VERSION ""

NS_ :

BS_:

BU_:

BO_ 873 APP_warningMatrix1: 8 Vector__XXX
 SG_ APP_w106_torsionBarOffset : 41|1@1+ (1,0) [0|0] "" Vector__XXX
 SG_ APP_w105_DEPRECATED : 40|1@1+ (1,0) [0|0] "" Vector__XXX
 SG_ APP_w104_DEPRECATED : 39|1@1+ (1,0) [0|0] "" Vector__XXX
 SG_ APP_w103_robExperimentalAEB : 38|1@1+ (1,0) [0|0] "" Vector__XXX
 SG_ APP_w102_DEPRECATED : 37|1@1+ (1,0) [0|0] "" Vector__XXX
 SG_ APP_w101_DEPRECATED : 36|1@1+ (1,0) [0|0] "" Vector__XXX
 SG_ APP_w100_DEPRECATED : 35|1@1+ (1,0) [0|0] "" Vector__XXX
 SG_ APP_w099_DEPRECATED : 34|1@1+ (1,0) [0|0] "" Vector__XXX
 SG_ APP_w098_DEPRECATED : 33|1@1+ (1,0) [0|0] "" Vector__XXX
 SG_ APP_w097_DEPRECATED : 32|1@1+ (1,0) [0|0] "" Vector__XXX
 SG_ APP_w096_DEPRECATED : 31|1@1+ (1,0) [0|0] "" Vector__XXX
 SG_ APP_w095_DEPRECATED : 30|1@1+ (1,0) [0|0] "" Vector__XXX
 SG_ APP_w094_DEPRECATED : 29|1@1+ (1,0) [0|0] "" Vector__XXX
 SG_ APP_w093_DEPRECATED : 28|1@1+ (1,0) [0|0] "" Vector__XXX
 SG_ APP_w092_DEPRECATED : 27|1@1+ (1,0) [0|0] "" Vector__XXX
 SG_ APP_w091_DEPRECATED : 26|1@1+ (1,0) [0|0] "" Vector__XXX
 SG_ APP_w090_DEPRECATED : 25|1@1+ (1,0) [0|0] "" Vector__XXX
 SG_ APP_w089_DEPRECATED : 24|1@1+ (1,0) [0|0] "" Vector__XXX
 SG_ APP_w088_DEPRECATED : 23|1@1+ (1,0) [0|0] "" Vector__XXX
 SG_ APP_w087_DEPRECATED : 22|1@1+ (1,0) [0|0] "" Vector__XXX
 SG_ APP_w086_robCollision : 21|1@1+ (1,0) [0|0] "" Vector__XXX
 SG_ APP_w085_pmmSteering : 20|1@1+ (1,0) [0|0] "" Vector__XXX
 SG_ APP_w084_pmmIPSO : 19|1@1+ (1,0) [0|0] "" Vector__XXX
 SG_ APP_w083_inPathRADObject : 18|1@1+ (1,0) [0|0] "" Vector__XXX
 SG_ APP_w082_inPathFSviolation : 17|1@1+ (1,0) [0|0] "" Vector__XXX
 SG_ APP_w081_pmmActiveBraking : 16|1@1+ (1,0) [0|0] "" Vector__XXX
 SG_ APP_w080_accFailedActivation : 15|1@1+ (1,0) [0|0] "" Vector__XXX
 SG_ APP_w079_edrAvailable : 14|1@1+ (1,0) [0|0] "" Vector__XXX
 SG_ APP_w078_pmmActive2 : 13|1@1+ (1,0) [0|0] "" Vector__XXX
 SG_ APP_w077_pmmActive : 12|1@1+ (1,0) [0|0] "" Vector__XXX
 SG_ APP_w076_mobilEyeSetC : 11|1@1+ (1,0) [0|0] "" Vector__XXX
 SG_ APP_w075_scMia : 10|1@1+ (1,0) [0|0] "" Vector__XXX
 SG_ APP_w074_inPathStationaryObst : 9|1@1+ (1,0) [0|0] "" Vector__XXX
 SG_ APP_w073_issueEscalatedLDW : 8|1@1+ (1,0) [0|0] "" Vector__XXX
 SG_ APP_w072_selfparkComplete : 7|1@1+ (1,0) [0|0] "" Vector__XXX
 SG_ APP_w071_selfparkStarted : 6|1@1+ (1,0) [0|0] "" Vector__XXX
 SG_ APP_w070_apcIncompleteCal : 5|1@1+ (1,0) [0|0] "" Vector__XXX
 SG_ APP_w069_apcSpaceMasked : 4|1@1+ (1,0) [0|0] "" Vector__XXX
 SG_ APP_w068_vlInconsistency : 3|1@1+ (1,0) [0|0] "" Vector__XXX
 SG_ APP_w067_steeringAlignment : 2|1@1+ (1,0) [0|0] "" Vector__XXX
 SG_ APP_w066_deserializerLockLost : 1|1@1+ (1,0) [0|0] "" Vector__XXX
 SG_ APP_w065_deserializerOvercurrent : 0|1@1+ (1,0) [0|0] "" Vector__XXX

BO_ 876 APS_warningMatrix1: 8 Vector__XXX
 SG_ APS_w106_torsionBarOffset : 41|1@1+ (1,0) [0|0] "" Vector__XXX
 SG_ APS_w105_DEPRECATED : 40|1@1+ (1,0) [0|0] "" Vector__XXX
 SG_ APS_w104_DEPRECATED : 39|1@1+ (1,0) [0|0] "" Vector__XXX
 SG_ APS_w103_robExperimentalAEB : 38|1@1+ (1,0) [0|0] "" Vector__XXX
 SG_ APS_w102_DEPRECATED : 37|1@1+ (1,0) [0|0] "" Vector__XXX
 SG_ APS_w101_DEPRECATED : 36|1@1+ (1,0) [0|0] "" Vector__XXX
 SG_ APS_w100_DEPRECATED : 35|1@1+ (1,0) [0|0] "" Vector__XXX
 SG_ APS_w099_DEPRECATED : 34|1@1+ (1,0) [0|0] "" Vector__XXX
 SG_ APS_w098_DEPRECATED : 33|1@1+ (1,0) [0|0] "" Vector__XXX
 SG_ APS_w097_DEPRECATED : 32|1@1+ (1,0) [0|0] "" Vector__XXX
 SG_ APS_w096_DEPRECATED : 31|1@1+ (1,0) [0|0] "" Vector__XXX
 SG_ APS_w095_DEPRECATED : 30|1@1+ (1,0) [0|0] "" Vector__XXX
 SG_ APS_w094_DEPRECATED : 29|1@1+ (1,0) [0|0] "" Vector__XXX
 SG_ APS_w093_DEPRECATED : 28|1@1+ (1,0) [0|0] "" Vector__XXX
 SG_ APS_w092_DEPRECATED : 27|1@1+ (1,0) [0|0] "" Vector__XXX
 SG_ APS_w091_DEPRECATED : 26|1@1+ (1,0) [0|0] "" Vector__XXX
 SG_ APS_w090_DEPRECATED : 25|1@1+ (1,0) [0|0] "" Vector__XXX
 SG_ APS_w089_DEPRECATED : 24|1@1+ (1,0) [0|0] "" Vector__XXX
 SG_ APS_w088_DEPRECATED : 23|1@1+ (1,0) [0|0] "" Vector__XXX
 SG_ APS_w087_DEPRECATED : 22|1@1+ (1,0) [0|0] "" Vector__XXX
 SG_ APS_w086_robCollision : 21|1@1+ (1,0) [0|0] "" Vector__XXX
 SG_ APS_w085_pmmSteering : 20|1@1+ (1,0) [0|0] "" Vector__XXX
 SG_ APS_w084_pmmIPSO : 19|1@1+ (1,0) [0|0] "" Vector__XXX
 SG_ APS_w083_inPathRADObject : 18|1@1+ (1,0) [0|0] "" Vector__XXX
 SG_ APS_w082_inPathFSviolation : 17|1@1+ (1,0) [0|0] "" Vector__XXX
 SG_ APS_w081_pmmActiveBraking : 16|1@1+ (1,0) [0|0] "" Vector__XXX
 SG_ APS_w080_accFailedActivation : 15|1@1+ (1,0) [0|0] "" Vector__XXX
 SG_ APS_w079_edrAvailable : 14|1@1+ (1,0) [0|0] "" Vector__XXX
 SG_ APS_w078_pmmActive2 : 13|1@1+ (1,0) [0|0] "" Vector__XXX
 SG_ APS_w077_pmmActive : 12|1@1+ (1,0) [0|0] "" Vector__XXX
 SG_ APS_w076_mobilEyeSetC : 11|1@1+ (1,0) [0|0] "" Vector__XXX
 SG_ APS_w075_scMia : 10|1@1+ (1,0) [0|0] "" Vector__XXX
 SG_ APS_w074_inPathStationaryObst : 9|1@1+ (1,0) [0|0] "" Vector__XXX
 SG_ APS_w073_issueEscalatedLDW : 8|1@1+ (1,0) [0|0] "" Vector__XXX
 SG_ APS_w072_selfparkComplete : 7|1@1+ (1,0) [0|0] "" Vector__XXX
 SG_ APS_w071_selfparkStarted : 6|1@1+ (1,0) [0|0] "" Vector__XXX
 SG_ APS_w070_apcIncompleteCal : 5|1@1+ (1,0) [0|0] "" Vector__XXX
 SG_ APS_w069_apcSpaceMasked : 4|1@1+ (1,0) [0|0] "" Vector__XXX
 SG_ APS_w068_vlInconsistency : 3|1@1+ (1,0) [0|0] "" Vector__XXX
 SG_ APS_w067_steeringAlignment : 2|1@1+ (1,0) [0|0] "" Vector__XXX
 SG_ APS_w066_deserializerLockLost : 1|1@1+ (1,0) [0|0] "" Vector__XXX
 SG_ APS_w065_deserializerOvercurrent : 0|1@1+ (1,0) [0|0] "" Vector__XXX

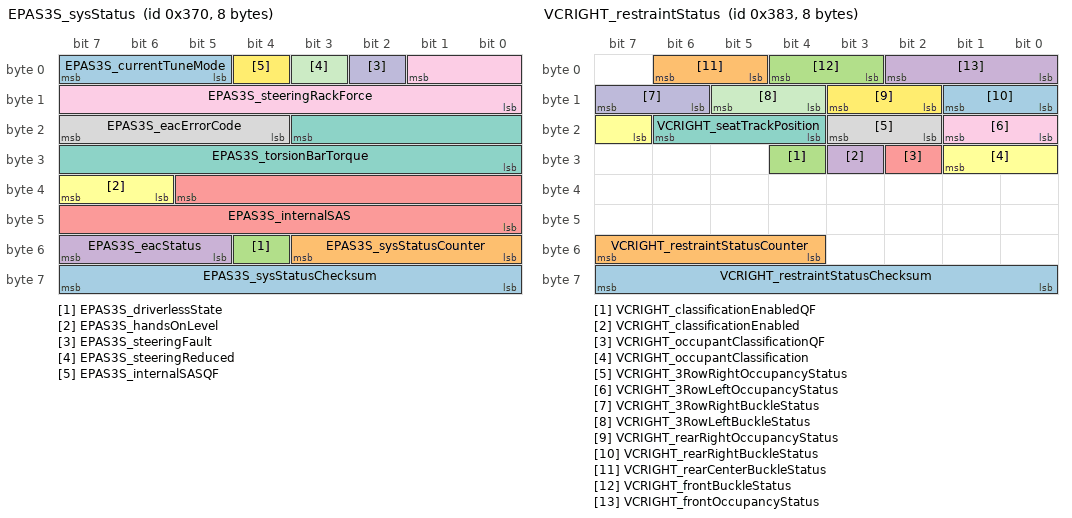
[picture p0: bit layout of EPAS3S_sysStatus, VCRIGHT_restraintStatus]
BO_ 880 EPAS3S_sysStatus: 8 Vector__XXX
 SG_ EPAS3S_sysStatusChecksum : 63|8@0+ (1,0) [0|0] "" Vector__XXX
 SG_ EPAS3S_sysStatusCounter : 51|4@0+ (1,0) [0|0] "" Vector__XXX
 SG_ EPAS3S_driverlessState : 52|1@0+ (1,0) [0|0] "" Vector__XXX
 SG_ EPAS3S_eacStatus : 55|3@0+ (1,0) [0|0] "" Vector__XXX
 SG_ EPAS3S_internalSAS : 37|14@0+ (0.1,-819.2) [0|0] "" Vector__XXX
 SG_ EPAS3S_handsOnLevel : 39|2@0+ (1,0) [0|0] "" Vector__XXX
 SG_ EPAS3S_torsionBarTorque : 19|12@0+ (0.01,-20.5) [0|0] "" Vector__XXX
 SG_ EPAS3S_eacErrorCode : 23|4@0+ (1,0) [0|0] "" Vector__XXX
 SG_ EPAS3S_steeringRackForce : 1|10@0+ (50,-25575) [0|0] "" Vector__XXX
 SG_ EPAS3S_steeringFault : 2|1@0+ (1,0) [0|0] "" Vector__XXX
 SG_ EPAS3S_steeringReduced : 3|1@0+ (1,0) [0|0] "" Vector__XXX
 SG_ EPAS3S_internalSASQF : 4|1@0+ (1,0) [0|0] "" Vector__XXX
 SG_ EPAS3S_currentTuneMode : 7|3@0+ (1,0) [0|0] "" Vector__XXX

BO_ 899 VCRIGHT_restraintStatus: 8 Vector__XXX
 SG_ VCRIGHT_restraintStatusChecksum : 56|8@1+ (1,0) [0|0] "" Vector__XXX
 SG_ VCRIGHT_restraintStatusCounter : 52|4@1+ (1,0) [0|0] "" Vector__XXX
 SG_ VCRIGHT_classificationEnabledQF : 28|1@1+ (1,0) [0|0] "" Vector__XXX
 SG_ VCRIGHT_classificationEnabled : 27|1@1+ (1,0) [0|0] "" Vector__XXX
 SG_ VCRIGHT_occupantClassificationQF : 26|1@1+ (1,0) [0|0] "" Vector__XXX
 SG_ VCRIGHT_occupantClassification : 23|3@1+ (1,0) [0|0] "" Vector__XXX
 SG_ VCRIGHT_seatTrackPosition : 20|3@1+ (1,0) [0|0] "" Vector__XXX
 SG_ VCRIGHT_3RowRightOccupancyStatus : 18|2@1+ (1,0) [0|0] "" Vector__XXX
 SG_ VCRIGHT_3RowLeftOccupancyStatus : 16|2@1+ (1,0) [0|0] "" Vector__XXX
 SG_ VCRIGHT_3RowRightBuckleStatus : 14|2@1+ (1,0) [0|0] "" Vector__XXX
 SG_ VCRIGHT_3RowLeftBuckleStatus : 12|2@1+ (1,0) [0|0] "" Vector__XXX
 SG_ VCRIGHT_rearRightOccupancyStatus : 10|2@1+ (1,0) [0|0] "" Vector__XXX
 SG_ VCRIGHT_rearRightBuckleStatus : 8|2@1+ (1,0) [0|0] "" Vector__XXX
 SG_ VCRIGHT_rearCenterBuckleStatus : 5|2@1+ (1,0) [0|0] "" Vector__XXX
 SG_ VCRIGHT_frontBuckleStatus : 3|2@1+ (1,0) [0|0] "" Vector__XXX
 SG_ VCRIGHT_frontOccupancyStatus : 0|3@1+ (1,0) [0|0] "" Vector__XXX

BO_ 905 DAS_status2: 8 CH
 SG_ DAS_status2Checksum : 56|8@1+ (1,0) [0|0] ""  X
 SG_ DAS_status2Counter : 52|4@1+ (1,0) [0|0] ""  X
 SG_ DAS_longCollisionWarning : 48|4@1+ (1,0) [0|0] ""  X
 SG_ DAS_ppOffsetDesiredRamp : 40|8@1+ (0.01,-1.28) [0|0] "m"  X
 SG_ DAS_driverInteractionLevel : 38|2@1+ (1,0) [0|0] ""  X
 SG_ DAS_robState : 36|2@1+ (1,0) [0|0] ""  X
 SG_ DAS_radarTelemetry : 34|2@1+ (1,0) [0|0] ""  X
 SG_ DAS_lssState : 31|3@1+ (1,0) [0|0] ""  X
 SG_ DAS_ACC_report : 26|5@1+ (1,0) [0|0] ""  X
 SG_ DAS_pmmCameraFaultReason : 24|2@1+ (1,0) [0|0] ""  X
 SG_ DAS_pmmSysFaultReason : 21|3@1+ (1,0) [0|0] ""  X
 SG_ DAS_pmmRadarFaultReason : 19|2@1+ (1,0) [0|0] ""  X
 SG_ DAS_pmmUltrasonicsFaultReason : 16|3@1+ (1,0) [0|0] ""  X
 SG_ DAS_activationFailureStatus : 14|2@1+ (1,0) [0|0] ""  X
 SG_ DAS_pmmLoggingRequest : 13|1@1+ (1,0) [0|0] ""  X
 SG_ DAS_pmmObstacleSeverity : 10|3@1+ (1,0) [0|0] ""  X
 SG_ DAS_accSpeedLimit : 0|10@1+ (0.2,0) [0|0] "mph"  X

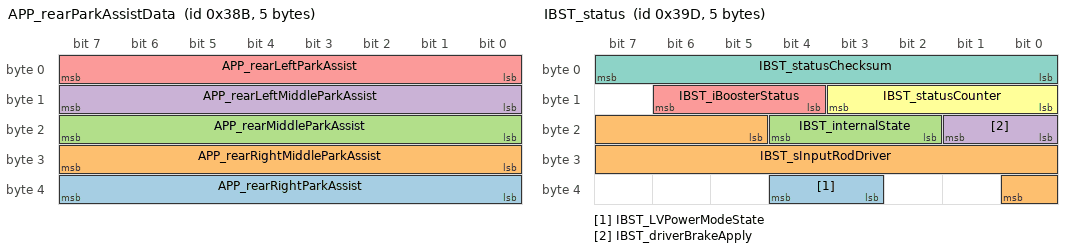
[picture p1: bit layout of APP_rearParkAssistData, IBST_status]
BO_ 907 APP_rearParkAssistData: 5 Vector__XXX
 SG_ APP_rearRightParkAssist : 32|8@1+ (1,0) [0|0] "" Vector__XXX
 SG_ APP_rearRightMiddleParkAssist : 24|8@1+ (1,0) [0|0] "" Vector__XXX
 SG_ APP_rearMiddleParkAssist : 16|8@1+ (1,0) [0|0] "" Vector__XXX
 SG_ APP_rearLeftMiddleParkAssist : 8|8@1+ (1,0) [0|0] "" Vector__XXX
 SG_ APP_rearLeftParkAssist : 0|8@1+ (1,0) [0|0] "" Vector__XXX

BO_ 917 OCS1P_alertMatrix: 8 Vector__XXX
 SG_ OCS1P_w156_seatbeltReminderUnavailable m2 : 39|1@1+ (1,0) [0|0] "" Vector__XXX
 SG_ OCS1P_w155_rbExit2Exited2 m2 : 38|1@1+ (1,0) [0|0] "" Vector__XXX
 SG_ OCS1P_w154_rbExit2Exited1 m2 : 37|1@1+ (1,0) [0|0] "" Vector__XXX
 SG_ OCS1P_w153_rbExit1Exited m2 : 36|1@1+ (1,0) [0|0] "" Vector__XXX
 SG_ OCS1P_w152_rbExit1Triggered m2 : 35|1@1+ (1,0) [0|0] "" Vector__XXX
 SG_ OCS1P_w151_rbEntryExited m2 : 34|1@1+ (1,0) [0|0] "" Vector__XXX
 SG_ OCS1P_w150_rbEntryTriggered m2 : 33|1@1+ (1,0) [0|0] "" Vector__XXX
 SG_ OCS1P_w148_classificationMismatch m2 : 31|1@1+ (1,0) [0|0] "" Vector__XXX
 SG_ OCS1P_w145_rebaselineTriggered m2 : 28|1@1+ (1,0) [0|0] "" Vector__XXX
 SG_ OCS1P_w144_mismatchCarRegion m2 : 27|1@1+ (1,0) [0|0] "" Vector__XXX
 SG_ OCS1P_w143_mismatchPassAirbag m2 : 26|1@1+ (1,0) [0|0] "" Vector__XXX
 SG_ OCS1P_w142_tempHumidityInvalid m2 : 25|1@1+ (1,0) [0|0] "" Vector__XXX
 SG_ OCS1P_w141_humidityInvalidCalib m2 : 24|1@1+ (1,0) [0|0] "" Vector__XXX
 SG_ OCS1P_w140_tempInvalidCalib m2 : 23|1@1+ (1,0) [0|0] "" Vector__XXX
 SG_ OCS1P_w139_seatbackSelfDutyHigh m2 : 22|1@1+ (1,0) [0|0] "" Vector__XXX
 SG_ OCS1P_w138_seatbackSelfDutyLow m2 : 21|1@1+ (1,0) [0|0] "" Vector__XXX
 SG_ OCS1P_w137_cushionSelfDutyHigh m2 : 20|1@1+ (1,0) [0|0] "" Vector__XXX
 SG_ OCS1P_w136_cushionSelfDutyLow m2 : 19|1@1+ (1,0) [0|0] "" Vector__XXX
 SG_ OCS1P_w015_NVMMAlert m0 : 18|1@1+ (1,0) [0|0] "" Vector__XXX
 SG_ OCS1P_w135_tempNoCalib m2 : 18|1@1+ (1,0) [0|0] "" Vector__XXX
 SG_ OCS1P_w134_uninitializedCalib m2 : 17|1@1+ (1,0) [0|0] "" Vector__XXX
 SG_ OCS1P_w133_sandwichBadCalib m2 : 16|1@1+ (1,0) [0|0] "" Vector__XXX
 SG_ OCS1P_w132_seatbackSelfNoCalib m2 : 15|1@1+ (1,0) [0|0] "" Vector__XXX
 SG_ OCS1P_w131_cushionSelfNoCalib m2 : 14|1@1+ (1,0) [0|0] "" Vector__XXX
 SG_ OCS1P_w130_sandwichNoCalib m2 : 13|1@1+ (1,0) [0|0] "" Vector__XXX
 SG_ OCS1P_w129_seatbackSelfShort m2 : 12|1@1+ (1,0) [0|0] "" Vector__XXX
 SG_ OCS1P_w128_seatbackSelfLow m2 : 11|1@1+ (1,0) [0|0] "" Vector__XXX
 SG_ OCS1P_w127_seatbackSelfOpen m2 : 10|1@1+ (1,0) [0|0] "" Vector__XXX
 SG_ OCS1P_w126_cushionSelfShort m2 : 9|1@1+ (1,0) [0|0] "" Vector__XXX
 SG_ OCS1P_w125_cushionSelfLow m2 : 8|1@1+ (1,0) [0|0] "" Vector__XXX
 SG_ OCS1P_w124_cushionSelfOpen m2 : 7|1@1+ (1,0) [0|0] "" Vector__XXX
 SG_ OCS1P_w123_sandwichShort m2 : 6|1@1+ (1,0) [0|0] "" Vector__XXX
 SG_ OCS1P_w122_sandwichLow m2 : 5|1@1+ (1,0) [0|0] "" Vector__XXX
 SG_ OCS1P_w121_sandwichOpen m2 : 4|1@1+ (1,0) [0|0] "" Vector__XXX
 SG_ OCS1P_matrixIndex M : 0|4@1+ (1,0) [0|0] "" Vector__XXX

BO_ 921 DAS_status: 8 Vector__XXX
 SG_ DAS_statusChecksum : 56|8@1+ (1,0) [0|0] "" Vector__XXX
 SG_ DAS_statusCounter : 52|4@1+ (1,0) [0|0] "" Vector__XXX
 SG_ DAS_summonAvailable : 51|1@1+ (1,0) [0|0] "" Vector__XXX
 SG_ DAS_autoLaneChangeState : 46|5@1+ (1,0) [0|0] "" Vector__XXX
 SG_ DAS_autopilotHandsOnState : 42|4@1+ (1,0) [0|0] "" Vector__XXX
 SG_ DAS_fleetSpeedState : 40|2@1+ (1,0) [0|0] "" Vector__XXX
 SG_ DAS_laneDepartureWarning : 37|3@1+ (1,0) [0|0] "" Vector__XXX
 SG_ DAS_sideCollisionInhibit : 36|1@1+ (1,0) [0|0] "" Vector__XXX
 SG_ DAS_sideCollisionWarning : 34|2@1+ (1,0) [0|0] "" Vector__XXX
 SG_ DAS_sideCollisionAvoid : 32|2@1+ (1,0) [0|0] "" Vector__XXX
 SG_ DAS_lssState : 29|3@1+ (1,0) [0|0] "" Vector__XXX
 SG_ DAS_summonRvsLeashReached : 28|1@1+ (1,0) [0|0] "" Vector__XXX
 SG_ DAS_summonFwdLeashReached : 27|1@1+ (1,0) [0|0] "" Vector__XXX
 SG_ DAS_autoparkActive : 26|1@1+ (1,0) [0|0] "" Vector__XXX
 SG_ DAS_autoParked : 25|1@1+ (1,0) [0|0] "" Vector__XXX
 SG_ DAS_autoparkReady : 24|1@1+ (1,0) [0|0] "" Vector__XXX
 SG_ DAS_forwardCollisionWarning : 22|2@1+ (1,0) [0|0] "" Vector__XXX
 SG_ DAS_heaterState : 21|1@1+ (1,0) [0|0] "" Vector__XXX
 SG_ DAS_visionOnlySpeedLimit : 16|5@1+ (5,0) [0|0] "" Vector__XXX
 SG_ DAS_summonClearedGate : 15|1@1+ (1,0) [0|0] "" Vector__XXX
 SG_ DAS_summonObstacle : 14|1@1+ (1,0) [0|0] "" Vector__XXX
 SG_ DAS_suppressSpeedWarning : 13|1@1+ (1,0) [0|0] "" Vector__XXX
 SG_ DAS_fusedSpeedLimit : 8|5@1+ (5,0) [0|0] "" Vector__XXX
 SG_ DAS_blindSpotRearRight : 6|2@1+ (1,0) [0|0] "" Vector__XXX
 SG_ DAS_blindSpotRearLeft : 4|2@1+ (1,0) [0|0] "" Vector__XXX
 SG_ DAS_autopilotState : 0|4@1+ (1,0) [0|0] "" Vector__XXX

BO_ 925 IBST_status: 5 Vector__XXX
 SG_ IBST_LVPowerModeState : 35|2@1+ (1,0) [0|0] "" Vector__XXX
 SG_ IBST_sInputRodDriver : 21|12@1+ (0.015625,-5) [0|0] "" Vector__XXX
 SG_ IBST_internalState : 18|3@1+ (1,0) [0|0] "" Vector__XXX
 SG_ IBST_driverBrakeApply : 16|2@1+ (1,0) [0|0] "" Vector__XXX
 SG_ IBST_iBoosterStatus : 12|3@1+ (1,0) [0|0] "" Vector__XXX
 SG_ IBST_statusCounter : 8|4@1+ (1,0) [0|0] "" Vector__XXX
 SG_ IBST_statusChecksum : 0|8@1+ (1,0) [0|0] "" Vector__XXX

BO_ 939 APP_driverMonitorStatus: 5 Vector__XXX
 SG_ APP_ADDWSystemStatus : 28|2@1+ (1,0) [0|0] "" Vector__XXX
 SG_ APP_cabinLowLuxHyst : 27|1@1+ (1,0) [0|0] "" Vector__XXX
 SG_ APP_cabinCamDarkHyst : 26|1@1+ (1,0) [0|0] "" Vector__XXX
 SG_ APP_handsOnInputRequired : 25|1@1+ (1,0) [0|0] "" Vector__XXX
 SG_ APP_driverSeatUnoccupied : 24|1@1+ (1,0) [0|0] "" Vector__XXX
 SG_ APP_driverHandsNotReady : 23|1@1+ (1,0) [0|0] "" Vector__XXX
 SG_ APP_driverLowEyeVisibility : 22|1@1+ (1,0) [0|0] "" Vector__XXX
 SG_ APP_driverLeaningBack : 21|1@1+ (1,0) [0|0] "" Vector__XXX
 SG_ APP_cabinCamInconsistent : 20|1@1+ (1,0) [0|0] "" Vector__XXX
 SG_ APP_cabinLowLux : 19|1@1+ (1,0) [0|0] "" Vector__XXX
 SG_ APP_driverSunglassesUseHyst : 18|1@1+ (1,0) [0|0] "" Vector__XXX
 SG_ APP_driverHeadCappedHyst : 17|1@1+ (1,0) [0|0] "" Vector__XXX
 SG_ APP_driverLowNominal : 16|1@1+ (1,0) [0|0] "" Vector__XXX
 SG_ APP_driverStateUnknownHyst : 15|1@1+ (1,0) [0|0] "" Vector__XXX
 SG_ APP_driverNotLively : 14|1@1+ (1,0) [0|0] "" Vector__XXX
 SG_ APP_driverStateUnknown : 13|1@1+ (1,0) [0|0] "" Vector__XXX
 SG_ APP_cabinCamDark : 12|1@1+ (1,0) [0|0] "" Vector__XXX
 SG_ APP_cabinCamBlinded : 11|1@1+ (1,0) [0|0] "" Vector__XXX
 SG_ APP_handsOnDetectedSource : 8|3@1+ (1,0) [0|0] "" Vector__XXX
 SG_ APP_handsOnDetected : 5|1@1+ (1,0) [0|0] "" Vector__XXX
 SG_ APP_attnBasedDriverMonitorOn : 4|1@1+ (1,0) [0|0] "" Vector__XXX
 SG_ APP_attnMonitorVersion : 1|3@1+ (1,0) [0|0] "" Vector__XXX
 SG_ APP_cabinCamTelemetryOn : 0|1@1+ (1,0) [0|0] "" Vector__XXX

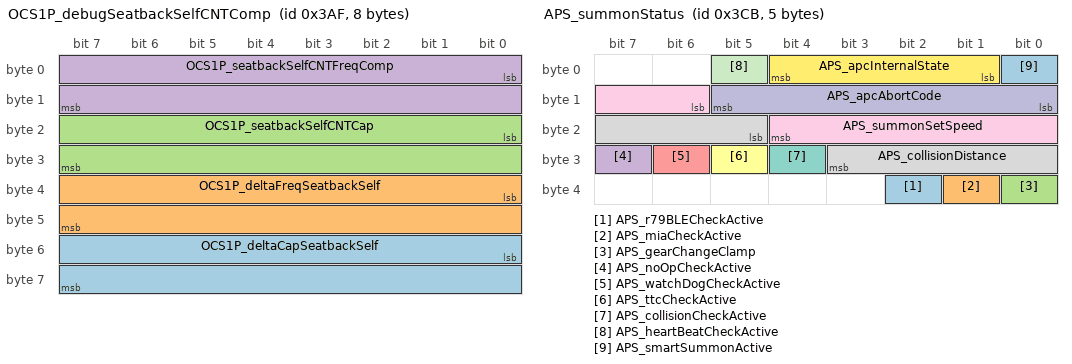
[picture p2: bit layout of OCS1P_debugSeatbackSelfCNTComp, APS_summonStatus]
BO_ 943 OCS1P_debugSeatbackSelfCNTComp: 8 Vector__XXX
 SG_ OCS1P_deltaCapSeatbackSelf : 48|16@1- (0.0025,0) [0|0] "" Vector__XXX
 SG_ OCS1P_deltaFreqSeatbackSelf : 32|16@1- (1,0) [0|0] "" Vector__XXX
 SG_ OCS1P_seatbackSelfCNTCap : 16|16@1+ (0.005,0) [0|0] "" Vector__XXX
 SG_ OCS1P_seatbackSelfCNTFreqComp : 0|16@1+ (1,0) [0|0] "" Vector__XXX

BO_ 947 UI_vehicleControl2: 8 Vector__XXX
 SG_ UI_sleepFeature2 : 63|1@1+ (1,0) [0|0] "" Vector__XXX
 SG_ UI_silentAlarm : 61|1@1+ (1,0) [0|0] "" Vector__XXX
 SG_ UI_saveTireConfigReq : 60|1@1+ (1,0) [0|0] "" Vector__XXX
 SG_ UI_tireSeason : 59|1@1+ (1,0) [0|0] "" Vector__XXX
 SG_ UI_wiperHeaterReq : 57|1@1+ (1,0) [0|0] "" Vector__XXX
 SG_ UI_frontLeftSeatAutoClimateReq : 56|1@1+ (1,0) [0|0] "" Vector__XXX
 SG_ UI_dcr12VThreshold : 52|4@1+ (1,0) [0|0] "" Vector__XXX
 SG_ UI_sleepFeature1 : 51|1@1+ (1,0) [0|0] "" Vector__XXX
 SG_ UI_frontRightSeatAutoClimateReq : 39|1@1+ (1,0) [0|0] "" Vector__XXX
 SG_ UI_disableHorn : 34|1@1+ (1,0) [0|0] "" Vector__XXX
 SG_ UI_steeringWheelHeatReq : 33|1@1+ (1,0) [0|0] "" Vector__XXX
 SG_ UI_WC3UpdateInhibit : 32|1@1+ (1,0) [0|0] "" Vector__XXX
 SG_ UI_conditionalLoggingEnabledVCSEC : 31|1@1+ (1,0) [0|0] "" Vector__XXX
 SG_ UI_virtualPitchSensorOverrideOKForAim : 30|1@1+ (1,0) [0|0] "" Vector__XXX
 SG_ UI_autoRollWindowsOnLockEnable : 29|1@1+ (1,0) [0|0] "" Vector__XXX
 SG_ UI_shorted12VCellTestMode : 27|2@1+ (1,0) [0|0] "" Vector__XXX
 SG_ UI_autopilotPowerStateRequest : 25|2@1+ (1,0) [0|0] "" Vector__XXX
 SG_ UI_coastDownMode : 24|1@1+ (1,0) [0|0] "" Vector__XXX
 SG_ UI_batteryPreconditioningRequest : 23|1@1+ (1,0) [0|0] "" Vector__XXX
 SG_ UI_keepAutopilotAwake : 22|1@1+ (1,0) [0|0] "" Vector__XXX
 SG_ UI_pairKeyQRCodeDisplaying : 21|1@1+ (1,0) [0|0] "" Vector__XXX
 SG_ UI_BLEPushNotificationRequest : 20|1@1+ (1,0) [0|0] "" Vector__XXX
 SG_ UI_freeRollModeRequest : 19|1@1+ (1,0) [0|0] "" Vector__XXX
 SG_ UI_displayOnForUser : 18|1@1+ (1,0) [0|0] "" Vector__XXX
 SG_ UI_summonState : 16|2@1+ (1,0) [0|0] "" Vector__XXX
 SG_ UI_VCLEFTFeature1 : 15|1@1+ (1,0) [0|0] "" Vector__XXX
 SG_ UI_VCSECFeature1 : 14|1@1+ (1,0) [0|0] "" Vector__XXX
 SG_ UI_alarmTriggerRequest : 13|1@1+ (1,0) [0|0] "" Vector__XXX
 SG_ UI_readyToAddKey : 12|1@1+ (1,0) [0|0] "" Vector__XXX
 SG_ UI_lightSwitch : 9|3@1+ (1,0) [0|0] "" Vector__XXX
 SG_ UI_disableMirrorAutoDim : 8|1@1+ (1,0) [0|0] "" Vector__XXX
 SG_ UI_PINToDrivePassed : 7|1@1+ (1,0) [0|0] "" Vector__XXX
 SG_ UI_PINToDriveEnabled : 6|1@1+ (1,0) [0|0] "" Vector__XXX
 SG_ UI_locksPanelActive : 5|1@1+ (1,0) [0|0] "" Vector__XXX
 SG_ UI_soundHornOnLock : 4|1@1+ (1,0) [0|0] "" Vector__XXX
 SG_ UI_WCUpdateInhibit : 3|1@1+ (1,0) [0|0] "" Vector__XXX
 SG_ UI_UMCUpdateInhibit : 2|1@1+ (1,0) [0|0] "" Vector__XXX
 SG_ UI_trunkRequest : 1|1@1+ (1,0) [0|0] "" Vector__XXX
 SG_ UI_gloveboxRequest : 0|1@1+ (1,0) [0|0] "" Vector__XXX

BO_ 952 UI_tpmsRCPsetting: 4 Vector__XXX
 SG_ UI_setRCPRear : 24|8@1+ (0.025,0) [0|0] "" Vector__XXX
 SG_ UI_setRCPFront : 16|8@1+ (0.025,0) [0|0] "" Vector__XXX

BO_ 962 VCLEFT_switchStatus: 8 Vector__XXX
 SG_ VCLEFT_frontSeatResistiveOccupancy m1 : 62|2@1+ (1,0) [0|0] "" Vector__XXX
 SG_ VCLEFT_rearCenterBuckleSwitch m0 : 62|2@1+ (1,0) [0|0] "" Vector__XXX
 SG_ VCLEFT_rearHVACButtonPressed m0 : 61|1@1+ (1,0) [0|0] "" Vector__XXX
 SG_ VCLEFT_brakePressed m0 : 60|1@1+ (1,0) [0|0] "" Vector__XXX
 SG_ VCLEFT_rearRightOccupancySwitch m0 : 58|2@1+ (1,0) [0|0] "" Vector__XXX
 SG_ VCLEFT_rearLeftOccupancySwitch m0 : 56|2@1+ (1,0) [0|0] "" Vector__XXX
 SG_ VCLEFT_rearCenterOccupancySwitch m0 : 54|2@1+ (1,0) [0|0] "" Vector__XXX
 SG_ VCLEFT_rearLeftBuckleSwitch m0 : 52|2@1+ (1,0) [0|0] "" Vector__XXX
 SG_ VCLEFT_frontOccupancySwitch m0 : 50|2@1+ (1,0) [0|0] "" Vector__XXX
 SG_ VCLEFT_frontBuckleSwitch m0 : 48|2@1+ (1,0) [0|0] "" Vector__XXX
 SG_ VCLEFT_btnWindowSwPackAutoDownRR m0 : 47|1@1+ (1,0) [0|0] "" Vector__XXX
 SG_ VCLEFT_btnWindowSwPackDownRR m0 : 46|1@1+ (1,0) [0|0] "" Vector__XXX
 SG_ VCLEFT_btnWindowSwPackAutoUpRR m0 : 45|1@1+ (1,0) [0|0] "" Vector__XXX
 SG_ VCLEFT_btnWindowSwPackUpRR m0 : 44|1@1+ (1,0) [0|0] "" Vector__XXX
 SG_ VCLEFT_2RowSeatBackrestFoldSwitch m1 : 43|1@1+ (1,0) [0|0] "" Vector__XXX
 SG_ VCLEFT_btnWindowSwPackAutoDownRF m0 : 43|1@1+ (1,0) [0|0] "" Vector__XXX
 SG_ VCLEFT_btnWindowSwPackDownRF m0 : 42|1@1+ (1,0) [0|0] "" Vector__XXX
 SG_ VCLEFT_swcRightDoublePress m1 : 42|1@1+ (1,0) [0|0] "" Vector__XXX
 SG_ VCLEFT_btnWindowSwPackAutoUpRF m0 : 41|1@1+ (1,0) [0|0] "" Vector__XXX
 SG_ VCLEFT_swcLeftDoublePress m1 : 41|1@1+ (1,0) [0|0] "" Vector__XXX
 SG_ VCLEFT_2RowSeatBothFoldFlatSwitch m1 : 40|1@1+ (1,0) [0|0] "" Vector__XXX
 SG_ VCLEFT_btnWindowSwPackUpRF m0 : 40|1@1+ (1,0) [0|0] "" Vector__XXX
 SG_ VCLEFT_2RowSeatRightFoldFlatSwitch m1 : 39|1@1+ (1,0) [0|0] "" Vector__XXX
 SG_ VCLEFT_btnWindowSwPackAutoDownLR m0 : 39|1@1+ (1,0) [0|0] "" Vector__XXX
 SG_ VCLEFT_2RowSeatLeftFoldFlatSwitch m1 : 38|1@1+ (1,0) [0|0] "" Vector__XXX
 SG_ VCLEFT_btnWindowSwPackDownLR m0 : 38|1@1+ (1,0) [0|0] "" Vector__XXX
 SG_ VCLEFT_2RowSeatCenterSwitch m1 : 37|1@1+ (1,0) [0|0] "" Vector__XXX
 SG_ VCLEFT_btnWindowSwPackAutoUpLR m0 : 37|1@1+ (1,0) [0|0] "" Vector__XXX
 SG_ VCLEFT_2RowSeatReclineSwitch m1 : 36|1@1+ (1,0) [0|0] "" Vector__XXX
 SG_ VCLEFT_btnWindowSwPackUpLR m0 : 36|1@1+ (1,0) [0|0] "" Vector__XXX
 SG_ VCLEFT_btnWindowAutoDownLR m1 : 35|1@1+ (1,0) [0|0] "" Vector__XXX
 SG_ VCLEFT_btnWindowSwPackAutoDownLF m0 : 35|1@1+ (1,0) [0|0] "" Vector__XXX
 SG_ VCLEFT_btnWindowDownLR m1 : 34|1@1+ (1,0) [0|0] "" Vector__XXX
 SG_ VCLEFT_btnWindowSwPackDownLF m0 : 34|1@1+ (1,0) [0|0] "" Vector__XXX
 SG_ VCLEFT_btnWindowAutoUpLR m1 : 33|1@1+ (1,0) [0|0] "" Vector__XXX
 SG_ VCLEFT_btnWindowSwPackAutoUpLF m0 : 33|1@1+ (1,0) [0|0] "" Vector__XXX
 SG_ VCLEFT_btnWindowSwPackUpLF m0 : 32|1@1+ (1,0) [0|0] "" Vector__XXX
 SG_ VCLEFT_btnWindowUpLR m1 : 32|1@1+ (1,0) [0|0] "" Vector__XXX
 SG_ VCLEFT_frontSeatLumbarOut m0 : 30|2@1+ (1,0) [0|0] "" Vector__XXX
 SG_ VCLEFT_frontSeatLumbarIn m0 : 28|2@1+ (1,0) [0|0] "" Vector__XXX
 SG_ VCLEFT_frontSeatLumbarUp m0 : 26|2@1+ (1,0) [0|0] "" Vector__XXX
 SG_ VCLEFT_frontSeatLumbarDown m0 : 24|2@1+ (1,0) [0|0] "" Vector__XXX
 SG_ VCLEFT_swcRightScrollTicks m1 : 24|6@1- (1,0) [0|0] "" Vector__XXX
 SG_ VCLEFT_frontSeatBackrestForward m0 : 22|2@1+ (1,0) [0|0] "" Vector__XXX
 SG_ VCLEFT_frontSeatBackrestBack m0 : 20|2@1+ (1,0) [0|0] "" Vector__XXX
 SG_ VCLEFT_frontSeatLiftUp m0 : 18|2@1+ (1,0) [0|0] "" Vector__XXX
 SG_ VCLEFT_frontSeatLiftDown m0 : 16|2@1+ (1,0) [0|0] "" Vector__XXX
 SG_ VCLEFT_swcLeftScrollTicks m1 : 16|6@1- (1,0) [0|0] "" Vector__XXX
 SG_ VCLEFT_frontSeatTiltUp m0 : 14|2@1+ (1,0) [0|0] "" Vector__XXX
 SG_ VCLEFT_swcLeftTiltLeft m1 : 14|2@1+ (1,0) [0|0] "" Vector__XXX
 SG_ VCLEFT_frontSeatTiltDown m0 : 12|2@1+ (1,0) [0|0] "" Vector__XXX
 SG_ VCLEFT_swcRightPressed m1 : 12|2@1+ (1,0) [0|0] "" Vector__XXX
 SG_ VCLEFT_frontSeatTrackForward m0 : 10|2@1+ (1,0) [0|0] "" Vector__XXX
 SG_ VCLEFT_swcRightTiltRight m1 : 10|2@1+ (1,0) [0|0] "" Vector__XXX
 SG_ VCLEFT_frontSeatTrackBack m0 : 8|2@1+ (1,0) [0|0] "" Vector__XXX
 SG_ VCLEFT_swcRightTiltLeft m1 : 8|2@1+ (1,0) [0|0] "" Vector__XXX
 SG_ VCLEFT_rightMirrorTilt m0 : 5|3@1+ (1,0) [0|0] "" Vector__XXX
 SG_ VCLEFT_swcLeftPressed m1 : 5|2@1+ (1,0) [0|0] "" Vector__XXX
 SG_ VCLEFT_brakeSwitchPressed m0 : 4|1@1+ (1,0) [0|0] "" Vector__XXX
 SG_ VCLEFT_hazardButtonPressed m0 : 3|1@1+ (1,0) [0|0] "" Vector__XXX
 SG_ VCLEFT_swcLeftTiltRight m1 : 3|2@1+ (1,0) [0|0] "" Vector__XXX
 SG_ VCLEFT_hornSwitchPressed m0 : 2|1@1+ (1,0) [0|0] "" Vector__XXX
 SG_ VCLEFT_isAlcoholInterlockSet m1 : 2|1@1+ (1,0) [0|0] "" Vector__XXX
 SG_ VCLEFT_switchStatusIndex M : 0|1@1+ (1,0) [0|0] "" Vector__XXX

BO_ 963 VCRIGHT_switchStatus: 8 Vector__XXX
 SG_ VCRIGHT_3RowRightBuckleSwitch m0 : 62|2@1+ (1,0) [0|0] "" Vector__XXX
 SG_ VCRIGHT_3RowLeftBuckleSwitch m0 : 60|2@1+ (1,0) [0|0] "" Vector__XXX
 SG_ VCRIGHT_hvacHeatingAllowedRight m1 : 59|1@1+ (1,0) [0|0] "" Vector__XXX
 SG_ VCRIGHT_3RowRightOccupancySwitch m0 : 58|2@1+ (1,0) [0|0] "" Vector__XXX
 SG_ VCRIGHT_3RowLeftOccupancySwitch m0 : 56|2@1+ (1,0) [0|0] "" Vector__XXX
 SG_ VCRIGHT_frontSeatResistiveOccupancy m1 : 54|2@1+ (1,0) [0|0] "" Vector__XXX
 SG_ VCRIGHT_rearRightOccupancySwitch m0 : 54|2@1+ (1,0) [0|0] "" Vector__XXX
 SG_ VCRIGHT_liftgateShutfaceSwitchPressed m0 : 53|1@1+ (1,0) [0|0] "" Vector__XXX
 SG_ VCRIGHT_btnWindowSwPackAutoDwnRR m0 : 52|1@1+ (1,0) [0|0] "" Vector__XXX
 SG_ VCRIGHT_btnWindowSwPackDownRR m0 : 51|1@1+ (1,0) [0|0] "" Vector__XXX
 SG_ VCRIGHT_btnWindowSwPackAutoUpRR m0 : 50|1@1+ (1,0) [0|0] "" Vector__XXX
 SG_ VCRIGHT_btnWindowSwPackUpRR m0 : 49|1@1+ (1,0) [0|0] "" Vector__XXX
 SG_ VCRIGHT_trunkExtReleasePressed m0 : 48|1@1+ (1,0) [0|0] "" Vector__XXX
 SG_ VCRIGHT_gloveboxLightCurrent m1 : 47|5@1+ (2,0) [0|0] "" Vector__XXX
 SG_ VCRIGHT_rearRightBuckleSwitch m0 : 46|2@1+ (1,0) [0|0] "" Vector__XXX
 SG_ VCRIGHT_rearCenterBuckleSwitch m0 : 44|2@1+ (1,0) [0|0] "" Vector__XXX
 SG_ VCRIGHT_frontOccupancySwitch m0 : 42|2@1+ (1,0) [0|0] "" Vector__XXX
 SG_ VCRIGHT_frontBuckleSwitch m0 : 40|2@1+ (1,0) [0|0] "" Vector__XXX
 SG_ VCRIGHT_rearHandlePWM m1 : 40|7@1+ (1,0) [0|0] "" Vector__XXX
 SG_ VCRIGHT_btnWindowSwPackAutoDwnLR m0 : 39|1@1+ (1,0) [0|0] "" Vector__XXX
 SG_ VCRIGHT_hvacHeatingAllowedLeft m1 : 39|1@1+ (1,0) [0|0] "" Vector__XXX
 SG_ VCRIGHT_btnWindowSwPackDownLR m0 : 38|1@1+ (1,0) [0|0] "" Vector__XXX
 SG_ VCRIGHT_btnWindowSwPackAutoUpLR m0 : 37|1@1+ (1,0) [0|0] "" Vector__XXX
 SG_ VCRIGHT_btnWindowSwPackUpLR m0 : 36|1@1+ (1,0) [0|0] "" Vector__XXX
 SG_ VCRIGHT_btnWindowSwPackAutoDwnLF m0 : 35|1@1+ (1,0) [0|0] "" Vector__XXX
 SG_ VCRIGHT_btnWindowSwPackDownLF m0 : 34|1@1+ (1,0) [0|0] "" Vector__XXX
 SG_ VCRIGHT_btnWindowSwPackAutoUpLF m0 : 33|1@1+ (1,0) [0|0] "" Vector__XXX
 SG_ VCRIGHT_btnWindowSwPackUpLF m0 : 32|1@1+ (1,0) [0|0] "" Vector__XXX
 SG_ VCRIGHT_frontHandlePWM m1 : 32|7@1+ (1,0) [0|0] "" Vector__XXX
 SG_ VCRIGHT_btnWindowAutoDownRR m0 : 31|1@1+ (1,0) [0|0] "" Vector__XXX
 SG_ VCRIGHT_btnWindowDownRR m0 : 30|1@1+ (1,0) [0|0] "" Vector__XXX
 SG_ VCRIGHT_btnWindowAutoUpRR m0 : 29|1@1+ (1,0) [0|0] "" Vector__XXX
 SG_ VCRIGHT_btnWindowUpRR m0 : 28|1@1+ (1,0) [0|0] "" Vector__XXX
 SG_ VCRIGHT_2RowSeatBackrestFoldSwitch m1 : 27|1@1+ (1,0) [0|0] "" Vector__XXX
 SG_ VCRIGHT_btnWindowAutoDownRF m0 : 27|1@1+ (1,0) [0|0] "" Vector__XXX
 SG_ VCRIGHT_2RowSeatReclineSwitch m1 : 26|1@1+ (1,0) [0|0] "" Vector__XXX
 SG_ VCRIGHT_btnWindowDownRF m0 : 26|1@1+ (1,0) [0|0] "" Vector__XXX
 SG_ VCRIGHT_btnWindowAutoUpRF m0 : 25|1@1+ (1,0) [0|0] "" Vector__XXX
 SG_ VCRIGHT_btnWindowUpRF m0 : 24|1@1+ (1,0) [0|0] "" Vector__XXX
 SG_ VCRIGHT_frontSeatLumbarOut m1 : 24|2@1+ (1,0) [0|0] "" Vector__XXX
 SG_ VCRIGHT_frontSeatLumbarIn m1 : 22|2@1+ (1,0) [0|0] "" Vector__XXX
 SG_ VCRIGHT_frontSeatLumbarUp m1 : 20|2@1+ (1,0) [0|0] "" Vector__XXX
 SG_ VCRIGHT_frontSeatLumbarDown m1 : 18|2@1+ (1,0) [0|0] "" Vector__XXX
 SG_ VCRIGHT_frontSeatBackrestForward m1 : 16|2@1+ (1,0) [0|0] "" Vector__XXX
 SG_ VCRIGHT_frontSeatBackrestBack m1 : 14|2@1+ (1,0) [0|0] "" Vector__XXX
 SG_ VCRIGHT_frontSeatLiftUp m1 : 12|2@1+ (1,0) [0|0] "" Vector__XXX
 SG_ VCRIGHT_frontSeatLiftDown m1 : 10|2@1+ (1,0) [0|0] "" Vector__XXX
 SG_ VCRIGHT_frontSeatTiltUp m1 : 8|2@1+ (1,0) [0|0] "" Vector__XXX
 SG_ VCRIGHT_frontSeatTiltDown m1 : 6|2@1+ (1,0) [0|0] "" Vector__XXX
 SG_ VCRIGHT_frontSeatTrackForward m1 : 4|2@1+ (1,0) [0|0] "" Vector__XXX
 SG_ VCRIGHT_frontSeatTrackBack m1 : 2|2@1+ (1,0) [0|0] "" Vector__XXX
 SG_ VCRIGHT_trunkExtReleasePressedPersist m1 : 1|1@1+ (1,0) [0|0] "" Vector__XXX
 SG_ VCRIGHT_switchStatusIndex M : 0|1@1+ (1,0) [0|0] "" Vector__XXX

BO_ 969 APS_status: 8 Vector__XXX
 SG_ APS_apbActivePlannerType : 61|3@1+ (1,0) [0|0] "" Vector__XXX
 SG_ APS_appActivePlannerType : 58|3@1+ (1,0) [0|0] "" Vector__XXX
 SG_ APS_otherArbState : 55|3@1+ (1,0) [0|0] "" Vector__XXX
 SG_ APS_socPowerOperatingMode : 53|2@1+ (1,0) [0|0] "" Vector__XXX
 SG_ APS_arbState : 50|3@1+ (1,0) [0|0] "" Vector__XXX
 SG_ APS_gpsAntennaState : 48|2@1+ (1,0) [0|0] "" Vector__XXX
 SG_ APS_autosummonAlert : 47|1@1+ (1,0) [0|0] "" Vector__XXX
 SG_ APS_autosummonCounter : 44|3@1+ (1,0) [0|0] "" Vector__XXX
 SG_ APS_heaterStateDebug : 41|3@1+ (1,0) [0|0] "" Vector__XXX
 SG_ APS_apbPowerStateReason : 37|4@1+ (1,0) [0|0] "" Vector__XXX
 SG_ APS_apbPowerStateRequest : 35|2@1+ (1,0) [0|0] "" Vector__XXX
 SG_ APS_appPowerStateReason : 31|4@1+ (1,0) [0|0] "" Vector__XXX
 SG_ APS_appPowerStateRequest : 29|2@1+ (1,0) [0|0] "" Vector__XXX
 SG_ APS_locLimitReason : 26|3@1+ (1,0) [0|0] "" Vector__XXX
 SG_ APS_statusCounter : 22|4@1+ (1,0) [0|0] "" Vector__XXX
 SG_ APS_apbGpioState : 20|2@1+ (1,0) [0|0] "" Vector__XXX
 SG_ APS_apbStatusMonitorState : 16|3@1+ (1,0) [0|0] "" Vector__XXX
 SG_ APS_switchState : 15|1@1+ (1,0) [0|0] "" Vector__XXX
 SG_ APS_eacInternalState : 12|3@1+ (1,0) [0|0] "" Vector__XXX
 SG_ APS_appGpioState : 10|2@1+ (1,0) [0|0] "" Vector__XXX
 SG_ APS_canMaster : 8|2@1+ (1,0) [0|0] "" Vector__XXX
 SG_ APS_vehBehaviorState : 4|4@1+ (1,0) [0|0] "" Vector__XXX
 SG_ APS_appStatusMonitorState : 0|3@1+ (1,0) [0|0] "" Vector__XXX

BO_ 970 DAS_gpsStatus: 8 Vector__XXX
 SG_ DAS_gpsRawxEnabled m0 : 62|1@1+ (1,0) [0|0] "" Vector__XXX
 SG_ DAS_gpsNmeaDispatchFailureCount m1 : 60|4@1+ (5,0) [0|0] "" Vector__XXX
 SG_ DAS_gpsFixTypeHardware m0 : 59|3@1+ (1,0) [0|0] "" Vector__XXX
 SG_ DAS_gnssAvgInstantaneousCnorBdsLowBand m3 : 58|6@1+ (1,0) [0|0] "" Vector__XXX
 SG_ DAS_gpsWheelsOffMotionDetected m0 : 58|1@1+ (1,0) [0|0] "" Vector__XXX
 SG_ DAS_gpsRejectingSatData m0 : 57|1@1+ (1,0) [0|0] "" Vector__XXX
 SG_ DAS_gpsPreviousPositionDeltaSw m1 : 54|6@1+ (3,0) [0|0] "" Vector__XXX
 SG_ DAS_gnssAvgInstantaneousCnorGalLowBand m3 : 52|6@1+ (1,0) [0|0] "" Vector__XXX
 SG_ DAS_gpsPreviousPositionDeltaHw m1 : 48|6@1+ (3,0) [0|0] "" Vector__XXX
 SG_ DAS_gpsSatsInUseSoftwareSocB m2 : 48|4@1+ (1,0) [0|0] "" Vector__XXX
 SG_ DAS_gnssAvgInstantaneousCnorGpsLowBand m3 : 46|6@1+ (1,0) [0|0] "" Vector__XXX
 SG_ DAS_gpsFixTypeSoftwareSocB m2 : 45|3@1+ (1,0) [0|0] "" Vector__XXX
 SG_ DAS_gpsRedundancyActive m2 : 44|1@1+ (1,0) [0|0] "" Vector__XXX
 SG_ DAS_gpsSolutionSoc m2 : 42|2@1+ (1,0) [0|0] "" Vector__XXX
 SG_ DAS_gnssAvgInstantCnorBdsSocB m3 : 40|6@1+ (1,0) [0|0] "" Vector__XXX
 SG_ DAS_gpsAutomaticGainControl m1 : 40|8@1+ (32,0) [0|0] "" Vector__XXX
 SG_ DAS_gpsToMcuSource m2 : 39|3@1+ (1,0) [0|0] "" Vector__XXX
 SG_ DAS_gpsSolutionFallback m2 : 38|1@1+ (1,0) [0|0] "" Vector__XXX
 SG_ DAS_gnssAvgInstantCnorGpsSocB m3 : 34|6@1+ (1,0) [0|0] "" Vector__XXX
 SG_ DAS_gpsReceiverNoiseLevel m1 : 34|6@1+ (8,0) [0|0] "" Vector__XXX
 SG_ DAS_gnssConstellationsState m1 : 32|2@1+ (1,0) [0|0] "" Vector__XXX
 SG_ DAS_gpsAccuracyVertical m2 : 32|6@1+ (1,0) [0|0] "" Vector__XXX
 SG_ DAS_gnssAvgInstantaneousCnorBds m3 : 28|6@1+ (1,0) [0|0] "" Vector__XXX
 SG_ DAS_gpsInvalidMsgPercentage m1 : 28|4@1+ (6,0) [0|0] "" Vector__XXX
 SG_ DAS_gpsAccuracyHorizontal m2 : 26|6@1+ (1,0) [0|0] "" Vector__XXX
 SG_ DAS_gpsSpoofDetectorState m1 : 26|2@1+ (1,0) [0|0] "" Vector__XXX
 SG_ DAS_gpsWheeltickPulsePeriod m0 : 25|32@1+ (1,0) [0|0] "" Vector__XXX
 SG_ DAS_gpsJammingState m1 : 24|2@1+ (1,0) [0|0] "" Vector__XXX
 SG_ DAS_gnssAvgInstantaneousCnorGal m3 : 22|6@1+ (1,0) [0|0] "" Vector__XXX
 SG_ DAS_gpsResetReason m2 : 22|4@1+ (1,0) [0|0] "" Vector__XXX
 SG_ DAS_gpsCWJammingInidcator m1 : 19|5@1+ (8,0) [0|0] "" Vector__XXX
 SG_ DAS_gnssAvgInstantaneousCnorGps m3 : 16|6@1+ (1,0) [0|0] "" Vector__XXX
 SG_ DAS_gnssMaxInstantaneousCnorBds m2 : 16|6@1+ (1,0) [0|0] "" Vector__XXX
 SG_ DAS_gpsFixTypeSoftware m1 : 16|3@1+ (1,0) [0|0] "" Vector__XXX
 SG_ DAS_gnssNumSatsBds m3 : 12|4@1+ (1,0) [0|0] "" Vector__XXX
 SG_ DAS_gpsSatsInUseSoftware m1 : 12|4@1+ (1,0) [0|0] "" Vector__XXX
 SG_ DAS_gpsSoftwareFastStartReady m1 : 11|1@1+ (1,0) [0|0] "" Vector__XXX
 SG_ DAS_gnssMaxInstantaneousCnorGal m2 : 10|6@1+ (1,0) [0|0] "" Vector__XXX
 SG_ DAS_gpsSoftwareUsed m1 : 10|1@1+ (1,0) [0|0] "" Vector__XXX
 SG_ DAS_gpsSoftwareConfigured m1 : 9|1@1+ (1,0) [0|0] "" Vector__XXX
 SG_ DAS_gpsWheeltickCounter m0 : 9|16@1+ (1,0) [0|0] "" Vector__XXX
 SG_ DAS_gnssNumSatsGal m3 : 8|4@1+ (1,0) [0|0] "" Vector__XXX
 SG_ DAS_gpsNavStatusMia m1 : 8|1@1+ (1,0) [0|0] "" Vector__XXX
 SG_ DAS_gpsEsfRawMia m1 : 7|1@1+ (1,0) [0|0] "" Vector__XXX
 SG_ DAS_gpsEsfMeasMia m1 : 6|1@1+ (1,0) [0|0] "" Vector__XXX
 SG_ DAS_gpsRxmSfrbxMia m1 : 5|1@1+ (1,0) [0|0] "" Vector__XXX
 SG_ DAS_gpsSatsInUseHardware m0 : 5|4@1+ (1,0) [0|0] "" Vector__XXX
 SG_ DAS_gnssMaxInstantaneousCnorGps m2 : 4|6@1+ (1,0) [0|0] "" Vector__XXX
 SG_ DAS_gnssNumSatsGps m3 : 4|4@1+ (1,0) [0|0] "" Vector__XXX
 SG_ DAS_gpsRxmRawxMia m1 : 4|1@1+ (1,0) [0|0] "" Vector__XXX
 SG_ DAS_gpsTransportModeState m0 : 4|1@1+ (1,0) [0|0] "" Vector__XXX
 SG_ DAS_gpsStatusMultiplexer M : 0|4@1+ (1,0) [0|0] "" Vector__XXX

BO_ 971 APS_summonStatus: 5 Vector__XXX
 SG_ APS_r79BLECheckActive : 34|1@1+ (1,0) [0|0] "" Vector__XXX
 SG_ APS_miaCheckActive : 33|1@1+ (1,0) [0|0] "" Vector__XXX
 SG_ APS_gearChangeClamp : 32|1@1+ (1,0) [0|0] "" Vector__XXX
 SG_ APS_noOpCheckActive : 31|1@1+ (1,0) [0|0] "" Vector__XXX
 SG_ APS_watchDogCheckActive : 30|1@1+ (1,0) [0|0] "" Vector__XXX
 SG_ APS_ttcCheckActive : 29|1@1+ (1,0) [0|0] "" Vector__XXX
 SG_ APS_collisionCheckActive : 28|1@1+ (1,0) [0|0] "" Vector__XXX
 SG_ APS_collisionDistance : 21|7@1+ (0.05,0) [0|0] "" Vector__XXX
 SG_ APS_summonSetSpeed : 14|7@1+ (0.1,0) [0|0] "" Vector__XXX
 SG_ APS_apcAbortCode : 8|6@1+ (1,0) [0|0] "" Vector__XXX
 SG_ APS_heartBeatCheckActive : 5|1@1+ (1,0) [0|0] "" Vector__XXX
 SG_ APS_apcInternalState : 1|4@1+ (1,0) [0|0] "" Vector__XXX
 SG_ APS_smartSummonActive : 0|1@1+ (1,0) [0|0] "" Vector__XXX

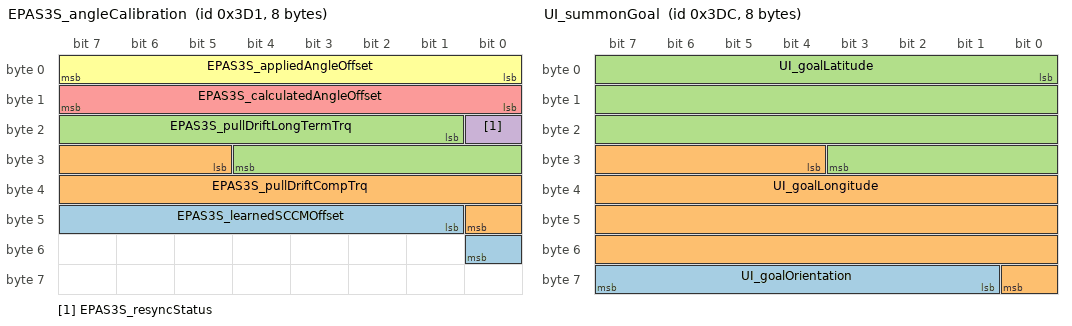
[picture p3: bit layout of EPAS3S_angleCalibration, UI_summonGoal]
BO_ 977 EPAS3S_angleCalibration: 8 Vector__XXX
 SG_ EPAS3S_learnedSCCMOffset : 41|8@1+ (0.1,-12.8) [0|0] "" Vector__XXX
 SG_ EPAS3S_pullDriftCompTrq : 29|12@1+ (0.01,-10) [0|0] "" Vector__XXX
 SG_ EPAS3S_pullDriftLongTermTrq : 17|12@1+ (0.01,-10) [0|0] "" Vector__XXX
 SG_ EPAS3S_resyncStatus : 16|1@1+ (1,0) [0|0] "" Vector__XXX
 SG_ EPAS3S_calculatedAngleOffset : 8|8@1+ (0.1,-12.8) [0|0] "" Vector__XXX
 SG_ EPAS3S_appliedAngleOffset : 0|8@1+ (0.1,-12.8) [0|0] "" Vector__XXX

BO_ 985 UI_locationOffset: 8 Vector__XXX
 SG_ UI_longitudeOffset : 28|29@1- (1e-06,0) [0|0] "" Vector__XXX
 SG_ UI_latitudeOffset : 0|28@1- (1e-06,0) [0|0] "" Vector__XXX

BO_ 988 UI_summonGoal: 8 Vector__XXX
 SG_ UI_goalOrientation : 57|7@1+ (2.8125,0) [0|0] "" Vector__XXX
 SG_ UI_goalLongitude : 28|29@1- (1e-06,0) [0|0] "" Vector__XXX
 SG_ UI_goalLatitude : 0|28@1- (1e-06,0) [0|0] "" Vector__XXX

BO_ 991 UI_status2: 8 Vector__XXX
 SG_ UI_connectivityStandbyActive : 63|1@1+ (1,0) [0|0] "" Vector__XXX
 SG_ UI_sapClients : 62|1@1+ (1,0) [0|0] "" Vector__XXX
 SG_ UI_sapActive : 61|1@1+ (1,0) [0|0] "" Vector__XXX
 SG_ UI_wakeOnIPActive : 60|1@1+ (1,0) [0|0] "" Vector__XXX
 SG_ UI_sentryModeCameraDetection : 59|1@1+ (1,0) [0|0] "" Vector__XXX
 SG_ UI_fullScreenMode : 58|1@1+ (1,0) [0|0] "" Vector__XXX
 SG_ UI_summonDeviceIndex : 56|2@1+ (1,0) [0|0] "" Vector__XXX
 SG_ UI_selfParkState : 48|8@1+ (1,0) [0|0] "" Vector__XXX
 SG_ UI_sohHealthStatus : 46|2@1+ (1,0) [0|0] "" Vector__XXX
 SG_ UI_wifiBtModuleType : 43|3@1+ (1,0) [0|0] "" Vector__XXX
 SG_ UI_autoshiftDRState : 40|3@1+ (1,0) [0|0] "" Vector__XXX
 SG_ UI_phoneLeftInCabin : 39|1@1+ (1,0) [0|0] "" Vector__XXX
 SG_ UI_mobileAppConnected : 38|1@1+ (1,0) [0|0] "" Vector__XXX
 SG_ UI_autopilotSentryRequest : 37|1@1+ (1,0) [0|0] "" Vector__XXX
 SG_ UI_sentryModeState : 34|3@1+ (1,0) [0|0] "" Vector__XXX
 SG_ UI_linkState : 32|2@1+ (1,0) [0|0] "" Vector__XXX
 SG_ UI_activeTouchPoints : 24|8@1+ (1,0) [0|0] "" Vector__XXX
 SG_ UI_userActivity : 23|1@1+ (1,0) [0|0] "" Vector__XXX
 SG_ UI_displayInDarkMode : 22|1@1+ (1,0) [0|0] "" Vector__XXX
 SG_ UI_locatedAtFavorite : 21|1@1+ (1,0) [0|0] "" Vector__XXX
 SG_ UI_locatedAtWork : 20|1@1+ (1,0) [0|0] "" Vector__XXX
 SG_ UI_locatedAtHome : 19|1@1+ (1,0) [0|0] "" Vector__XXX
 SG_ UI_validDeviceForEUSummon : 18|1@1+ (1,0) [0|0] "" Vector__XXX
 SG_ UI_touchDetected : 17|1@1+ (1,0) [0|0] "" Vector__XXX
 SG_ UI_userRequestSnapshot : 16|1@1+ (1,0) [0|0] "" Vector__XXX
 SG_ UI_mobileAppStepCount : 0|16@1+ (1,0) [0|0] "" Vector__XXX

BO_ 1011 UI_odo: 3 Vector__XXX
 SG_ UI_odometer : 0|24@1+ (0.1,0) [0|0] "" Vector__XXX

BO_ 1012 APP_camCalibrationStatus: 6 Vector__XXX
 SG_ APP_backupCalibrated m8 : 40|1@1+ (1,0) [0|0] "" Vector__XXX
 SG_ APP_fisheyeCalibrated m3 : 40|1@1+ (1,0) [0|0] "" Vector__XXX
 SG_ APP_lPillarCalibrated m4 : 40|1@1+ (1,0) [0|0] "" Vector__XXX
 SG_ APP_lRepeatCalibrated m6 : 40|1@1+ (1,0) [0|0] "" Vector__XXX
 SG_ APP_mainCalibrated m1 : 40|1@1+ (1,0) [0|0] "" Vector__XXX
 SG_ APP_narrowCalibrated m2 : 40|1@1+ (1,0) [0|0] "" Vector__XXX
 SG_ APP_rPillarCalibrated m5 : 40|1@1+ (1,0) [0|0] "" Vector__XXX
 SG_ APP_rRepeatCalibrated m7 : 40|1@1+ (1,0) [0|0] "" Vector__XXX
 SG_ APP_backupCalibProgress m8 : 33|7@1+ (1,0) [0|0] "" Vector__XXX
 SG_ APP_fisheyeCalibProgress m3 : 33|7@1+ (1,0) [0|0] "" Vector__XXX
 SG_ APP_lPillarCalibProgress m4 : 33|7@1+ (1,0) [0|0] "" Vector__XXX
 SG_ APP_lRepeatCalibProgress m6 : 33|7@1+ (1,0) [0|0] "" Vector__XXX
 SG_ APP_mainCalibProgress m1 : 33|7@1+ (1,0) [0|0] "" Vector__XXX
 SG_ APP_narrowCalibProgress m2 : 33|7@1+ (1,0) [0|0] "" Vector__XXX
 SG_ APP_rPillarCalibProgress m5 : 33|7@1+ (1,0) [0|0] "" Vector__XXX
 SG_ APP_rRepeatCalibProgress m7 : 33|7@1+ (1,0) [0|0] "" Vector__XXX
 SG_ APP_backupCalibTime m8 : 26|7@1+ (1,0) [0|0] "" Vector__XXX
 SG_ APP_fisheyeCalibTime m3 : 26|7@1+ (1,0) [0|0] "" Vector__XXX
 SG_ APP_lPillarCalibTime m4 : 26|7@1+ (1,0) [0|0] "" Vector__XXX
 SG_ APP_lRepeatCalibTime m6 : 26|7@1+ (1,0) [0|0] "" Vector__XXX
 SG_ APP_mainCalibTime m1 : 26|7@1+ (1,0) [0|0] "" Vector__XXX
 SG_ APP_narrowCalibTime m2 : 26|7@1+ (1,0) [0|0] "" Vector__XXX
 SG_ APP_rPillarCalibTime m5 : 26|7@1+ (1,0) [0|0] "" Vector__XXX
 SG_ APP_rRepeatCalibTime m7 : 26|7@1+ (1,0) [0|0] "" Vector__XXX
 SG_ APP_backupCamExtYawCal m8 : 17|9@1+ (0.05,-12.5) [0|0] "" Vector__XXX
 SG_ APP_fisheyeCamExtYawCal m3 : 17|9@1+ (0.05,-12.5) [0|0] "" Vector__XXX
 SG_ APP_lPillarCamExtYawCal m4 : 17|9@1+ (0.05,-12.5) [0|0] "" Vector__XXX
 SG_ APP_lRepeatCamExtYawCal m6 : 17|9@1+ (0.05,-12.5) [0|0] "" Vector__XXX
 SG_ APP_mainCamExtYawCal m1 : 17|9@1+ (0.05,-12.5) [0|0] "" Vector__XXX
 SG_ APP_narrowCamExtYawCal m2 : 17|9@1+ (0.05,-12.5) [0|0] "" Vector__XXX
 SG_ APP_rPillarCamExtYawCal m5 : 17|9@1+ (0.05,-12.5) [0|0] "" Vector__XXX
 SG_ APP_rRepeatCamExtYawCal m7 : 17|9@1+ (0.05,-12.5) [0|0] "" Vector__XXX
 SG_ APP_backupCamExtPitchCal m8 : 8|9@1+ (0.05,-12.5) [0|0] "" Vector__XXX
 SG_ APP_fisheyeCamExtPitchCal m3 : 8|9@1+ (0.05,-12.5) [0|0] "" Vector__XXX
 SG_ APP_lPillarCamExtPitchCal m4 : 8|9@1+ (0.05,-12.5) [0|0] "" Vector__XXX
 SG_ APP_lRepeatCamExtPitchCal m6 : 8|9@1+ (0.05,-12.5) [0|0] "" Vector__XXX
 SG_ APP_mainCamExtPitchCal m1 : 8|9@1+ (0.05,-12.5) [0|0] "" Vector__XXX
 SG_ APP_narrowCamExtPitchCal m2 : 8|9@1+ (0.05,-12.5) [0|0] "" Vector__XXX
 SG_ APP_rPillarCamExtPitchCal m5 : 8|9@1+ (0.05,-12.5) [0|0] "" Vector__XXX
 SG_ APP_rRepeatCamExtPitchCal m7 : 8|9@1+ (0.05,-12.5) [0|0] "" Vector__XXX
 SG_ APP_cameraPosition M : 0|4@1+ (1,0) [0|0] "" Vector__XXX

BO_ 1013 VCFRONT_lighting: 8 Vector__XXX
 SG_ VCFRONT_indicatorRightInternal : 52|2@1+ (1,0) [0|0] "" Vector__XXX
 SG_ VCFRONT_indicatorLeftInternal : 50|2@1+ (1,0) [0|0] "" Vector__XXX
 SG_ VC_fastFlashHazardsActive : 49|1@1+ (1,0) [0|0] "" Vector__XXX
 SG_ VCFRONT_lightingCustomState : 44|5@1+ (1,0) [0|0] "" Vector__XXX
 SG_ VCFRONT_highBeamLatchingState : 42|2@1+ (1,0) [0|0] "" Vector__XXX
 SG_ VCFRONT_turnIndicatorStalk : 40|2@1+ (1,0) [0|0] "" Vector__XXX
 SG_ VCFRONT_headlightsReadyOrTimedOut : 39|1@1+ (1,0) [0|0] "" Vector__XXX
 SG_ VCFRONT_frontFogFunctionState : 38|1@1+ (1,0) [0|0] "" Vector__XXX
 SG_ VCFRONT_latchedHighBeamsFunctionState : 37|1@1+ (1,0) [0|0] "" Vector__XXX
 SG_ VCFRONT_intHighBeamsFunctionState : 36|1@1+ (1,0) [0|0] "" Vector__XXX
 SG_ VCFRONT_lightingCoreState : 32|4@1+ (1,0) [0|0] "" Vector__XXX
 SG_ VCFRONT_dynamicBrakeLightState : 30|2@1+ (1,0) [0|0] "" Vector__XXX
 SG_ VCFRONT_highBeamControlState : 28|2@1+ (1,0) [0|0] "" Vector__XXX
 SG_ VCFRONT_hazardSwitchBacklight : 27|1@1+ (1,0) [0|0] "" Vector__XXX
 SG_ VCFRONT_courtesyLightingRequest : 24|1@1+ (1,0) [0|0] "" Vector__XXX
 SG_ VCFRONT_switchLightingBrightness : 16|8@1+ (0.5,0) [0|0] "" Vector__XXX
 SG_ VCFRONT_ambientLightingBrightnes : 8|8@1+ (0.5,0) [0|0] "" Vector__XXX
 SG_ VCFRONT_hazardLightRequest : 4|4@1+ (1,0) [0|0] "" Vector__XXX
 SG_ VCFRONT_indicatorRightRequest : 2|2@1+ (1,0) [0|0] "" Vector__XXX
 SG_ VCFRONT_indicatorLeftRequest : 0|2@1+ (1,0) [0|0] "" Vector__XXX

BO_ 1016 UI_driverAssistControl: 8 Vector__XXX
 SG_ UI_isaSpeedingChimeMuted : 63|1@1+ (1,0) [0|0] "" Vector__XXX
 SG_ UI_source3D : 61|2@1+ (1,0) [0|0] "" Vector__XXX
 SG_ UI_enableVisionOnlyStops : 60|1@1+ (1,0) [0|0] "" Vector__XXX
 SG_ UI_smartSummonType : 58|2@1+ (1,0) [0|0] "" Vector__XXX
 SG_ UI_validationLoop : 57|1@1+ (1,0) [0|0] "" Vector__XXX
 SG_ UI_alcOffHighwayEnable : 56|1@1+ (1,0) [0|0] "" Vector__XXX
 SG_ UI_enableClipStartStopTelemetry : 55|1@1+ (1,0) [0|0] "" Vector__XXX
 SG_ UI_suppressExitPassingLane : 54|1@1+ (1,0) [0|0] "" Vector__XXX
 SG_ UI_ulcBlindSpotConfig : 52|2@1+ (1,0) [0|0] "" Vector__XXX
 SG_ UI_ulcSpeedConfig : 50|2@1+ (1,0) [0|0] "" Vector__XXX
 SG_ UI_followNavRouteEnable : 49|1@1+ (1,0) [0|0] "" Vector__XXX
 SG_ UI_hasDriveOnNav : 48|1@1+ (1,0) [0|0] "" Vector__XXX
 SG_ UI_accFollowDistanceSetting : 45|3@1+ (1,0) [0|0] "" Vector__XXX
 SG_ UI_enableRoadSegmentTelemetry : 44|1@1+ (1,0) [0|0] "" Vector__XXX
 SG_ UI_enableTripTelemetry : 43|1@1+ (1,0) [0|0] "" Vector__XXX
 SG_ UI_enableClipTelemetry : 42|1@1+ (1,0) [0|0] "" Vector__XXX
 SG_ UI_drivingSide : 40|2@1+ (1,0) [0|0] "" Vector__XXX
 SG_ UI_adaptiveSetSpeedEnable : 39|1@1+ (1,0) [0|0] "" Vector__XXX
 SG_ UI_undertakeAssistEnable : 38|1@1+ (1,0) [0|0] "" Vector__XXX
 SG_ UI_summonReverseDist : 32|6@1+ (1,0) [0|0] "" Vector__XXX
 SG_ UI_selfParkRequest : 28|4@1+ (1,0) [0|0] "" Vector__XXX
 SG_ UI_summonEntryType : 26|2@1+ (1,0) [0|0] "" Vector__XXX
 SG_ UI_summonExitType : 24|2@1+ (1,0) [0|0] "" Vector__XXX
 SG_ UI_lssElkEnabled : 23|1@1+ (1,0) [0|0] "" Vector__XXX
 SG_ UI_curvatureDatabaseOnly : 22|1@1+ (1,0) [0|0] "" Vector__XXX
 SG_ UI_visionSpeedType : 20|2@1+ (1,0) [0|0] "" Vector__XXX
 SG_ UI_enableClipParkedTelemetry : 19|1@1+ (1,0) [0|0] "" Vector__XXX
 SG_ UI_fuseVehiclesDisable : 18|1@1+ (1,0) [0|0] "" Vector__XXX
 SG_ UI_fuseHPPDisable : 17|1@1+ (1,0) [0|0] "" Vector__XXX
 SG_ UI_fuseLanesDisable : 16|1@1+ (1,0) [0|0] "" Vector__XXX
 SG_ UI_ulcOffHighway : 15|1@1+ (1,0) [0|0] "" Vector__XXX
 SG_ UI_handsOnRequirementDisable : 14|1@1+ (1,0) [0|0] "" Vector__XXX
 SG_ UI_driveOnMapsEnable : 13|1@1+ (1,0) [0|0] "" Vector__XXX
 SG_ UI_roadCheckDisable : 12|1@1+ (1,0) [0|0] "" Vector__XXX
 SG_ UI_exceptionListEnable : 11|1@1+ (1,0) [0|0] "" Vector__XXX
 SG_ UI_autoSummonEnable : 10|1@1+ (1,0) [0|0] "" Vector__XXX
 SG_ UI_coastToCoast : 9|1@1+ (1,0) [0|0] "" Vector__XXX
 SG_ UI_lssLdwEnabled : 8|1@1+ (1,0) [0|0] "" Vector__XXX
 SG_ UI_lssLkaEnabled : 7|1@1+ (1,0) [0|0] "" Vector__XXX
 SG_ UI_enableVinAssociation : 6|1@1+ (1,0) [0|0] "" Vector__XXX
 SG_ UI_dasDeveloper : 5|1@1+ (1,0) [0|0] "" Vector__XXX
 SG_ UI_curvSpeedAdaptDisable : 4|1@1+ (1,0) [0|0] "" Vector__XXX
 SG_ UI_summonHeartbeat : 2|2@1+ (1,0) [0|0] "" Vector__XXX
 SG_ UI_ulcStalkConfirm : 1|1@1+ (1,0) [0|0] "" Vector__XXX
 SG_ UI_autopilotControlRequest : 0|1@1+ (1,0) [0|0] "" Vector__XXX

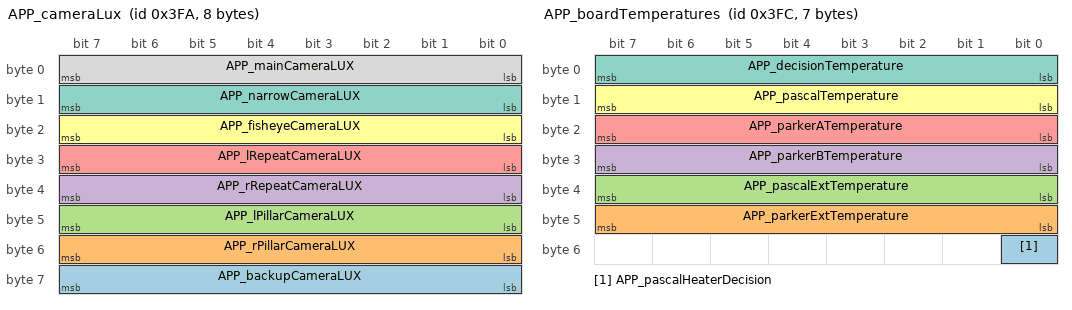
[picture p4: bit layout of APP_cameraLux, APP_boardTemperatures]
BO_ 1018 APP_cameraLux: 8 Vector__XXX
 SG_ APP_backupCameraLUX : 56|8@1+ (0.5,0) [0|0] "" Vector__XXX
 SG_ APP_rPillarCameraLUX : 48|8@1+ (0.5,0) [0|0] "" Vector__XXX
 SG_ APP_lPillarCameraLUX : 40|8@1+ (0.5,0) [0|0] "" Vector__XXX
 SG_ APP_rRepeatCameraLUX : 32|8@1+ (0.5,0) [0|0] "" Vector__XXX
 SG_ APP_lRepeatCameraLUX : 24|8@1+ (0.5,0) [0|0] "" Vector__XXX
 SG_ APP_fisheyeCameraLUX : 16|8@1+ (0.5,0) [0|0] "" Vector__XXX
 SG_ APP_narrowCameraLUX : 8|8@1+ (0.5,0) [0|0] "" Vector__XXX
 SG_ APP_mainCameraLUX : 0|8@1+ (0.5,0) [0|0] "" Vector__XXX

BO_ 1020 APP_boardTemperatures: 7 Vector__XXX
 SG_ APP_pascalHeaterDecision : 48|1@1+ (1,0) [0|0] "" Vector__XXX
 SG_ APP_parkerExtTemperature : 40|8@1+ (1,-128) [0|0] "" Vector__XXX
 SG_ APP_pascalExtTemperature : 32|8@1+ (1,-128) [0|0] "" Vector__XXX
 SG_ APP_parkerBTemperature : 24|8@1+ (1,-128) [0|0] "" Vector__XXX
 SG_ APP_parkerATemperature : 16|8@1+ (1,-128) [0|0] "" Vector__XXX
 SG_ APP_pascalTemperature : 8|8@1+ (1,-128) [0|0] "" Vector__XXX
 SG_ APP_decisionTemperature : 0|8@1+ (1,-128) [0|0] "" Vector__XXX

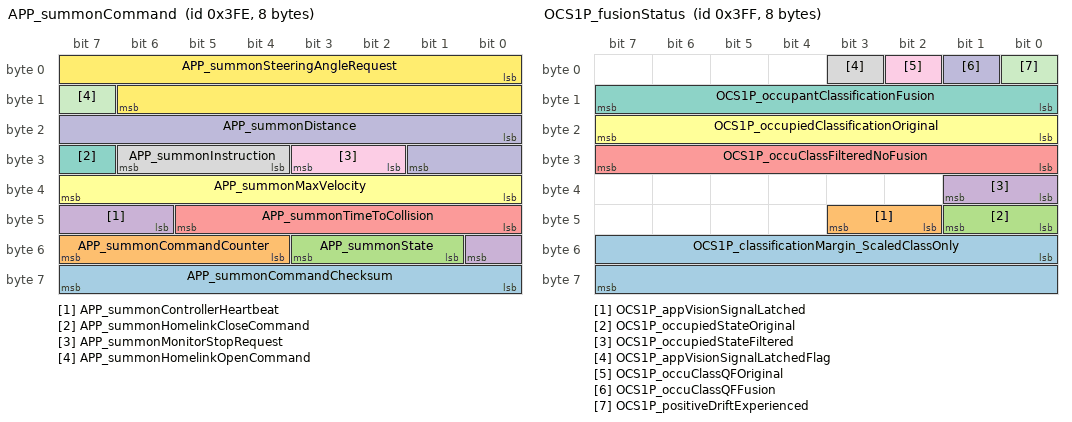
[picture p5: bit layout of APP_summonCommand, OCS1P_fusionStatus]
BO_ 1022 APP_summonCommand: 8 Vector__XXX
 SG_ APP_summonCommandChecksum : 56|8@1+ (1,0) [0|0] "" Vector__XXX
 SG_ APP_summonCommandCounter : 52|4@1+ (1,0) [0|0] "" Vector__XXX
 SG_ APP_summonState : 49|3@1+ (1,0) [0|0] "" Vector__XXX
 SG_ APP_summonControllerHeartbeat : 46|3@1+ (1,0) [0|0] "" Vector__XXX
 SG_ APP_summonTimeToCollision : 40|6@1+ (0.1,0) [0|0] "" Vector__XXX
 SG_ APP_summonMaxVelocity : 32|8@1+ (0.05,0) [0|0] "" Vector__XXX
 SG_ APP_summonHomelinkCloseCommand : 31|1@1+ (1,0) [0|0] "" Vector__XXX
 SG_ APP_summonInstruction : 28|3@1+ (1,0) [0|0] "" Vector__XXX
 SG_ APP_summonMonitorStopRequest : 26|2@1+ (1,0) [0|0] "" Vector__XXX
 SG_ APP_summonDistance : 16|10@1+ (0.02,0) [0|0] "" Vector__XXX
 SG_ APP_summonHomelinkOpenCommand : 15|1@1+ (1,0) [0|0] "" Vector__XXX
 SG_ APP_summonSteeringAngleRequest : 0|15@1+ (0.1,-1638.35) [0|0] "" Vector__XXX

BO_ 1023 OCS1P_fusionStatus: 8 Vector__XXX
 SG_ OCS1P_classificationMargin_ScaledClassOnly : 48|16@1- (2,0) [0|0] "" Vector__XXX
 SG_ OCS1P_appVisionSignalLatched : 42|2@1+ (1,0) [0|0] "" Vector__XXX
 SG_ OCS1P_occupiedStateOriginal : 40|2@1+ (1,0) [0|0] "" Vector__XXX
 SG_ OCS1P_occupiedStateFiltered : 32|2@1+ (1,0) [0|0] "" Vector__XXX
 SG_ OCS1P_occuClassFilteredNoFusion : 24|8@1+ (1,0) [0|0] "" Vector__XXX
 SG_ OCS1P_occupiedClassificationOriginal : 16|8@1+ (1,0) [0|0] "" Vector__XXX
 SG_ OCS1P_occupantClassificationFusion : 8|8@1+ (1,0) [0|0] "" Vector__XXX
 SG_ OCS1P_appVisionSignalLatchedFlag : 3|1@1+ (1,0) [0|0] "" Vector__XXX
 SG_ OCS1P_occuClassQFOriginal : 2|1@1+ (1,0) [0|0] "" Vector__XXX
 SG_ OCS1P_occuClassQFFusion : 1|1@1+ (1,0) [0|0] "" Vector__XXX
 SG_ OCS1P_positiveDriftExperienced : 0|1@1+ (1,0) [0|0] "" Vector__XXX

BO_ 1029 GTW_vin: 8 Vector__XXX
 SG_ GTW_vinHigh m16 : 47|24@0+ (1,0) [0|0] "" Vector__XXX
 SG_ GTW_vinLow m18 : 15|56@0+ (1,0) [0|0] "" Vector__XXX
 SG_ GTW_vinMid m17 : 15|56@0+ (1,0) [0|0] "" Vector__XXX
 SG_ GTW_vinIndex M : 7|8@0+ (1,0) [0|0] "" Vector__XXX

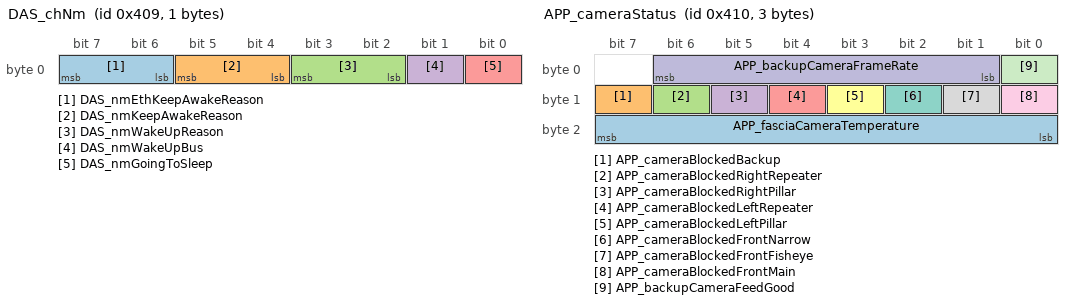
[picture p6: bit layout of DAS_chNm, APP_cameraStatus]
BO_ 1033 DAS_chNm: 1 Vector__XXX
 SG_ DAS_nmEthKeepAwakeReason : 6|2@1+ (1,0) [0|0] "" Vector__XXX
 SG_ DAS_nmKeepAwakeReason : 4|2@1+ (1,0) [0|0] "" Vector__XXX
 SG_ DAS_nmWakeUpReason : 2|2@1+ (1,0) [0|0] "" Vector__XXX
 SG_ DAS_nmWakeUpBus : 1|1@1+ (1,0) [0|0] "" Vector__XXX
 SG_ DAS_nmGoingToSleep : 0|1@1+ (1,0) [0|0] "" Vector__XXX

BO_ 1040 APP_cameraStatus: 3 Vector__XXX
 SG_ APP_fasciaCameraTemperature : 16|8@1+ (1,-60) [0|0] "" Vector__XXX
 SG_ APP_cameraBlockedBackup : 15|1@1+ (1,0) [0|0] "" Vector__XXX
 SG_ APP_cameraBlockedRightRepeater : 14|1@1+ (1,0) [0|0] "" Vector__XXX
 SG_ APP_cameraBlockedRightPillar : 13|1@1+ (1,0) [0|0] "" Vector__XXX
 SG_ APP_cameraBlockedLeftRepeater : 12|1@1+ (1,0) [0|0] "" Vector__XXX
 SG_ APP_cameraBlockedLeftPillar : 11|1@1+ (1,0) [0|0] "" Vector__XXX
 SG_ APP_cameraBlockedFrontNarrow : 10|1@1+ (1,0) [0|0] "" Vector__XXX
 SG_ APP_cameraBlockedFrontFisheye : 9|1@1+ (1,0) [0|0] "" Vector__XXX
 SG_ APP_cameraBlockedFrontMain : 8|1@1+ (1,0) [0|0] "" Vector__XXX
 SG_ APP_backupCameraFrameRate : 1|6@1+ (1,0) [0|0] "" Vector__XXX
 SG_ APP_backupCameraFeedGood : 0|1@1+ (1,0) [0|0] "" Vector__XXX

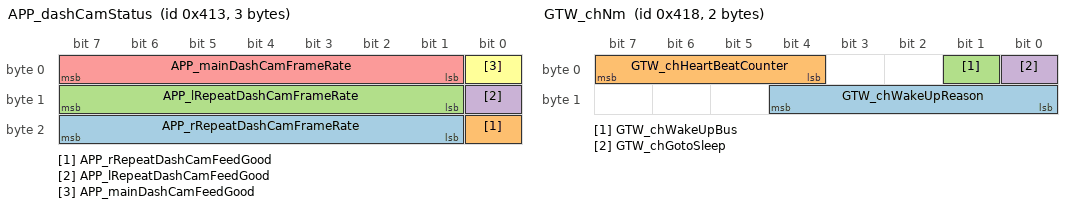
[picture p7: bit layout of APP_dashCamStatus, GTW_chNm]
BO_ 1043 APP_dashCamStatus: 3 Vector__XXX
 SG_ APP_rRepeatDashCamFrameRate : 17|7@1+ (1,0) [0|0] "" Vector__XXX
 SG_ APP_rRepeatDashCamFeedGood : 16|1@1+ (1,0) [0|0] "" Vector__XXX
 SG_ APP_lRepeatDashCamFrameRate : 9|7@1+ (1,0) [0|0] "" Vector__XXX
 SG_ APP_lRepeatDashCamFeedGood : 8|1@1+ (1,0) [0|0] "" Vector__XXX
 SG_ APP_mainDashCamFrameRate : 1|7@1+ (1,0) [0|0] "" Vector__XXX
 SG_ APP_mainDashCamFeedGood : 0|1@1+ (1,0) [0|0] "" Vector__XXX

BO_ 1045 APP_backupDashCamStatus: 1 Vector__XXX
 SG_ APP_backupDashCamFrameRate : 1|7@1+ (1,0) [0|0] "" Vector__XXX
 SG_ APP_backupDashCamFeedGood : 0|1@1+ (1,0) [0|0] "" Vector__XXX

BO_ 1048 GTW_chNm: 2 Vector__XXX
 SG_ GTW_chWakeUpReason : 8|5@1+ (1,0) [0|0] "" Vector__XXX
 SG_ GTW_chHeartBeatCounter : 4|4@1+ (1,0) [0|0] "" Vector__XXX
 SG_ GTW_chWakeUpBus : 1|1@1+ (1,0) [0|0] "" Vector__XXX
 SG_ GTW_chGotoSleep : 0|1@1+ (1,0) [0|0] "" Vector__XXX

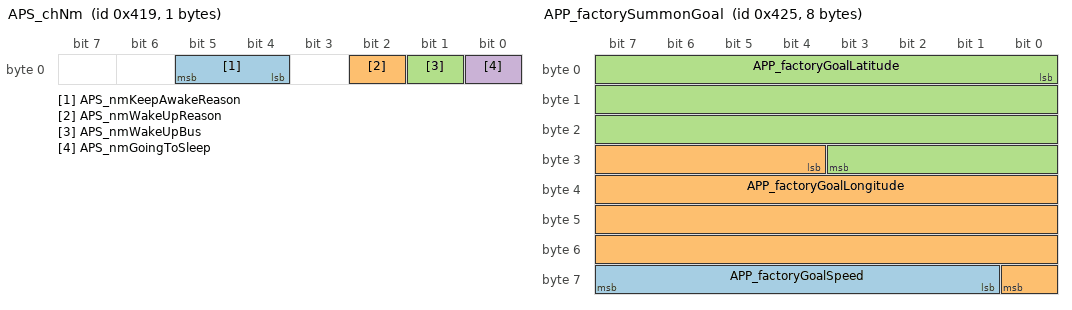
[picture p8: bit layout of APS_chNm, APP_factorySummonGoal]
BO_ 1049 APS_chNm: 1 Vector__XXX
 SG_ APS_nmKeepAwakeReason : 4|2@1+ (1,0) [0|0] "" Vector__XXX
 SG_ APS_nmWakeUpReason : 2|1@1+ (1,0) [0|0] "" Vector__XXX
 SG_ APS_nmWakeUpBus : 1|1@1+ (1,0) [0|0] "" Vector__XXX
 SG_ APS_nmGoingToSleep : 0|1@1+ (1,0) [0|0] "" Vector__XXX

BO_ 1056 APS_state: 8 Vector__XXX
 SG_ APS_stateCounter : 55|4@1+ (1,0) [0|0] "" Vector__XXX
 SG_ APS_B_faultInduced : 54|1@1+ (1,0) [0|0] "" Vector__XXX
 SG_ APS_A_faultInduced : 53|1@1+ (1,0) [0|0] "" Vector__XXX
 SG_ APS_eplannerState : 50|3@1+ (1,0) [0|0] "" Vector__XXX
 SG_ APS_B_autosteerMonitorState : 47|3@1+ (1,0) [0|0] "" Vector__XXX
 SG_ APS_A_autosteerMonitorState : 44|3@1+ (1,0) [0|0] "" Vector__XXX
 SG_ APS_B_faultState : 39|5@1+ (1,0) [0|0] "" Vector__XXX
 SG_ APS_B_resetState : 36|3@1+ (1,0) [0|0] "" Vector__XXX
 SG_ APS_B_sleepState : 32|4@1+ (1,0) [0|0] "" Vector__XXX
 SG_ APS_B_powerState : 27|5@1+ (1,0) [0|0] "" Vector__XXX
 SG_ APS_B_arbState : 24|3@1+ (1,0) [0|0] "" Vector__XXX
 SG_ APS_secondaryTurbo : 22|2@1+ (1,0) [0|0] "" Vector__XXX
 SG_ APS_A_faultState : 17|5@1+ (1,0) [0|0] "" Vector__XXX
 SG_ APS_A_resetState : 14|3@1+ (1,0) [0|0] "" Vector__XXX
 SG_ APS_A_sleepState : 10|4@1+ (1,0) [0|0] "" Vector__XXX
 SG_ APS_A_powerState : 5|5@1+ (1,0) [0|0] "" Vector__XXX
 SG_ APS_A_arbState : 2|3@1+ (1,0) [0|0] "" Vector__XXX
 SG_ APS_primaryTurbo : 0|2@1+ (1,0) [0|0] "" Vector__XXX

BO_ 1061 APP_factorySummonGoal: 8 Vector__XXX
 SG_ APP_factoryGoalSpeed : 57|7@1+ (1,0) [0|0] "" Vector__XXX
 SG_ APP_factoryGoalLongitude : 28|29@1- (1e-06,0) [0|0] "" Vector__XXX
 SG_ APP_factoryGoalLatitude : 0|28@1- (1e-06,0) [0|0] "" Vector__XXX

BO_ 1064 UI_telemetryControl: 8 Vector__XXX
 SG_ UI_TCR_maxRoadClass : 61|3@1+ (1,0) [0|0] "" Vector__XXX
 SG_ UI_TCR_maxObjects : 56|5@1+ (1,0) [0|0] "" Vector__XXX
 SG_ UI_TCR_maxDy : 48|5@1+ (0.5,0) [0|0] "" Vector__XXX
 SG_ UI_TCR_minRCS : 40|8@1+ (0.25,-14) [0|0] "" Vector__XXX
 SG_ UI_TCR_vehSpeed : 32|8@1+ (1,0) [0|0] "" Vector__XXX
 SG_ UI_TCR_wExist : 24|5@1+ (1,0) [0|0] "" Vector__XXX
 SG_ UI_TCR_downSampleFactor : 10|4@1+ (1,0) [0|0] "" Vector__XXX
 SG_ UI_TCR_classUnknown : 9|1@1+ (1,0) [0|0] "" Vector__XXX
 SG_ UI_TCR_classMovingFourWheel : 8|1@1+ (1,0) [0|0] "" Vector__XXX
 SG_ UI_TCR_classMovingTwoWheel : 7|1@1+ (1,0) [0|0] "" Vector__XXX
 SG_ UI_TCR_classMovingPed : 6|1@1+ (1,0) [0|0] "" Vector__XXX
 SG_ UI_TCR_classConstElem : 5|1@1+ (1,0) [0|0] "" Vector__XXX
 SG_ UI_TCR_moveStateIndeterm : 4|1@1+ (1,0) [0|0] "" Vector__XXX
 SG_ UI_TCR_moveStateMoving : 3|1@1+ (1,0) [0|0] "" Vector__XXX
 SG_ UI_TCR_moveStateStopped : 2|1@1+ (1,0) [0|0] "" Vector__XXX
 SG_ UI_TCR_moveStateStanding : 1|1@1+ (1,0) [0|0] "" Vector__XXX
 SG_ UI_TCR_enable : 0|1@1+ (1,0) [0|0] "" Vector__XXX

BO_ 1065 APP_warningMatrix2: 8 Vector__XXX
 SG_ APP_w192_emergencySpeakerFail : 63|1@1+ (1,0) [0|0] "" Vector__XXX
 SG_ APP_w191_autopilotAborting : 62|1@1+ (1,0) [0|0] "" Vector__XXX
 SG_ APP_w190_selfieCameraStreamExit : 61|1@1+ (1,0) [0|0] "" Vector__XXX
 SG_ APP_w189_backupCameraStreamExit : 60|1@1+ (1,0) [0|0] "" Vector__XXX
 SG_ APP_w188_rRepeatCameraStreamExit : 59|1@1+ (1,0) [0|0] "" Vector__XXX
 SG_ APP_w187_lRepeatCameraStreamExit : 58|1@1+ (1,0) [0|0] "" Vector__XXX
 SG_ APP_w186_rPillarCameraStreamExit : 57|1@1+ (1,0) [0|0] "" Vector__XXX
 SG_ APP_w185_lPillarCameraStreamExit : 56|1@1+ (1,0) [0|0] "" Vector__XXX
 SG_ APP_w184_fisheyeCameraStreamExit : 55|1@1+ (1,0) [0|0] "" Vector__XXX
 SG_ APP_w183_narrowCameraStreamExit : 54|1@1+ (1,0) [0|0] "" Vector__XXX
 SG_ APP_w182_mainCameraStreamExit : 53|1@1+ (1,0) [0|0] "" Vector__XXX
 SG_ APP_w181_rRepeatCamCalSaved : 52|1@1+ (1,0) [0|0] "" Vector__XXX
 SG_ APP_w180_lRepeatCamCalSaved : 51|1@1+ (1,0) [0|0] "" Vector__XXX
 SG_ APP_w179_rPillarCamCalSaved : 50|1@1+ (1,0) [0|0] "" Vector__XXX
 SG_ APP_w178_lPillarCamCalSaved : 49|1@1+ (1,0) [0|0] "" Vector__XXX
 SG_ APP_w177_fisheyeCamCalSaved : 48|1@1+ (1,0) [0|0] "" Vector__XXX
 SG_ APP_w176_rRepeatCamExtNotCal : 47|1@1+ (1,0) [0|0] "" Vector__XXX
 SG_ APP_w175_lRepeatCamExtNotCal : 46|1@1+ (1,0) [0|0] "" Vector__XXX
 SG_ APP_w174_rPillarCamExtNotCal : 45|1@1+ (1,0) [0|0] "" Vector__XXX
 SG_ APP_w173_lPillarCamExtNotCal : 44|1@1+ (1,0) [0|0] "" Vector__XXX
 SG_ APP_w172_fisheyeCamExtNotCal : 43|1@1+ (1,0) [0|0] "" Vector__XXX
 SG_ APP_w171_appHighCoolantFlowReq : 42|1@1+ (1,0) [0|0] "" Vector__XXX
 SG_ APP_w170_selfieCameraTypeError : 41|1@1+ (1,0) [0|0] "" Vector__XXX
 SG_ APP_w169_backupCameraTypeError : 40|1@1+ (1,0) [0|0] "" Vector__XXX
 SG_ APP_w168_rRepeatCameraTypeError : 39|1@1+ (1,0) [0|0] "" Vector__XXX
 SG_ APP_w167_lRepeatCameraTypeError : 38|1@1+ (1,0) [0|0] "" Vector__XXX
 SG_ APP_w166_rPillarCameraTypeError : 37|1@1+ (1,0) [0|0] "" Vector__XXX
 SG_ APP_w165_lPillarCameraTypeError : 36|1@1+ (1,0) [0|0] "" Vector__XXX
 SG_ APP_w164_fisheyeCameraTypeError : 35|1@1+ (1,0) [0|0] "" Vector__XXX
 SG_ APP_w163_narrowCameraTypeError : 34|1@1+ (1,0) [0|0] "" Vector__XXX
 SG_ APP_w162_mainCameraTypeError : 33|1@1+ (1,0) [0|0] "" Vector__XXX
 SG_ APP_w161_backupCameraUnavailable : 32|1@1+ (1,0) [0|0] "" Vector__XXX
 SG_ APP_w160_vcrightMiaVehBus : 31|1@1+ (1,0) [0|0] "" Vector__XXX
 SG_ APP_w159_vcleftMiaVehBus : 30|1@1+ (1,0) [0|0] "" Vector__XXX
 SG_ APP_w158_vcfrontMiaVehBus : 29|1@1+ (1,0) [0|0] "" Vector__XXX
 SG_ APP_w157_sccmMiaVehBus : 28|1@1+ (1,0) [0|0] "" Vector__XXX
 SG_ APP_w156_epblMiaVehBus : 27|1@1+ (1,0) [0|0] "" Vector__XXX
 SG_ APP_w155_vcrightMiaPartyBus : 26|1@1+ (1,0) [0|0] "" Vector__XXX
 SG_ APP_w154_vcleftMiaPartyBus : 25|1@1+ (1,0) [0|0] "" Vector__XXX
 SG_ APP_w153_rcmMiaPartyBus : 24|1@1+ (1,0) [0|0] "" Vector__XXX
 SG_ APP_w152_espMiaPartyBus : 23|1@1+ (1,0) [0|0] "" Vector__XXX
 SG_ APP_w151_epasMiaPartyBus : 22|1@1+ (1,0) [0|0] "" Vector__XXX
 SG_ APP_w150_diMiaPartyBus : 21|1@1+ (1,0) [0|0] "" Vector__XXX
 SG_ APP_w149_diskFull : 20|1@1+ (1,0) [0|0] "" Vector__XXX
 SG_ APP_w148_overlayActive : 19|1@1+ (1,0) [0|0] "" Vector__XXX
 SG_ APP_w147_selfieCamInitFault : 18|1@1+ (1,0) [0|0] "" Vector__XXX
 SG_ APP_w146_telemetryProblem : 17|1@1+ (1,0) [0|0] "" Vector__XXX
 SG_ APP_w145_camSelfCalIssue : 16|1@1+ (1,0) [0|0] "" Vector__XXX
 SG_ APP_w144_fanctrldError : 15|1@1+ (1,0) [0|0] "" Vector__XXX
 SG_ APP_w143_IDF_event : 14|1@1+ (1,0) [0|0] "" Vector__XXX
 SG_ APP_w142_fwdCamPitchProblem : 13|1@1+ (1,0) [0|0] "" Vector__XXX
 SG_ APP_w141_ECU_Thermal_Issue : 12|1@1+ (1,0) [0|0] "" Vector__XXX
 SG_ APP_w140_backupCamInitFault : 11|1@1+ (1,0) [0|0] "" Vector__XXX
 SG_ APP_w139_rRepeatCamInitFault : 10|1@1+ (1,0) [0|0] "" Vector__XXX
 SG_ APP_w138_lRepeatCamInitFault : 9|1@1+ (1,0) [0|0] "" Vector__XXX
 SG_ APP_w137_rPillarCamInitFault : 8|1@1+ (1,0) [0|0] "" Vector__XXX
 SG_ APP_w136_lPillarCamInitFault : 7|1@1+ (1,0) [0|0] "" Vector__XXX
 SG_ APP_w135_fisheyeCamInitFault : 6|1@1+ (1,0) [0|0] "" Vector__XXX
 SG_ APP_w134_narrowCamInitFault : 5|1@1+ (1,0) [0|0] "" Vector__XXX
 SG_ APP_w133_mainCamInitFault : 4|1@1+ (1,0) [0|0] "" Vector__XXX
 SG_ APP_w132_narrowCamCalSaved : 3|1@1+ (1,0) [0|0] "" Vector__XXX
 SG_ APP_w131_mainCamCalSaved : 2|1@1+ (1,0) [0|0] "" Vector__XXX
 SG_ APP_w130_narrowCamExtNotCal : 1|1@1+ (1,0) [0|0] "" Vector__XXX
 SG_ APP_w129_mainCamExtNotCal : 0|1@1+ (1,0) [0|0] "" Vector__XXX

BO_ 1081 APP_warningMatrix3: 8 Vector__XXX
 SG_ APP_w235_fsdRegionNotAllowed : 42|1@1+ (1,0) [0|0] "" Vector__XXX
 SG_ APP_w234_activeSafetyTelemetry : 41|1@1+ (1,0) [0|0] "" Vector__XXX
 SG_ APP_w233_fsdQuizRequired : 40|1@1+ (1,0) [0|0] "" Vector__XXX
 SG_ APP_w232_laneChangeRequested : 39|1@1+ (1,0) [0|0] "" Vector__XXX
 SG_ APP_w231_idfEvent : 38|1@1+ (1,0) [0|0] "" Vector__XXX
 SG_ APP_w230_alcUltrasoundBlocked : 37|1@1+ (1,0) [0|0] "" Vector__XXX
 SG_ APP_w229_alcUltrasoundDamaged : 36|1@1+ (1,0) [0|0] "" Vector__XXX
 SG_ APP_w228_DEPRECATED : 35|1@1+ (1,0) [0|0] "" Vector__XXX
 SG_ APP_w227_virtualWallBlocked : 34|1@1+ (1,0) [0|0] "" Vector__XXX
 SG_ APP_w226_lcCamCalNeededSpeedLmt : 33|1@1+ (1,0) [0|0] "" Vector__XXX
 SG_ APP_w225_lcDegradedVisSpeedLmt : 32|1@1+ (1,0) [0|0] "" Vector__XXX
 SG_ APP_w224_accCameraCalibration : 31|1@1+ (1,0) [0|0] "" Vector__XXX
 SG_ APP_w223_accObjectInPath : 30|1@1+ (1,0) [0|0] "" Vector__XXX
 SG_ APP_w222_accCameraBlind : 29|1@1+ (1,0) [0|0] "" Vector__XXX
 SG_ APP_w221_accRadarBlind : 28|1@1+ (1,0) [0|0] "" Vector__XXX
 SG_ APP_w220_lcTempUnavailableRoad : 27|1@1+ (1,0) [0|0] "" Vector__XXX
 SG_ APP_w219_lcTempUnavailableSpeed : 26|1@1+ (1,0) [0|0] "" Vector__XXX
 SG_ APP_w218_lcSpeedExceededLimit : 25|1@1+ (1,0) [0|0] "" Vector__XXX
 SG_ APP_w217_lcUnavailableSpeeding : 24|1@1+ (1,0) [0|0] "" Vector__XXX
 SG_ APP_w216_driverOverriding : 23|1@1+ (1,0) [0|0] "" Vector__XXX
 SG_ APP_w215_contDriverNotIntracting : 22|1@1+ (1,0) [0|0] "" Vector__XXX
 SG_ APP_w214_driverNotIntracting : 21|1@1+ (1,0) [0|0] "" Vector__XXX
 SG_ APP_w213_autosteerStruckOut : 20|1@1+ (1,0) [0|0] "" Vector__XXX
 SG_ APP_w212_lcUnavailableStrikeOut : 19|1@1+ (1,0) [0|0] "" Vector__XXX
 SG_ APP_w211_accNoSeatBelt : 18|1@1+ (1,0) [0|0] "" Vector__XXX
 SG_ APP_w210_camObstrcted : 17|1@1+ (1,0) [0|0] "" Vector__XXX
 SG_ APP_w209_autoSummonRequest : 16|1@1+ (1,0) [0|0] "" Vector__XXX
 SG_ APP_w208_rackDetected : 15|1@1+ (1,0) [0|0] "" Vector__XXX
 SG_ APP_w207_autosteerUnavailable : 14|1@1+ (1,0) [0|0] "" Vector__XXX
 SG_ APP_w206_autosteerNotEnabled : 13|1@1+ (1,0) [0|0] "" Vector__XXX
 SG_ APP_w205_apcFinalRear : 12|1@1+ (1,0) [0|0] "" Vector__XXX
 SG_ APP_w204_apcFinalFront : 11|1@1+ (1,0) [0|0] "" Vector__XXX
 SG_ APP_w203_apcActivation : 10|1@1+ (1,0) [0|0] "" Vector__XXX
 SG_ APP_w202_scwNoisyEnvironment : 9|1@1+ (1,0) [0|0] "" Vector__XXX
 SG_ APP_w201_lcAborting : 8|1@1+ (1,0) [0|0] "" Vector__XXX
 SG_ APP_w200_lcSlowdown : 7|1@1+ (1,0) [0|0] "" Vector__XXX
 SG_ APP_w199_apcAbort : 6|1@1+ (1,0) [0|0] "" Vector__XXX
 SG_ APP_w198_tsrUnavailable : 5|1@1+ (1,0) [0|0] "" Vector__XXX
 SG_ APP_w197_redLightWarning : 4|1@1+ (1,0) [0|0] "" Vector__XXX
 SG_ APP_w196_stopSignWarning : 3|1@1+ (1,0) [0|0] "" Vector__XXX
 SG_ APP_w195_scwUnavailable : 2|1@1+ (1,0) [0|0] "" Vector__XXX
 SG_ APP_w194_accDriverResumeRqrd : 1|1@1+ (1,0) [0|0] "" Vector__XXX
 SG_ APP_w193_camWindshieldUnclean : 0|1@1+ (1,0) [0|0] "" Vector__XXX

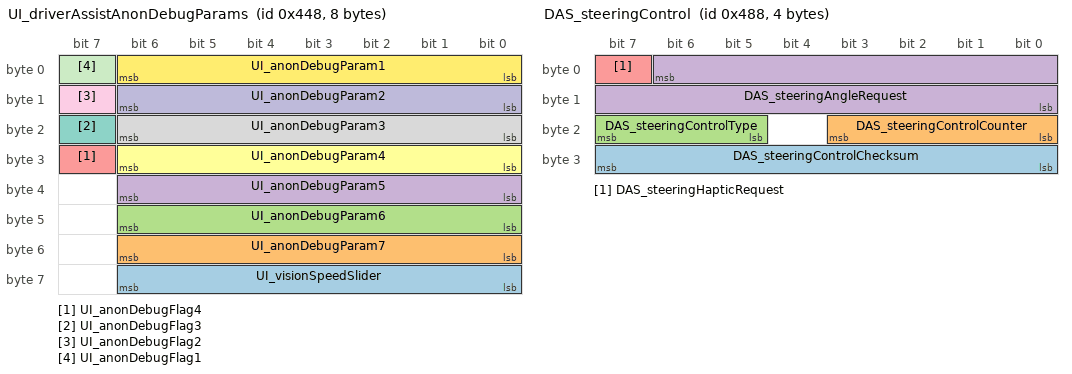
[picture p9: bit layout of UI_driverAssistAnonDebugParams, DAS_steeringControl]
BO_ 1096 UI_driverAssistAnonDebugParams: 8 Vector__XXX
 SG_ UI_visionSpeedSlider : 56|7@1+ (1,0) [0|0] "" Vector__XXX
 SG_ UI_anonDebugParam7 : 48|7@1+ (1,0) [0|0] "" Vector__XXX
 SG_ UI_anonDebugParam6 : 40|7@1+ (1,0) [0|0] "" Vector__XXX
 SG_ UI_anonDebugParam5 : 32|7@1+ (1,0) [0|0] "" Vector__XXX
 SG_ UI_anonDebugFlag4 : 31|1@1+ (1,0) [0|0] "" Vector__XXX
 SG_ UI_anonDebugParam4 : 24|7@1+ (1,0) [0|0] "" Vector__XXX
 SG_ UI_anonDebugFlag3 : 23|1@1+ (1,0) [0|0] "" Vector__XXX
 SG_ UI_anonDebugParam3 : 16|7@1+ (1,0) [0|0] "" Vector__XXX
 SG_ UI_anonDebugFlag2 : 15|1@1+ (1,0) [0|0] "" Vector__XXX
 SG_ UI_anonDebugParam2 : 8|7@1+ (1,0) [0|0] "" Vector__XXX
 SG_ UI_anonDebugFlag1 : 7|1@1+ (1,0) [0|0] "" Vector__XXX
 SG_ UI_anonDebugParam1 : 0|7@1+ (1,0) [0|0] "" Vector__XXX

BO_ 1097 APP_warningMatrix4: 8 Vector__XXX
 SG_ APP_w320_selfieCamTypeMismatch : 63|1@1+ (1,0) [0|0] "" Vector__XXX
 SG_ APP_w319_backupCamTypeMismatch : 62|1@1+ (1,0) [0|0] "" Vector__XXX
 SG_ APP_w318_rRepeatCamTypeMismatch : 61|1@1+ (1,0) [0|0] "" Vector__XXX
 SG_ APP_w317_lRepeatCamTypeMismatch : 60|1@1+ (1,0) [0|0] "" Vector__XXX
 SG_ APP_w316_rPillarCamTypeMismatch : 59|1@1+ (1,0) [0|0] "" Vector__XXX
 SG_ APP_w315_lPillarCamTypeMismatch : 58|1@1+ (1,0) [0|0] "" Vector__XXX
 SG_ APP_w314_fisheyeCamTypeMismatch : 57|1@1+ (1,0) [0|0] "" Vector__XXX
 SG_ APP_w313_narrowCamTypeMismatch : 56|1@1+ (1,0) [0|0] "" Vector__XXX
 SG_ APP_w312_mainCamTypeMismatch : 55|1@1+ (1,0) [0|0] "" Vector__XXX
 SG_ APP_w311_eth1FrameErrors : 54|1@1+ (1,0) [0|0] "" Vector__XXX
 SG_ APP_w310_eth0FrameErrors : 53|1@1+ (1,0) [0|0] "" Vector__XXX
 SG_ APP_w309_selfieDisabledOnCar : 52|1@1+ (1,0) [0|0] "" Vector__XXX
 SG_ APP_w308_iboosterMia : 51|1@1+ (1,0) [0|0] "" Vector__XXX
 SG_ APP_w307_lssTurnSignalFault : 50|1@1+ (1,0) [0|0] "" Vector__XXX
 SG_ APP_w306_lssUltrasonicsBlocked : 49|1@1+ (1,0) [0|0] "" Vector__XXX
 SG_ APP_w305_lssCamStreamExit : 48|1@1+ (1,0) [0|0] "" Vector__XXX
 SG_ APP_w304_lssCamBlockedStatus : 47|1@1+ (1,0) [0|0] "" Vector__XXX
 SG_ APP_w303_imuIrational : 46|1@1+ (1,0) [0|0] "" Vector__XXX
 SG_ APP_w302_vcfrontMiaPartyBus : 45|1@1+ (1,0) [0|0] "" Vector__XXX
 SG_ APP_w301_selfieCameraSyncFailed : 44|1@1+ (1,0) [0|0] "" Vector__XXX
 SG_ APP_w300_backupCameraSyncFailed : 43|1@1+ (1,0) [0|0] "" Vector__XXX
 SG_ APP_w299_rRepeatCameraSyncFailed : 42|1@1+ (1,0) [0|0] "" Vector__XXX
 SG_ APP_w298_lRepeatCameraSyncFailed : 41|1@1+ (1,0) [0|0] "" Vector__XXX
 SG_ APP_w297_rPillarCameraSyncFailed : 40|1@1+ (1,0) [0|0] "" Vector__XXX
 SG_ APP_w296_lPillarCameraSyncFailed : 39|1@1+ (1,0) [0|0] "" Vector__XXX
 SG_ APP_w295_fisheyeCameraSyncFailed : 38|1@1+ (1,0) [0|0] "" Vector__XXX
 SG_ APP_w294_narrowCameraSyncFailed : 37|1@1+ (1,0) [0|0] "" Vector__XXX
 SG_ APP_w293_mainCameraSyncFailed : 36|1@1+ (1,0) [0|0] "" Vector__XXX
 SG_ APP_w291_stopSignWarning : 34|1@1+ (1,0) [0|0] "" Vector__XXX
 SG_ APP_w290_dramUncorrEccErrors : 33|1@1+ (1,0) [0|0] "" Vector__XXX
 SG_ APP_w289_dramCorrEccErrors : 32|1@1+ (1,0) [0|0] "" Vector__XXX
 SG_ APP_w288_trafficLightWarning : 31|1@1+ (1,0) [0|0] "" Vector__XXX
 SG_ APP_w287_gpsFusionStatus : 30|1@1+ (1,0) [0|0] "" Vector__XXX
 SG_ APP_w286_gpsComIssue : 29|1@1+ (1,0) [0|0] "" Vector__XXX
 SG_ APP_w285_gpsFaultReset : 28|1@1+ (1,0) [0|0] "" Vector__XXX
 SG_ APP_w284_gpsAntennaDisconnected : 27|1@1+ (1,0) [0|0] "" Vector__XXX
 SG_ APP_w283_enhancedSummonAbort : 26|1@1+ (1,0) [0|0] "" Vector__XXX
 SG_ APP_w282_selfieCameraStreamErr : 25|1@1+ (1,0) [0|0] "" Vector__XXX
 SG_ APP_w281_backupCameraStreamErr : 24|1@1+ (1,0) [0|0] "" Vector__XXX
 SG_ APP_w280_rRepeatCameraStreamErr : 23|1@1+ (1,0) [0|0] "" Vector__XXX
 SG_ APP_w279_lRepeatCameraStreamErr : 22|1@1+ (1,0) [0|0] "" Vector__XXX
 SG_ APP_w278_rPillarCameraStreamErr : 21|1@1+ (1,0) [0|0] "" Vector__XXX
 SG_ APP_w277_lPillarCameraStreamErr : 20|1@1+ (1,0) [0|0] "" Vector__XXX
 SG_ APP_w276_fisheyeCameraStreamErr : 19|1@1+ (1,0) [0|0] "" Vector__XXX
 SG_ APP_w275_narrowCameraStreamErr : 18|1@1+ (1,0) [0|0] "" Vector__XXX
 SG_ APP_w274_mainCameraStreamErr : 17|1@1+ (1,0) [0|0] "" Vector__XXX
 SG_ APP_w273_lssEvent : 16|1@1+ (1,0) [0|0] "" Vector__XXX
 SG_ APP_w272_laneChangeUnavailable : 15|1@1+ (1,0) [0|0] "" Vector__XXX
 SG_ APP_w271_laneChangeAborted : 14|1@1+ (1,0) [0|0] "" Vector__XXX
 SG_ APP_w270_blindspotRestricted : 13|1@1+ (1,0) [0|0] "" Vector__XXX
 SG_ APP_w269_autopilotLimited : 12|1@1+ (1,0) [0|0] "" Vector__XXX
 SG_ APP_w268_backupCamExtNotCal : 11|1@1+ (1,0) [0|0] "" Vector__XXX
 SG_ APP_w267_benchtopEcu : 10|1@1+ (1,0) [0|0] "" Vector__XXX
 SG_ APP_w266_visionScheduleFallback : 9|1@1+ (1,0) [0|0] "" Vector__XXX
 SG_ APP_w265_drvOnNavUnavailable : 8|1@1+ (1,0) [0|0] "" Vector__XXX
 SG_ APP_w264_lssFault : 7|1@1+ (1,0) [0|0] "" Vector__XXX
 SG_ APP_w263_lssAbort : 6|1@1+ (1,0) [0|0] "" Vector__XXX
 SG_ APP_w262_apeCalibMode : 5|1@1+ (1,0) [0|0] "" Vector__XXX
 SG_ APP_w261_pcieHardwareErrors : 4|1@1+ (1,0) [0|0] "" Vector__XXX
 SG_ APP_w260_collisionWarningEvent : 3|1@1+ (1,0) [0|0] "" Vector__XXX
 SG_ APP_w259_aebOverrideEvent : 2|1@1+ (1,0) [0|0] "" Vector__XXX
 SG_ APP_w258_aebEvent : 1|1@1+ (1,0) [0|0] "" Vector__XXX
 SG_ APP_w257_brakeJerkEvent : 0|1@1+ (1,0) [0|0] "" Vector__XXX

BO_ 1113 APS_warningMatrix2: 8 Vector__XXX
 SG_ APS_w192_CANFault : 63|1@1+ (1,0) [0|0] "" Vector__XXX
 SG_ APS_w191_timesyncError : 62|1@1+ (1,0) [0|0] "" Vector__XXX
 SG_ APS_w190_iboosterMia : 61|1@1+ (1,0) [0|0] "" Vector__XXX
 SG_ APS_w189_vcfrontMiaPartyBus : 60|1@1+ (1,0) [0|0] "" Vector__XXX
 SG_ APS_w188_otherTurboUartMIA : 59|1@1+ (1,0) [0|0] "" Vector__XXX
 SG_ APS_w187_TurboB_SMS_taskUtilErr : 58|1@1+ (1,0) [0|0] "" Vector__XXX
 SG_ APS_w186_TurboB_A72_watchdog : 57|1@1+ (1,0) [0|0] "" Vector__XXX
 SG_ APS_w185_TurboB_SCS_LKUP : 56|1@1+ (1,0) [0|0] "" Vector__XXX
 SG_ APS_w184_TurboB_SMS_WDOG : 55|1@1+ (1,0) [0|0] "" Vector__XXX
 SG_ APS_w183_TurboB_TMU_Throttle : 54|1@1+ (1,0) [0|0] "" Vector__XXX
 SG_ APS_w182_TurboB_SMSLockStepErr : 53|1@1+ (1,0) [0|0] "" Vector__XXX
 SG_ APS_w181_TurboB_Temp_NOS : 52|1@1+ (1,0) [0|0] "" Vector__XXX
 SG_ APS_w180_TurboB_12VFuseFault : 51|1@1+ (1,0) [0|0] "" Vector__XXX
 SG_ APS_w179_TurboB_DisRegNFault : 50|1@1+ (1,0) [0|0] "" Vector__XXX
 SG_ APS_w178_TurboB_DisRegPgoodErr : 49|1@1+ (1,0) [0|0] "" Vector__XXX
 SG_ APS_w172_apFeaturesUnavailable : 43|1@1+ (1,0) [0|0] "" Vector__XXX
 SG_ APS_w171_TurboA_SMS_taskUtilErr : 42|1@1+ (1,0) [0|0] "" Vector__XXX
 SG_ APS_w170_TurboA_A72_watchdog : 41|1@1+ (1,0) [0|0] "" Vector__XXX
 SG_ APS_w169_TurboA_SCS_LKUP : 40|1@1+ (1,0) [0|0] "" Vector__XXX
 SG_ APS_w168_TurboA_SMS_WDOG : 39|1@1+ (1,0) [0|0] "" Vector__XXX
 SG_ APS_w167_TurboA_TMU_Throttle : 38|1@1+ (1,0) [0|0] "" Vector__XXX
 SG_ APS_w166_TurboA_SMSLockStepErr : 37|1@1+ (1,0) [0|0] "" Vector__XXX
 SG_ APS_w165_TurboA_Temp_NOS : 36|1@1+ (1,0) [0|0] "" Vector__XXX
 SG_ APS_w164_TurboA_12VFuseFault : 35|1@1+ (1,0) [0|0] "" Vector__XXX
 SG_ APS_w163_TurboA_DisRegNFault : 34|1@1+ (1,0) [0|0] "" Vector__XXX
 SG_ APS_w162_TurboA_DisRegPgoodErr : 33|1@1+ (1,0) [0|0] "" Vector__XXX
 SG_ APS_w161_gpsAntennaDisconnected : 32|1@1+ (1,0) [0|0] "" Vector__XXX
 SG_ APS_w160_apbVersionMismatch : 31|1@1+ (1,0) [0|0] "" Vector__XXX
 SG_ APS_w159_apbCritical : 30|1@1+ (1,0) [0|0] "" Vector__XXX
 SG_ APS_w158_apbMia : 29|1@1+ (1,0) [0|0] "" Vector__XXX
 SG_ APS_w157_autopilotReboot : 28|1@1+ (1,0) [0|0] "" Vector__XXX
 SG_ APS_w156_lwipAssert : 27|1@1+ (1,0) [0|0] "" Vector__XXX
 SG_ APS_w155_ethLwipError : 26|1@1+ (1,0) [0|0] "" Vector__XXX
 SG_ APS_w153_eacInhibit : 24|1@1+ (1,0) [0|0] "" Vector__XXX
 SG_ APS_w152_gpsFusionStatus : 23|1@1+ (1,0) [0|0] "" Vector__XXX
 SG_ APS_w151_apRecovered : 22|1@1+ (1,0) [0|0] "" Vector__XXX
 SG_ APS_w150_sccmMiaVehBus : 21|1@1+ (1,0) [0|0] "" Vector__XXX
 SG_ APS_w149_epblMiaVehBus : 20|1@1+ (1,0) [0|0] "" Vector__XXX
 SG_ APS_w148_vcrightMiaVehBus : 19|1@1+ (1,0) [0|0] "" Vector__XXX
 SG_ APS_w147_vcleftMiaVehBus : 18|1@1+ (1,0) [0|0] "" Vector__XXX
 SG_ APS_w146_epas3pMiaPartyBus : 17|1@1+ (1,0) [0|0] "" Vector__XXX
 SG_ APS_w145_vcrightMiaPartyBus : 16|1@1+ (1,0) [0|0] "" Vector__XXX
 SG_ APS_w144_vcleftMiaPartyBus : 15|1@1+ (1,0) [0|0] "" Vector__XXX
 SG_ APS_w143_espMiaPartyBus : 14|1@1+ (1,0) [0|0] "" Vector__XXX
 SG_ APS_w142_diMiaPartyBus : 13|1@1+ (1,0) [0|0] "" Vector__XXX
 SG_ APS_w141_rcmMiaPartyBus : 12|1@1+ (1,0) [0|0] "" Vector__XXX
 SG_ APS_w140_vcfrontMiaVehicleBus : 11|1@1+ (1,0) [0|0] "" Vector__XXX
 SG_ APS_w139_udpBufferOverflow : 10|1@1+ (1,0) [0|0] "" Vector__XXX
 SG_ APS_w138_gpsComIssue : 9|1@1+ (1,0) [0|0] "" Vector__XXX
 SG_ APS_w137_gpsFaultReset : 8|1@1+ (1,0) [0|0] "" Vector__XXX
 SG_ APS_w136_gpsDisabled : 7|1@1+ (1,0) [0|0] "" Vector__XXX
 SG_ APS_w135_appCritical : 6|1@1+ (1,0) [0|0] "" Vector__XXX
 SG_ APS_w134_appMia : 5|1@1+ (1,0) [0|0] "" Vector__XXX
 SG_ APS_w133_ETHSwitchError : 4|1@1+ (1,0) [0|0] "" Vector__XXX
 SG_ APS_w132_appVersionMismatch : 3|1@1+ (1,0) [0|0] "" Vector__XXX
 SG_ APS_w131_trap_exception : 2|1@1+ (1,0) [0|0] "" Vector__XXX
 SG_ APS_w130_ECU_Thermal_Issue : 1|1@1+ (1,0) [0|0] "" Vector__XXX
 SG_ APS_w129_ECU_Power_Issue : 0|1@1+ (1,0) [0|0] "" Vector__XXX

BO_ 1149 APP_warningMatrix6: 8 Vector__XXX
 SG_ APP_w448_leftRepeaterImagerConfigMismatch : 63|1@1+ (1,0) [0|0] "" Vector__XXX
 SG_ APP_w447_rightPillarImagerConfigMismatch : 62|1@1+ (1,0) [0|0] "" Vector__XXX
 SG_ APP_w446_leftPillarImagerConfigMismatch : 61|1@1+ (1,0) [0|0] "" Vector__XXX
 SG_ APP_w445_fisheyeImagerConfigMismatch : 60|1@1+ (1,0) [0|0] "" Vector__XXX
 SG_ APP_w444_narrowImagerConfigMismatch : 59|1@1+ (1,0) [0|0] "" Vector__XXX
 SG_ APP_w443_mainImagerConfigMismatch : 58|1@1+ (1,0) [0|0] "" Vector__XXX
 SG_ APP_w442_autonomyCancelMethod : 57|1@1+ (1,0) [0|0] "" Vector__XXX
 SG_ APP_w441_cabinCamLEDRailOff : 56|1@1+ (1,0) [0|0] "" Vector__XXX
 SG_ APP_w440_lensHoodOcclusion : 55|1@1+ (1,0) [0|0] "" Vector__XXX
 SG_ APP_w439_ethernetCommFailure : 54|1@1+ (1,0) [0|0] "" Vector__XXX
 SG_ APP_w438_rcuMia : 53|1@1+ (1,0) [0|0] "" Vector__XXX
 SG_ APP_w437_missingCloudEepromData : 52|1@1+ (1,0) [0|0] "" Vector__XXX
 SG_ APP_w436_camCsiError : 51|1@1+ (1,0) [0|0] "" Vector__XXX
 SG_ APP_w435_repeaterAeroRibInfoMismatched : 50|1@1+ (1,0) [0|0] "" Vector__XXX
 SG_ APP_w434_rightRepeaterDowngradeDetected : 49|1@1+ (1,0) [0|0] "" Vector__XXX
 SG_ APP_w433_leftRepeaterDowngradeDetected : 48|1@1+ (1,0) [0|0] "" Vector__XXX
 SG_ APP_w432_frontVisibilityDegraded_HIGH : 47|1@1+ (1,0) [0|0] "" Vector__XXX
 SG_ APP_w431_frontVisibilityDegraded_MEDIUM : 46|1@1+ (1,0) [0|0] "" Vector__XXX
 SG_ APP_w430_frontVisibilityDegraded_LOW : 45|1@1+ (1,0) [0|0] "" Vector__XXX
 SG_ APP_w429_cameraVisPopUpFascia : 44|1@1+ (1,0) [0|0] "" Vector__XXX
 SG_ APP_w428_cameraVisPopUpBackup : 43|1@1+ (1,0) [0|0] "" Vector__XXX
 SG_ APP_w427_cameraVisPopUpRRepeater : 42|1@1+ (1,0) [0|0] "" Vector__XXX
 SG_ APP_w426_cameraVisPopUpLRepeater : 41|1@1+ (1,0) [0|0] "" Vector__XXX
 SG_ APP_w425_cameraVisPopUpRPillar : 40|1@1+ (1,0) [0|0] "" Vector__XXX
 SG_ APP_w424_cameraVisPopUpLPillar : 39|1@1+ (1,0) [0|0] "" Vector__XXX
 SG_ APP_w423_cameraVisPopUpForward : 38|1@1+ (1,0) [0|0] "" Vector__XXX
 SG_ APP_w422_autonomyDegradedUser : 37|1@1+ (1,0) [0|0] "" Vector__XXX
 SG_ APP_w421_autonomyUnavailableUser : 36|1@1+ (1,0) [0|0] "" Vector__XXX
 SG_ APP_w420_autonomyDegradedApSystem : 35|1@1+ (1,0) [0|0] "" Vector__XXX
 SG_ APP_w419_autonomyUnavailableApSystem : 34|1@1+ (1,0) [0|0] "" Vector__XXX
 SG_ APP_w418_autonomyDegradedVisibility : 33|1@1+ (1,0) [0|0] "" Vector__XXX
 SG_ APP_w417_autonomyUnavailableVisibility : 32|1@1+ (1,0) [0|0] "" Vector__XXX
 SG_ APP_w416_autonomyDegradedSystem : 31|1@1+ (1,0) [0|0] "" Vector__XXX
 SG_ APP_w415_autonomyUnavailableSystem : 30|1@1+ (1,0) [0|0] "" Vector__XXX
 SG_ APP_w413_autonomyDegraded5 : 28|1@1+ (1,0) [0|0] "" Vector__XXX
 SG_ APP_w412_abortBackupCamOccluded : 27|1@1+ (1,0) [0|0] "" Vector__XXX
 SG_ APP_w411_backupCameraOccluded : 26|1@1+ (1,0) [0|0] "" Vector__XXX
 SG_ APP_w410_autonomyDegraded4 : 25|1@1+ (1,0) [0|0] "" Vector__XXX
 SG_ APP_w409_autonomyDegraded3 : 24|1@1+ (1,0) [0|0] "" Vector__XXX
 SG_ APP_w408_autonomyDegraded2 : 23|1@1+ (1,0) [0|0] "" Vector__XXX
 SG_ APP_w407_autonomyDegraded1 : 22|1@1+ (1,0) [0|0] "" Vector__XXX
 SG_ APP_w406_gnssHWHealthDegraded : 21|1@1+ (1,0) [0|0] "" Vector__XXX
 SG_ APP_w405_apsMia : 20|1@1+ (1,0) [0|0] "" Vector__XXX
 SG_ APP_w404_epbrMiaVehBus : 19|1@1+ (1,0) [0|0] "" Vector__XXX
 SG_ APP_w403_notifyCameraSelfCleanAction : 18|1@1+ (1,0) [0|0] "" Vector__XXX
 SG_ APP_w402_rightPillarCameraHeaterFaulted : 17|1@1+ (1,0) [0|0] "" Vector__XXX
 SG_ APP_w401_leftPillarCameraHeaterFaulted : 16|1@1+ (1,0) [0|0] "" Vector__XXX
 SG_ APP_w400_selfieCameraFanFault : 15|1@1+ (1,0) [0|0] "" Vector__XXX
 SG_ APP_w399_brakeboosterMia : 14|1@1+ (1,0) [0|0] "" Vector__XXX
 SG_ APP_w398_imuOutputUnhealthy : 13|1@1+ (1,0) [0|0] "" Vector__XXX
 SG_ APP_w397_apFeatDisabledPermanent : 12|1@1+ (1,0) [0|0] "" Vector__XXX
 SG_ APP_w396_severeResidueDetected : 11|1@1+ (1,0) [0|0] "" Vector__XXX
 SG_ APP_w395_cabinCameraLEDFaultSvc : 10|1@1+ (1,0) [0|0] "" Vector__XXX
 SG_ APP_w394_apImuGrossErrors : 9|1@1+ (1,0) [0|0] "" Vector__XXX
 SG_ APP_w393_attnMntrUnavailable : 8|1@1+ (1,0) [0|0] "" Vector__XXX
 SG_ APP_w392_fsdSuspended : 7|1@1+ (1,0) [0|0] "" Vector__XXX
 SG_ APP_w391_cabinCameraBlockedonAP : 6|1@1+ (1,0) [0|0] "" Vector__XXX
 SG_ APP_w390_cabinCamVisDegraded : 5|1@1+ (1,0) [0|0] "" Vector__XXX
 SG_ APP_w389_camFovResidueDetected : 4|1@1+ (1,0) [0|0] "" Vector__XXX
 SG_ APP_w388_windshieldCameraHeaterFaulted : 3|1@1+ (1,0) [0|0] "" Vector__XXX
 SG_ APP_w387_radarBlockageDetected : 2|1@1+ (1,0) [0|0] "" Vector__XXX
 SG_ APP_w386_radarOnlyBrakingEvent : 1|1@1+ (1,0) [0|0] "" Vector__XXX
 SG_ APP_w385_posEngineUnhealthy : 0|1@1+ (1,0) [0|0] "" Vector__XXX

BO_ 1151 APP_warningMatrix5: 8 Vector__XXX
 SG_ APP_w384_posEngineInitInMotion : 63|1@1+ (1,0) [0|0] "" Vector__XXX
 SG_ APP_w383_manyApRebootsWhileInP : 62|1@1+ (1,0) [0|0] "" Vector__XXX
 SG_ APP_w382_ubloxImuTimestampIssue : 61|1@1+ (1,0) [0|0] "" Vector__XXX
 SG_ APP_w381_apImuTimestampIssue : 60|1@1+ (1,0) [0|0] "" Vector__XXX
 SG_ APP_w380_gnssPpsTimestampIssue : 59|1@1+ (1,0) [0|0] "" Vector__XXX
 SG_ APP_w379_positioningEngineMia : 58|1@1+ (1,0) [0|0] "" Vector__XXX
 SG_ APP_w378_ubloxImuMia : 57|1@1+ (1,0) [0|0] "" Vector__XXX
 SG_ APP_w377_apImuMia : 56|1@1+ (1,0) [0|0] "" Vector__XXX
 SG_ APP_w376_wheeltickCountMia : 55|1@1+ (1,0) [0|0] "" Vector__XXX
 SG_ APP_w375_gnssPpsMia : 54|1@1+ (1,0) [0|0] "" Vector__XXX
 SG_ APP_w374_gnssDataMia : 53|1@1+ (1,0) [0|0] "" Vector__XXX
 SG_ APP_w373_gnssUartError : 52|1@1+ (1,0) [0|0] "" Vector__XXX
 SG_ APP_w372_cabinCameraBlocked : 51|1@1+ (1,0) [0|0] "" Vector__XXX
 SG_ APP_w371_networkLoadingIssue : 50|1@1+ (1,0) [0|0] "" Vector__XXX
 SG_ APP_w370_accApUnavUserSettings : 49|1@1+ (1,0) [0|0] "" Vector__XXX
 SG_ APP_w369_cruiseWithSingleClick : 48|1@1+ (1,0) [0|0] "" Vector__XXX
 SG_ APP_w361_cabinCameraLEDFault : 40|1@1+ (1,0) [0|0] "" Vector__XXX
 SG_ APP_w360_apImuNoiseDetected : 39|1@1+ (1,0) [0|0] "" Vector__XXX
 SG_ APP_w359_aebDegraded : 38|1@1+ (1,0) [0|0] "" Vector__XXX
 SG_ APP_w358_isaSystemFault : 37|1@1+ (1,0) [0|0] "" Vector__XXX
 SG_ APP_w357_ddawSystemFault : 36|1@1+ (1,0) [0|0] "" Vector__XXX
 SG_ APP_w356_driverOverriding : 35|1@1+ (1,0) [0|0] "" Vector__XXX
 SG_ APP_w355_camQuadPowerFault : 34|1@1+ (1,0) [0|0] "" Vector__XXX
 SG_ APP_w354_tradfcMia : 33|1@1+ (1,0) [0|0] "" Vector__XXX
 SG_ APP_w353_csiDevice2Down : 32|1@1+ (1,0) [0|0] "" Vector__XXX
 SG_ APP_w352_csiDevice1Down : 31|1@1+ (1,0) [0|0] "" Vector__XXX
 SG_ APP_w351_csiDevice0Down : 30|1@1+ (1,0) [0|0] "" Vector__XXX
 SG_ APP_w350_tradfcSensorMisaligned : 29|1@1+ (1,0) [0|0] "" Vector__XXX
 SG_ APP_w349_cameraPersistentlyFaulted : 28|1@1+ (1,0) [0|0] "" Vector__XXX
 SG_ APP_w348_cameraSwUpdateRequired : 27|1@1+ (1,0) [0|0] "" Vector__XXX
 SG_ APP_w347_vcbattMiaVehBus : 26|1@1+ (1,0) [0|0] "" Vector__XXX
 SG_ APP_w346_gpsSwEvent : 25|1@1+ (1,0) [0|0] "" Vector__XXX
 SG_ APP_w345_tradfcPerfDegraded : 24|1@1+ (1,0) [0|0] "" Vector__XXX
 SG_ APP_w344_tradfcDspAlgoTimeout : 23|1@1+ (1,0) [0|0] "" Vector__XXX
 SG_ APP_w343_tradfcDspSwError : 22|1@1+ (1,0) [0|0] "" Vector__XXX
 SG_ APP_w342_tradfcDspHwError : 21|1@1+ (1,0) [0|0] "" Vector__XXX
 SG_ APP_w341_tradfcCalibError : 20|1@1+ (1,0) [0|0] "" Vector__XXX
 SG_ APP_w340_tradfcCsiError : 19|1@1+ (1,0) [0|0] "" Vector__XXX
 SG_ APP_w339_tradfcRfTempError : 18|1@1+ (1,0) [0|0] "" Vector__XXX
 SG_ APP_w338_tradfcLfTempError : 17|1@1+ (1,0) [0|0] "" Vector__XXX
 SG_ APP_w337_tradfcRfPmicError : 16|1@1+ (1,0) [0|0] "" Vector__XXX
 SG_ APP_w336_tradfcLfPmicError : 15|1@1+ (1,0) [0|0] "" Vector__XXX
 SG_ APP_w335_tradfcRfSensorError : 14|1@1+ (1,0) [0|0] "" Vector__XXX
 SG_ APP_w334_frontCameraOccluded : 13|1@1+ (1,0) [0|0] "" Vector__XXX
 SG_ APP_w333_fsdUnavailableLocation : 12|1@1+ (1,0) [0|0] "" Vector__XXX
 SG_ APP_w332_cameraPositionsSwapped : 11|1@1+ (1,0) [0|0] "" Vector__XXX
 SG_ APP_w331_fsdDegradedUnavailable : 10|1@1+ (1,0) [0|0] "" Vector__XXX
 SG_ APP_w330_cabinCameraFault : 9|1@1+ (1,0) [0|0] "" Vector__XXX
 SG_ APP_w329_evasiveManeuver : 8|1@1+ (1,0) [0|0] "" Vector__XXX
 SG_ APP_w328_autoparkDegraded : 7|1@1+ (1,0) [0|0] "" Vector__XXX
 SG_ APP_w327_vehicleConfigMismatch : 6|1@1+ (1,0) [0|0] "" Vector__XXX
 SG_ APP_w326_kernelPanic : 5|1@1+ (1,0) [0|0] "" Vector__XXX
 SG_ APP_w325_watchdogReset : 4|1@1+ (1,0) [0|0] "" Vector__XXX
 SG_ APP_w324_adspMia : 3|1@1+ (1,0) [0|0] "" Vector__XXX
 SG_ APP_w323_drivableSpaceFCW : 2|1@1+ (1,0) [0|0] "" Vector__XXX
 SG_ APP_w322_autoWiperWash : 1|1@1+ (1,0) [0|0] "" Vector__XXX
 SG_ APP_w321_bmsMia : 0|1@1+ (1,0) [0|0] "" Vector__XXX

BO_ 1160 DAS_steeringControl: 4 Vector__XXX
 SG_ DAS_steeringControlChecksum : 31|8@0+ (1,0) [0|0] "" Vector__XXX
 SG_ DAS_steeringControlCounter : 19|4@0+ (1,0) [0|0] "" Vector__XXX
 SG_ DAS_steeringControlType : 23|3@0+ (1,0) [0|0] "" Vector__XXX
 SG_ DAS_steeringAngleRequest : 6|15@0+ (0.1,-1638.35) [0|0] "" Vector__XXX
 SG_ DAS_steeringHapticRequest : 7|1@0+ (1,0) [0|0] "" Vector__XXX

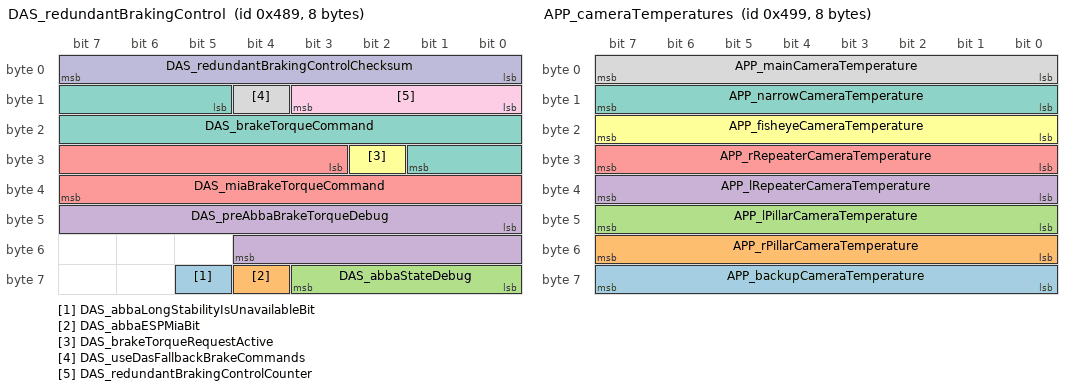
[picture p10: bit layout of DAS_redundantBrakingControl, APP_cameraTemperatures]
BO_ 1161 DAS_redundantBrakingControl: 8 Vector__XXX
 SG_ DAS_abbaLongStabilityIsUnavailableBit : 61|1@1+ (1,0) [0|0] "" Vector__XXX
 SG_ DAS_abbaESPMiaBit : 60|1@1+ (1,0) [0|0] "" Vector__XXX
 SG_ DAS_abbaStateDebug : 56|4@1+ (1,0) [0|0] "" Vector__XXX
 SG_ DAS_preAbbaBrakeTorqueDebug : 40|13@1+ (3,0) [0|0] "" Vector__XXX
 SG_ DAS_miaBrakeTorqueCommand : 27|13@1+ (3,0) [0|0] "" Vector__XXX
 SG_ DAS_brakeTorqueRequestActive : 26|1@1+ (1,0) [0|0] "" Vector__XXX
 SG_ DAS_brakeTorqueCommand : 13|13@1+ (3,0) [0|0] "" Vector__XXX
 SG_ DAS_useDasFallbackBrakeCommands : 12|1@1+ (1,0) [0|0] "" Vector__XXX
 SG_ DAS_redundantBrakingControlCounter : 8|4@1+ (1,0) [0|0] "" Vector__XXX
 SG_ DAS_redundantBrakingControlChecksum : 0|8@1+ (1,0) [0|0] "" Vector__XXX

BO_ 1177 APP_cameraTemperatures: 8 Vector__XXX
 SG_ APP_backupCameraTemperature : 56|8@1+ (1,-60) [0|0] "" Vector__XXX
 SG_ APP_rPillarCameraTemperature : 48|8@1+ (1,-60) [0|0] "" Vector__XXX
 SG_ APP_lPillarCameraTemperature : 40|8@1+ (1,-60) [0|0] "" Vector__XXX
 SG_ APP_lRepeaterCameraTemperature : 32|8@1+ (1,-60) [0|0] "" Vector__XXX
 SG_ APP_rRepeaterCameraTemperature : 24|8@1+ (1,-60) [0|0] "" Vector__XXX
 SG_ APP_fisheyeCameraTemperature : 16|8@1+ (1,-60) [0|0] "" Vector__XXX
 SG_ APP_narrowCameraTemperature : 8|8@1+ (1,-60) [0|0] "" Vector__XXX
 SG_ APP_mainCameraTemperature : 0|8@1+ (1,-60) [0|0] "" Vector__XXX

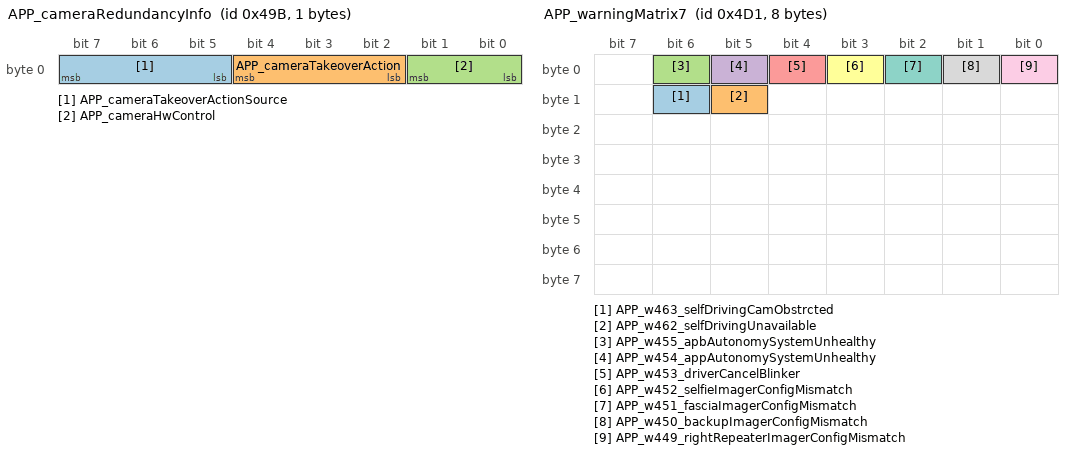
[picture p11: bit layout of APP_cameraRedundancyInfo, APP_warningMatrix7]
BO_ 1179 APP_cameraRedundancyInfo: 1 Vector__XXX
 SG_ APP_cameraTakeoverActionSource : 5|3@1+ (1,0) [0|0] "" Vector__XXX
 SG_ APP_cameraTakeoverAction : 2|3@1+ (1,0) [0|0] "" Vector__XXX
 SG_ APP_cameraHwControl : 0|2@1+ (1,0) [0|0] "" Vector__XXX

BO_ 1233 APP_warningMatrix7: 8 Vector__XXX
 SG_ APP_w463_selfDrivingCamObstrcted : 14|1@1+ (1,0) [0|0] "" Vector__XXX
 SG_ APP_w462_selfDrivingUnavailable : 13|1@1+ (1,0) [0|0] "" Vector__XXX
 SG_ APP_w455_apbAutonomySystemUnhealthy : 6|1@1+ (1,0) [0|0] "" Vector__XXX
 SG_ APP_w454_appAutonomySystemUnhealthy : 5|1@1+ (1,0) [0|0] "" Vector__XXX
 SG_ APP_w453_driverCancelBlinker : 4|1@1+ (1,0) [0|0] "" Vector__XXX
 SG_ APP_w452_selfieImagerConfigMismatch : 3|1@1+ (1,0) [0|0] "" Vector__XXX
 SG_ APP_w451_fasciaImagerConfigMismatch : 2|1@1+ (1,0) [0|0] "" Vector__XXX
 SG_ APP_w450_backupImagerConfigMismatch : 1|1@1+ (1,0) [0|0] "" Vector__XXX
 SG_ APP_w449_rightRepeaterImagerConfigMismatch : 0|1@1+ (1,0) [0|0] "" Vector__XXX

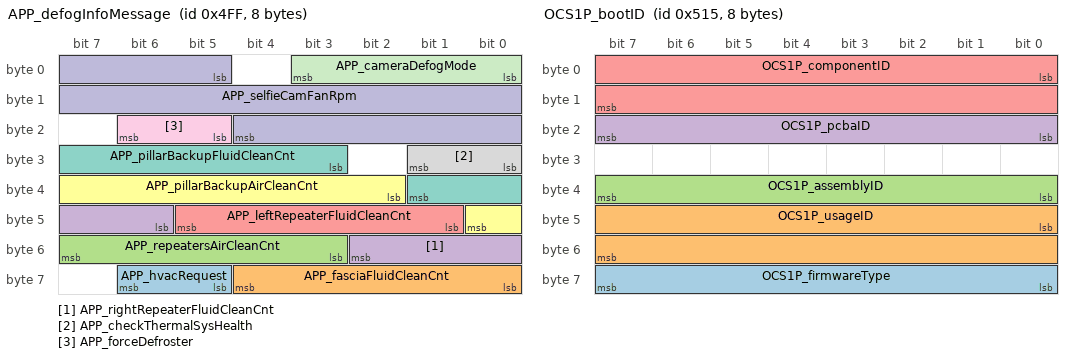
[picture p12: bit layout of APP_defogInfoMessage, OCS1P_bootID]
BO_ 1279 APP_defogInfoMessage: 8 Vector__XXX
 SG_ APP_hvacRequest : 61|2@1+ (1,0) [0|0] "" Vector__XXX
 SG_ APP_fasciaFluidCleanCnt : 56|5@1+ (1,0) [0|0] "" Vector__XXX
 SG_ APP_repeatersAirCleanCnt : 51|5@1+ (1,0) [0|0] "" Vector__XXX
 SG_ APP_rightRepeaterFluidCleanCnt : 46|5@1+ (1,0) [0|0] "" Vector__XXX
 SG_ APP_leftRepeaterFluidCleanCnt : 41|5@1+ (1,0) [0|0] "" Vector__XXX
 SG_ APP_pillarBackupAirCleanCnt : 34|7@1+ (1,0) [0|0] "" Vector__XXX
 SG_ APP_pillarBackupFluidCleanCnt : 27|7@1+ (1,0) [0|0] "" Vector__XXX
 SG_ APP_checkThermalSysHealth : 24|2@1+ (1,0) [0|0] "" Vector__XXX
 SG_ APP_forceDefroster : 21|2@1+ (1,0) [0|0] "" Vector__XXX
 SG_ APP_selfieCamFanRpm : 5|16@1+ (1,0) [0|0] "" Vector__XXX
 SG_ APP_cameraDefogMode : 0|4@1+ (1,0) [0|0] "" Vector__XXX

BO_ 1285 ESP_alertLog: 8 Vector__XXX
 SG_ ESP_alertState : 15|1@1+ (1,0) [0|0] "" Vector__XXX
 SG_ ESP_alertID : 0|9@1+ (1,0) [0|0] "" Vector__XXX

BO_ 1301 OCS1P_bootID: 8 Vector__XXX
 SG_ OCS1P_firmwareType : 56|8@1+ (1,0) [0|0] "" Vector__XXX
 SG_ OCS1P_usageID : 40|16@1+ (1,0) [0|0] "" Vector__XXX
 SG_ OCS1P_assemblyID : 32|8@1+ (1,0) [0|0] "" Vector__XXX
 SG_ OCS1P_pcbaID : 16|8@1+ (1,0) [0|0] "" Vector__XXX
 SG_ OCS1P_componentID : 0|16@1+ (1,0) [0|0] "" Vector__XXX

BO_ 1327 GTW_epochTimeGtw: 8 Vector__XXX
 SG_ GTW_epoch_ns : 7|64@0+ (1,0) [0|0] "" Vector__XXX

BO_ 1353 APP_info: 8 Vector__XXX
 SG_ APP_bootCount m3 : 8|32@1+ (1,0) [0|0] "" Vector__XXX
 SG_ APP_buildType m0 : 8|8@1+ (1,0) [0|0] "" Vector__XXX
 SG_ APP_infoAppApGitHashBytes m2 : 8|56@1+ (1,0) [0|0] "" Vector__XXX
 SG_ APP_infoAppFwGitHashBytes m1 : 8|56@1+ (1,0) [0|0] "" Vector__XXX
 SG_ APP_infoIndex M : 0|8@1+ (1,0) [0|0] "" Vector__XXX

BO_ 1361 EPAS3S_bootID: 8 Vector__XXX
 SG_ EPAS3S_bootIdData : 0|64@1+ (1,0) [0|0] "" Vector__XXX

BO_ 1368 GTW_gitHash: 8 Vector__XXX
 SG_ GTW_appGitHash : 7|64@0+ (1,0) [0|0] "" Vector__XXX

BO_ 1383 ADSP_state: 8 Vector__XXX
 SG_ ADSP_microphoneDataState : 60|1@1+ (1,0) [0|0] "" Vector__XXX
 SG_ ADSP_requestFailoverSpeaker : 59|1@1+ (1,0) [0|0] "" Vector__XXX
 SG_ ADSP_a2baLoadShedded : 58|1@1+ (1,0) [0|0] "" Vector__XXX
 SG_ ADSP_eCallSpeakerStatus : 56|2@1+ (1,0) [0|0] "" Vector__XXX
 SG_ ADSP_eCallMicrophoneStatus : 53|2@1+ (1,0) [0|0] "" Vector__XXX
 SG_ ADSP_telephonyTxMute : 52|1@1+ (1,0) [0|0] "" Vector__XXX
 SG_ ADSP_callState : 51|1@1+ (1,0) [0|0] "" Vector__XXX
 SG_ ADSP_allAudioReady : 50|1@1+ (1,0) [0|0] "" Vector__XXX
 SG_ ADSP_eCallState : 49|1@1+ (1,0) [0|0] "" Vector__XXX
 SG_ ADSP_eCallSelfTest : 47|2@1+ (1,0) [0|0] "" Vector__XXX
 SG_ ADSP_eCall_ENS_state : 44|3@1+ (1,0) [0|0] "" Vector__XXX
 SG_ ADSP_spkMuteAll : 43|1@1+ (1,0) [0|0] "" Vector__XXX
 SG_ ADSP_ancMode : 38|5@1+ (1,0) [0|0] "" Vector__XXX
 SG_ ADSP_tunerSelect : 37|1@1+ (1,0) [0|0] "" Vector__XXX
 SG_ ADSP_sourceSelect : 35|2@1+ (1,0) [0|0] "" Vector__XXX
 SG_ ADSP_ancState : 32|3@1+ (1,0) [0|0] "" Vector__XXX
 SG_ ADSP_telephonyRxMute : 31|1@1+ (1,0) [0|0] "" Vector__XXX
 SG_ ADSP_tcuI2SEnabled : 28|1@1+ (1,0) [0|0] "" Vector__XXX
 SG_ ADSP_audioReady : 27|1@1+ (1,0) [0|0] "" Vector__XXX
 SG_ ADSP_baseamp3State : 24|3@1+ (1,0) [0|0] "" Vector__XXX
 SG_ ADSP_baseamp2State : 19|3@1+ (1,0) [0|0] "" Vector__XXX
 SG_ ADSP_baseamp1State : 16|3@1+ (1,0) [0|0] "" Vector__XXX
 SG_ ADSP_baseamp0State : 13|3@1+ (1,0) [0|0] "" Vector__XXX
 SG_ ADSP_a2bbState : 8|5@1+ (1,0) [0|0] "" Vector__XXX
 SG_ ADSP_a2baState : 0|5@1+ (1,0) [0|0] "" Vector__XXX

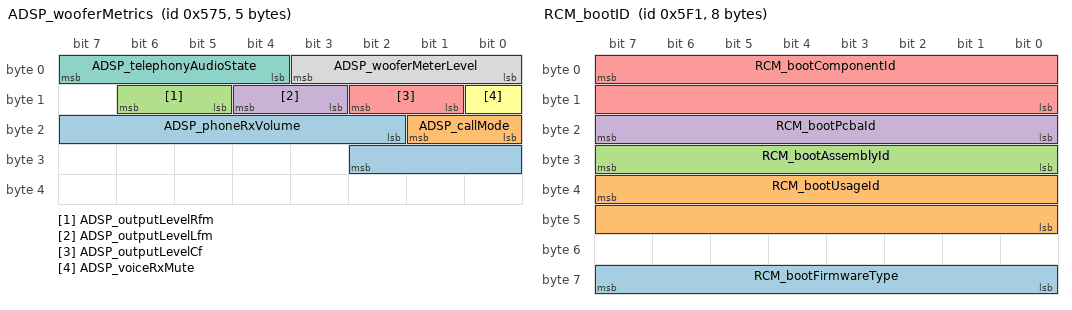
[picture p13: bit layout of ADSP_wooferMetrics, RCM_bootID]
BO_ 1397 ADSP_wooferMetrics: 5 Vector__XXX
 SG_ ADSP_phoneRxVolume : 18|9@1- (1,0) [0|0] "" Vector__XXX
 SG_ ADSP_callMode : 16|2@1+ (1,0) [0|0] "" Vector__XXX
 SG_ ADSP_outputLevelRfm : 13|2@1+ (1,0) [0|0] "" Vector__XXX
 SG_ ADSP_outputLevelLfm : 11|2@1+ (1,0) [0|0] "" Vector__XXX
 SG_ ADSP_outputLevelCf : 9|2@1+ (1,0) [0|0] "" Vector__XXX
 SG_ ADSP_voiceRxMute : 8|1@1+ (1,0) [0|0] "" Vector__XXX
 SG_ ADSP_telephonyAudioState : 4|4@1+ (1,0) [0|0] "" Vector__XXX
 SG_ ADSP_wooferMeterLevel : 0|4@1+ (10,-100) [0|0] "" Vector__XXX

BO_ 1429 OCS1P_alertLog: 8 Vector__XXX
 SG_ OCS1P_a145_humidity m145 : 56|8@1+ (1,0) [0|0] "" Vector__XXX
 SG_ OCS1P_a000_alertDataW2 m0 : 48|16@1+ (1,0) [0|0] "" Vector__XXX
 SG_ OCS1P_a145_temperature m145 : 48|8@1+ (1,-40) [0|0] "" Vector__XXX
 SG_ OCS1P_a148_filtRBClass m148 : 43|3@1+ (1,0) [0|0] "" Vector__XXX
 SG_ OCS1P_a148_filtCapClass m148 : 40|3@1+ (1,0) [0|0] "" Vector__XXX
 SG_ OCS1P_a151_seatbackSelfMin m151 : 40|16@1+ (0.005,0) [0|0] "" Vector__XXX
 SG_ OCS1P_a154_seatbackSelfMin m154 : 40|16@1+ (0.005,0) [0|0] "" Vector__XXX
 SG_ OCS1P_a148_filtFreqClass m148 : 35|3@1+ (1,0) [0|0] "" Vector__XXX
 SG_ OCS1P_a000_alertDataW1 m0 : 32|16@1+ (1,0) [0|0] "" Vector__XXX
 SG_ OCS1P_a145_seatbackSelfOffset m145 : 32|16@1- (0.0025,0) [0|0] "" Vector__XXX
 SG_ OCS1P_a148_rawRBClass m148 : 32|3@1+ (1,0) [0|0] "" Vector__XXX
 SG_ OCS1P_a150_seatbackSelfBaseline m150 : 32|16@1+ (0.005,0) [0|0] "" Vector__XXX
 SG_ OCS1P_a152_seatbackSelfPreExit m152 : 32|16@1+ (0.005,0) [0|0] "" Vector__XXX
 SG_ OCS1P_a155_seatbackSelfBaseline m155 : 32|16@1+ (0.005,0) [0|0] "" Vector__XXX
 SG_ OCS1P_a148_rawCapClass m148 : 27|3@1+ (1,0) [0|0] "" Vector__XXX
 SG_ OCS1P_a148_rawFreqClass m148 : 24|3@1+ (1,0) [0|0] "" Vector__XXX
 SG_ OCS1P_a151_cushionSelfMin m151 : 24|16@1+ (0.005,0) [0|0] "" Vector__XXX
 SG_ OCS1P_a154_cushionSelfMin m154 : 24|16@1+ (0.005,0) [0|0] "" Vector__XXX
 SG_ OCS1P_a015_NVMMWriteFailed m15 : 21|1@1+ (1,0) [0|0] "" Vector__XXX
 SG_ OCS1P_a148_filtRBVsCap m148 : 21|1@1+ (1,0) [0|0] "" Vector__XXX
 SG_ OCS1P_a015_NVMMMemOverflow m15 : 20|1@1+ (1,0) [0|0] "" Vector__XXX
 SG_ OCS1P_a148_filtRBVsFreq m148 : 20|1@1+ (1,0) [0|0] "" Vector__XXX
 SG_ OCS1P_a015_NVMMRecordUpgraded m15 : 19|1@1+ (1,0) [0|0] "" Vector__XXX
 SG_ OCS1P_a148_filtCapVsFreq m148 : 19|1@1+ (1,0) [0|0] "" Vector__XXX
 SG_ OCS1P_a015_NVMMVersionMismatch m15 : 18|1@1+ (1,0) [0|0] "" Vector__XXX
 SG_ OCS1P_a148_rawRBVsCap m148 : 18|1@1+ (1,0) [0|0] "" Vector__XXX
 SG_ OCS1P_a015_NVMMCRCMismatch m15 : 17|1@1+ (1,0) [0|0] "" Vector__XXX
 SG_ OCS1P_a148_rawRBVsFreq m148 : 17|1@1+ (1,0) [0|0] "" Vector__XXX
 SG_ OCS1P_a000_alertDataW0 m0 : 16|16@1+ (1,0) [0|0] "" Vector__XXX
 SG_ OCS1P_a015_NVMMRecordNotFound m15 : 16|1@1+ (1,0) [0|0] "" Vector__XXX
 SG_ OCS1P_a121_sandwichFreq m121 : 16|32@1+ (1,0) [0|0] "" Vector__XXX
 SG_ OCS1P_a122_sandwichFreq m122 : 16|32@1+ (1,0) [0|0] "" Vector__XXX
 SG_ OCS1P_a123_sandwichFreq m123 : 16|32@1+ (1,0) [0|0] "" Vector__XXX
 SG_ OCS1P_a124_cushionSelfFreq m124 : 16|32@1+ (1,0) [0|0] "" Vector__XXX
 SG_ OCS1P_a125_cushionSelfFreq m125 : 16|32@1+ (1,0) [0|0] "" Vector__XXX
 SG_ OCS1P_a126_cushionSelfFreq m126 : 16|32@1+ (1,0) [0|0] "" Vector__XXX
 SG_ OCS1P_a127_seatbackSelfFreq m127 : 16|32@1+ (1,0) [0|0] "" Vector__XXX
 SG_ OCS1P_a128_seatbackSelfFreq m128 : 16|32@1+ (1,0) [0|0] "" Vector__XXX
 SG_ OCS1P_a129_seatbackSelfFreq m129 : 16|32@1+ (1,0) [0|0] "" Vector__XXX
 SG_ OCS1P_a130_sandwichNoCalib m130 : 16|1@1+ (1,0) [0|0] "" Vector__XXX
 SG_ OCS1P_a131_cushionSelfNoCalib m131 : 16|1@1+ (1,0) [0|0] "" Vector__XXX
 SG_ OCS1P_a132_seatbackSelfNoCalib m132 : 16|1@1+ (1,0) [0|0] "" Vector__XXX
 SG_ OCS1P_a133_sandwichBadCalib m133 : 16|1@1+ (1,0) [0|0] "" Vector__XXX
 SG_ OCS1P_a134_uninitializedCalib m134 : 16|1@1+ (1,0) [0|0] "" Vector__XXX
 SG_ OCS1P_a135_tempNoCalib m135 : 16|1@1+ (1,0) [0|0] "" Vector__XXX
 SG_ OCS1P_a136_cushionSelfDuty m136 : 16|32@1+ (1,0) [0|0] "" Vector__XXX
 SG_ OCS1P_a137_cushionSelfDuty m137 : 16|32@1+ (1,0) [0|0] "" Vector__XXX
 SG_ OCS1P_a138_seatbackSelfDuty m138 : 16|32@1+ (1,0) [0|0] "" Vector__XXX
 SG_ OCS1P_a139_seatbackSelfDuty m139 : 16|32@1+ (1,0) [0|0] "" Vector__XXX
 SG_ OCS1P_a140_tempInvalidCalib m140 : 16|1@1+ (1,0) [0|0] "" Vector__XXX
 SG_ OCS1P_a141_humidityInvalidCalib m141 : 16|1@1+ (1,0) [0|0] "" Vector__XXX
 SG_ OCS1P_a142_tempHumidityInvalid m142 : 16|1@1+ (1,0) [0|0] "" Vector__XXX
 SG_ OCS1P_a143_mismatchPassAirbag m143 : 16|1@1+ (1,0) [0|0] "" Vector__XXX
 SG_ OCS1P_a144_mismatchCarRegion m144 : 16|1@1+ (1,0) [0|0] "" Vector__XXX
 SG_ OCS1P_a145_cushionSelfOffset m145 : 16|16@1- (0.005,0) [0|0] "" Vector__XXX
 SG_ OCS1P_a148_rawCapVsFreq m148 : 16|1@1+ (1,0) [0|0] "" Vector__XXX
 SG_ OCS1P_a150_cushionSelfBaseline m150 : 16|16@1+ (0.005,0) [0|0] "" Vector__XXX
 SG_ OCS1P_a151_reason m151 : 16|3@1+ (1,0) [0|0] "" Vector__XXX
 SG_ OCS1P_a152_cushionSelfPreExit m152 : 16|16@1+ (0.005,0) [0|0] "" Vector__XXX
 SG_ OCS1P_a153_reason m153 : 16|3@1+ (1,0) [0|0] "" Vector__XXX
 SG_ OCS1P_a154_reason m154 : 16|3@1+ (1,0) [0|0] "" Vector__XXX
 SG_ OCS1P_a155_cushionSelfBaseline m155 : 16|16@1+ (0.005,0) [0|0] "" Vector__XXX
 SG_ OCS1P_alertState : 15|1@1+ (1,0) [0|0] "" Vector__XXX
 SG_ OCS1P_alertID M : 0|8@1+ (1,0) [0|0] "" Vector__XXX

BO_ 1469 IBST_alertLog: 8 Vector__XXX
 SG_ IBST_alertState : 15|1@1+ (1,0) [0|0] "" Vector__XXX
 SG_ IBST_alertID : 0|8@1+ (1,0) [0|0] "" Vector__XXX

BO_ 1497 DAS_carLog: 8 Vector__XXX
 SG_ DAS_pmmNotActivatingReason m2 : 53|5@1+ (1,0) [0|0] "" Vector__XXX
 SG_ DAS_closestInLaneTargetVxRel m4 : 52|10@1+ (0.1,-51.1) [0|0] "" Vector__XXX
 SG_ DAS_radarTarget4_dx m3 : 48|12@1+ (0.0625,0) [0|0] "" Vector__XXX
 SG_ DAS_accUnavailableReason m2 : 46|7@1+ (1,0) [0|0] "" Vector__XXX
 SG_ DAS_closestRightLaneTargetDx m4 : 40|12@1+ (0.0625,0) [0|0] "" Vector__XXX
 SG_ DAS_driveOnNavUnavailableReason m2 : 40|5@1+ (1,0) [0|0] "" Vector__XXX
 SG_ DAS_handsOnDetected m2 : 38|2@1+ (1,0) [0|0] "" Vector__XXX
 SG_ DAS_radarTarget1_VxRel m1 : 36|8@1+ (0.2,-25.6) [0|0] "" Vector__XXX
 SG_ DAS_radarTarget3_dx m3 : 36|12@1+ (0.0625,0) [0|0] "" Vector__XXX
 SG_ DAS_aeb_not_activating_reason m2 : 32|5@1+ (1,0) [0|0] "" Vector__XXX
 SG_ DAS_ACC_camStatus m2 : 30|2@1+ (1,0) [0|0] "" Vector__XXX
 SG_ DAS_closestLeftLaneTargetDx m4 : 28|12@1+ (0.0625,0) [0|0] "" Vector__XXX
 SG_ DAS_LC_handsOnReason m2 : 24|6@1+ (1,0) [0|0] "" Vector__XXX
 SG_ DAS_radarTarget1_dx m1 : 24|12@1+ (0.0625,0) [0|0] "" Vector__XXX
 SG_ DAS_radarTarget2_dx m3 : 24|12@1+ (0.0625,0) [0|0] "" Vector__XXX
 SG_ DAS_associated_rad_object m2 : 22|2@1+ (1,0) [0|0] "" Vector__XXX
 SG_ DAS_restrictionLowSpeedTraffic m2 : 21|1@1+ (1,0) [0|0] "" Vector__XXX
 SG_ DAS_constructionArea m2 : 19|2@1+ (1,0) [0|0] "" Vector__XXX
 SG_ DAS_desiredTarget_dx m3 : 16|8@1+ (0.5,0) [0|0] "" Vector__XXX
 SG_ DAS_fcmThreatAssesmentMode m2 : 16|3@1+ (1,0) [0|0] "" Vector__XXX
 SG_ DAS_secondInLaneTargetDx m4 : 16|12@1+ (0.0625,0) [0|0] "" Vector__XXX
 SG_ DAS_alcBehaviorState m0 : 15|3@1+ (1,0) [0|0] "" Vector__XXX
 SG_ DAS_alcBehaviorAbortReason m0 : 11|4@1+ (1,0) [0|0] "" Vector__XXX
 SG_ DAS_fcmCollisionStage3Checks m2 : 8|8@1+ (1,0) [0|0] "" Vector__XXX
 SG_ DAS_fcmSteeringOverride m2 : 7|1@1+ (1,0) [0|0] "" Vector__XXX
 SG_ DAS_mobileyeIPSOapproved m2 : 6|1@1+ (1,0) [0|0] "" Vector__XXX
 SG_ DAS_mobileyePedAebFlag m2 : 5|1@1+ (1,0) [0|0] "" Vector__XXX
 SG_ DAS_autosteerUnavailableReason m0 : 4|7@1+ (1,0) [0|0] "" Vector__XXX
 SG_ DAS_closestInLaneTargetDx m4 : 4|12@1+ (0.0625,0) [0|0] "" Vector__XXX
 SG_ DAS_mobileyeVehAebFlag m2 : 4|1@1+ (1,0) [0|0] "" Vector__XXX
 SG_ DAS_radarTarget5_dx m1 : 4|12@1+ (0.0625,0) [0|0] "" Vector__XXX
 SG_ DAS_carLogMultiplexer M : 0|4@1+ (1,0) [0|0] "" Vector__XXX

BO_ 1521 RCM_bootID: 8 Vector__XXX
 SG_ RCM_bootFirmwareType : 63|8@0+ (1,0) [0|0] "" Vector__XXX
 SG_ RCM_bootUsageId : 39|16@0+ (1,0) [0|0] "" Vector__XXX
 SG_ RCM_bootAssemblyId : 31|8@0+ (1,0) [0|0] "" Vector__XXX
 SG_ RCM_bootPcbaId : 23|8@0+ (1,0) [0|0] "" Vector__XXX
 SG_ RCM_bootComponentId : 7|16@0+ (1,0) [0|0] "" Vector__XXX

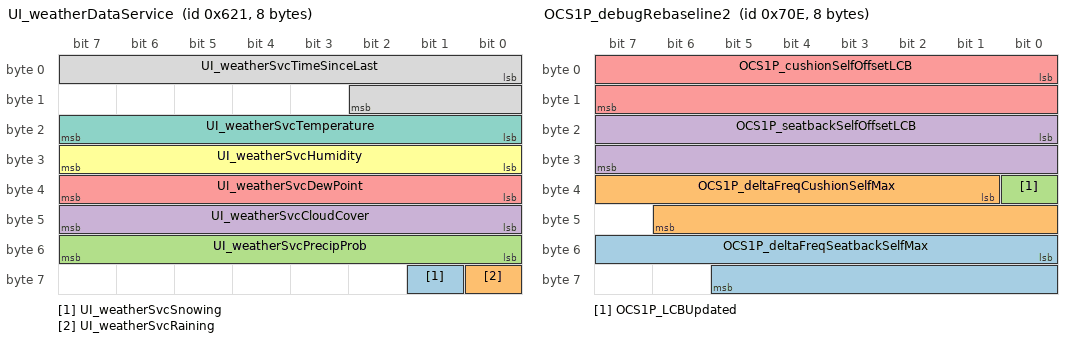
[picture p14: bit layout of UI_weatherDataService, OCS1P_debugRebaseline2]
BO_ 1569 UI_weatherDataService: 8 Vector__XXX
 SG_ UI_weatherSvcSnowing : 57|1@1+ (1,0) [0|0] "" Vector__XXX
 SG_ UI_weatherSvcRaining : 56|1@1+ (1,0) [0|0] "" Vector__XXX
 SG_ UI_weatherSvcPrecipProb : 48|8@1+ (0.5,0) [0|0] "" Vector__XXX
 SG_ UI_weatherSvcCloudCover : 40|8@1+ (0.5,0) [0|0] "" Vector__XXX
 SG_ UI_weatherSvcDewPoint : 32|8@1+ (0.5,0) [0|0] "" Vector__XXX
 SG_ UI_weatherSvcHumidity : 24|8@1+ (0.5,0) [0|0] "" Vector__XXX
 SG_ UI_weatherSvcTemperature : 16|8@1- (0.5,0) [0|0] "" Vector__XXX
 SG_ UI_weatherSvcTimeSinceLast : 0|11@1+ (1,0) [0|0] "" Vector__XXX

BO_ 1592 EPAS3P_udsResponseCH: 8 Vector__XXX
 SG_ EPAS3P_udsResponseDataCH : 7|64@0+ (1,0) [0|0] "" Vector__XXX

BO_ 1601 UDS_rcmRequest: 8 Vector__XXX
 SG_ UDS_rcmRequestData : 7|64@0+ (1,0) [0|0] "" Vector__XXX

BO_ 1617 RCM_udsResponse: 8 Vector__XXX
 SG_ RCM_udsResponseData : 7|64@0+ (1,0) [0|0] "" Vector__XXX

BO_ 1806 OCS1P_debugRebaseline2: 8 Vector__XXX
 SG_ OCS1P_deltaFreqSeatbackSelfMax : 48|14@1- (10,0) [0|0] "" Vector__XXX
 SG_ OCS1P_deltaFreqCushionSelfMax : 33|14@1- (10,0) [0|0] "" Vector__XXX
 SG_ OCS1P_LCBUpdated : 32|1@1+ (1,0) [0|0] "" Vector__XXX
 SG_ OCS1P_seatbackSelfOffsetLCB : 16|16@1- (0.005,0) [0|0] "" Vector__XXX
 SG_ OCS1P_cushionSelfOffsetLCB : 0|16@1- (0.005,0) [0|0] "" Vector__XXX

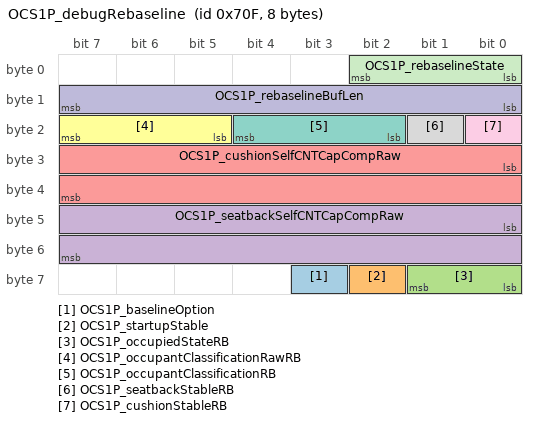
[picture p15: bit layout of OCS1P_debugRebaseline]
BO_ 1807 OCS1P_debugRebaseline: 8 Vector__XXX
 SG_ OCS1P_baselineOption : 59|1@1+ (1,0) [0|0] "" Vector__XXX
 SG_ OCS1P_startupStable : 58|1@1+ (1,0) [0|0] "" Vector__XXX
 SG_ OCS1P_occupiedStateRB : 56|2@1+ (1,0) [0|0] "" Vector__XXX
 SG_ OCS1P_seatbackSelfCNTCapCompRaw : 40|16@1+ (0.005,0) [0|0] "" Vector__XXX
 SG_ OCS1P_cushionSelfCNTCapCompRaw : 24|16@1+ (0.005,0) [0|0] "" Vector__XXX
 SG_ OCS1P_occupantClassificationRawRB : 21|3@1+ (1,0) [0|0] "" Vector__XXX
 SG_ OCS1P_occupantClassificationRB : 18|3@1+ (1,0) [0|0] "" Vector__XXX
 SG_ OCS1P_seatbackStableRB : 17|1@1+ (1,0) [0|0] "" Vector__XXX
 SG_ OCS1P_cushionStableRB : 16|1@1+ (1,0) [0|0] "" Vector__XXX
 SG_ OCS1P_rebaselineBufLen : 8|8@1+ (1,0) [0|0] "" Vector__XXX
 SG_ OCS1P_rebaselineState : 0|3@1+ (1,0) [0|0] "" Vector__XXX

BO_ 1815 RCM_imuOffsets: 7 Vector__XXX
 SG_ RCM_CGZdistance m2 : 40|16@1+ (1,-32768) [0|0] "" Vector__XXX
 SG_ RCM_rollRateOffset m0 : 40|16@1- (0.0001,0) [0|0] "" Vector__XXX
 SG_ RCM_verticalAccelOffset m1 : 40|16@1- (0.00125,0) [0|0] "" Vector__XXX
 SG_ RCM_CGYdistance m2 : 24|16@1+ (1,-32768) [0|0] "" Vector__XXX
 SG_ RCM_lateralAccelOffset m1 : 24|16@1- (0.00125,0) [0|0] "" Vector__XXX
 SG_ RCM_pitchRateOffset m0 : 24|16@1- (0.0001,0) [0|0] "" Vector__XXX
 SG_ RCM_CGXdistance m2 : 8|16@1+ (1,-32768) [0|0] "" Vector__XXX
 SG_ RCM_longitudinalAccelOffset m1 : 8|16@1- (0.00125,0) [0|0] "" Vector__XXX
 SG_ RCM_yawRateOffset m0 : 8|16@1- (0.0001,0) [0|0] "" Vector__XXX
 SG_ RCM_imuOffsetsIndex M : 0|2@1+ (1,0) [0|0] "" Vector__XXX

CM_ BO_ 873 "ESP32-DualCAN Model3_CH. Seen on this car: 8-byte frames; fit weak (bits covered 0%, mux 100%, ranges 100%).";
CM_ BO_ 876 "ESP32-DualCAN Model3_CH. Seen on this car: 8-byte frames; fit weak (bits covered 0%, mux 100%, ranges 100%).";
CM_ BO_ 880 "ESP32-DualCAN Model3_CH. Seen on this car: 8-byte frames; fit ok (bits covered 100%, mux 100%, ranges 100%).";
CM_ BO_ 899 "ESP32-DualCAN Model3_CH. Seen on this car: 8-byte frames; fit ok (bits covered 100%, mux 100%, ranges 100%, checksum 0%).";
CM_ BO_ 905 "DashKit DBC. Seen on this car: 8-byte frames; fit good (bits covered 100%, mux 100%, ranges 100%, checksum 100%). read by the app or firmware; DashKit names kept.";
CM_ BO_ 907 "ESP32-DualCAN Model3_CH. Seen on this car: 5-byte frames; fit ok (bits covered 100%, mux 100%, ranges 100%).";
CM_ BO_ 917 "ESP32-DualCAN Model3_CH. Seen on this car: 8-byte frames; fit ok (bits covered 100%, mux 65%, ranges 100%).";
CM_ BO_ 921 "ESP32-DualCAN Model3_CH. Seen on this car: 8-byte frames; fit good (bits covered 100%, mux 100%, ranges 100%, checksum 100%). read by the app or firmware.";
CM_ BO_ 925 "ESP32-DualCAN Model3_CH. Seen on this car: 5-byte frames; fit ok (bits covered 100%, mux 100%, ranges 100%, checksum 100%).";
CM_ BO_ 939 "ESP32-DualCAN Model3_CH. Seen on this car: 5-byte frames; fit poor (bits covered 0%, mux 100%, ranges 100%).";
CM_ BO_ 943 "ESP32-DualCAN Model3_CH. Seen on this car: 8-byte frames; fit good (bits covered 100%, mux 100%, ranges 100%).";
CM_ BO_ 947 "ESP32-DualCAN Model3_CH. Seen on this car: 8-byte frames; fit good (bits covered 100%, mux 100%, ranges 100%). read by the app or firmware.";
CM_ BO_ 952 "ESP32-DualCAN Model3_CH. Seen on this car: 4-byte frames; fit poor (bits covered 0%, mux 100%, ranges 100%).";
CM_ BO_ 962 "ESP32-DualCAN Model3_CH. Seen on this car: 8-byte frames; fit good (bits covered 100%, mux 100%, ranges 100%). read by the app or firmware.";
CM_ BO_ 963 "ESP32-DualCAN Model3_CH. Seen on this car: 8-byte frames; fit good (bits covered 100%, mux 100%, ranges 100%).";
CM_ BO_ 969 "ESP32-DualCAN Model3_CH. Seen on this car: 8-byte frames; fit good (bits covered 100%, mux 100%, ranges 100%).";
CM_ BO_ 970 "ESP32-DualCAN Model3_CH. Seen on this car: 8-byte frames; fit good (bits covered 100%, mux 100%, ranges 100%).";
CM_ BO_ 971 "ESP32-DualCAN Model3_CH. Seen on this car: 5-byte frames; fit ok (bits covered 100%, mux 100%, ranges 100%).";
CM_ BO_ 977 "ESP32-DualCAN Model3_CH. Seen on this car: 8-byte frames; fit good (bits covered 100%, mux 100%, ranges 100%).";
CM_ BO_ 985 "ESP32-DualCAN Model3_CH. Seen on this car: 8-byte frames; fit good (bits covered 100%, mux 100%, ranges 100%).";
CM_ BO_ 988 "ESP32-DualCAN Model3_CH. Seen on this car: 8-byte frames; fit weak (bits covered 0%, mux 100%, ranges 100%).";
CM_ BO_ 991 "ESP32-DualCAN Model3_CH. Seen on this car: 8-byte frames; fit good (bits covered 100%, mux 100%, ranges 100%). read by the app or firmware.";
CM_ BO_ 1011 "ESP32-DualCAN Model3_CH. Seen on this car: 3-byte frames; fit ok (bits covered 100%, mux 100%, ranges 100%).";
CM_ BO_ 1012 "ESP32-DualCAN Model3_CH. Seen on this car: 6-byte frames; fit ok (bits covered 100%, mux 100%, ranges 100%).";
CM_ BO_ 1013 "ESP32-DualCAN Model3_CH. Seen on this car: 8-byte frames; fit good (bits covered 100%, mux 100%, ranges 100%).";
CM_ BO_ 1016 "ESP32-DualCAN Model3_CH. Seen on this car: 8-byte frames; fit good (bits covered 100%, mux 100%, ranges 100%).";
CM_ BO_ 1018 "ESP32-DualCAN Model3_CH. Seen on this car: 8-byte frames; fit good (bits covered 100%, mux 100%, ranges 100%).";
CM_ BO_ 1020 "ESP32-DualCAN Model3_CH. Seen on this car: 7-byte frames; fit ok (bits covered 100%, mux 100%, ranges 100%).";
CM_ BO_ 1022 "ESP32-DualCAN Model3_CH. Seen on this car: 8-byte frames; fit good (bits covered 100%, mux 100%, ranges 100%, checksum 100%).";
CM_ BO_ 1023 "ESP32-DualCAN Model3_CH. Seen on this car: 8-byte frames; fit ok (bits covered 56%, mux 100%, ranges 100%).";
CM_ BO_ 1029 "ESP32-DualCAN Model3_CH. Seen on this car: 8-byte frames; fit ok (bits covered 100%, mux 100%, ranges 100%).";
CM_ BO_ 1033 "ESP32-DualCAN Model3_CH. Seen on this car: 1-byte frames; fit ok (bits covered 100%, mux 100%, ranges 100%).";
CM_ BO_ 1040 "ESP32-DualCAN Model3_CH. Seen on this car: 3-byte frames; fit ok (bits covered 100%, mux 100%, ranges 100%).";
CM_ BO_ 1043 "ESP32-DualCAN Model3_CH. Seen on this car: 3-byte frames; fit ok (bits covered 100%, mux 100%, ranges 100%).";
CM_ BO_ 1045 "ESP32-DualCAN Model3_CH. Seen on this car: 1-byte frames; fit ok (bits covered 100%, mux 100%, ranges 100%).";
CM_ BO_ 1048 "ESP32-DualCAN Model3_CH. Seen on this car: 2-byte frames; fit ok (bits covered 100%, mux 100%, ranges 100%).";
CM_ BO_ 1049 "ESP32-DualCAN Model3_CH. Seen on this car: 1-byte frames; fit ok (bits covered 100%, mux 100%, ranges 100%).";
CM_ BO_ 1056 "ESP32-DualCAN Model3_CH. Seen on this car: 8-byte frames; fit good (bits covered 100%, mux 100%, ranges 100%).";
CM_ BO_ 1061 "ESP32-DualCAN Model3_CH. Seen on this car: 8-byte frames; fit weak (bits covered 0%, mux 100%, ranges 100%).";
CM_ BO_ 1064 "ESP32-DualCAN Model3_CH. Seen on this car: 8-byte frames; fit weak (bits covered 0%, mux 100%, ranges 100%).";
CM_ BO_ 1065 "ESP32-DualCAN Model3_CH. Seen on this car: 8-byte frames; fit weak (bits covered 0%, mux 100%, ranges 100%).";
CM_ BO_ 1081 "ESP32-DualCAN Model3_CH. Seen on this car: 8-byte frames; fit weak (bits covered 0%, mux 100%, ranges 100%).";
CM_ BO_ 1096 "ESP32-DualCAN Model3_CH. Seen on this car: 8-byte frames; fit weak (bits covered 0%, mux 100%, ranges 100%).";
CM_ BO_ 1097 "ESP32-DualCAN Model3_CH. Seen on this car: 8-byte frames; fit weak (bits covered 0%, mux 100%, ranges 100%).";
CM_ BO_ 1113 "ESP32-DualCAN Model3_CH. Seen on this car: 8-byte frames; fit good (bits covered 100%, mux 100%, ranges 100%).";
CM_ BO_ 1149 "ESP32-DualCAN Model3_CH. Seen on this car: 8-byte frames; fit good (bits covered 100%, mux 100%, ranges 100%).";
CM_ BO_ 1151 "ESP32-DualCAN Model3_CH. Seen on this car: 8-byte frames; fit weak (bits covered 0%, mux 100%, ranges 100%).";
CM_ BO_ 1160 "ESP32-DualCAN Model3_CH. Seen on this car: 4-byte frames; fit ok (bits covered 100%, mux 100%, ranges 100%).";
CM_ BO_ 1161 "ESP32-DualCAN Model3_CH. Seen on this car: 8-byte frames; fit good (bits covered 100%, mux 100%, ranges 100%, checksum 100%).";
CM_ BO_ 1177 "ESP32-DualCAN Model3_CH. Seen on this car: 8-byte frames; fit good (bits covered 100%, mux 100%, ranges 100%).";
CM_ BO_ 1179 "ESP32-DualCAN Model3_CH. Seen on this car: 1-byte frames; fit poor (bits covered 0%, mux 100%, ranges 100%).";
CM_ BO_ 1233 "ESP32-DualCAN Model3_CH. Seen on this car: 8-byte frames; fit weak (bits covered 0%, mux 100%, ranges 100%).";
CM_ BO_ 1279 "ESP32-DualCAN Model3_CH. Seen on this car: 8-byte frames; fit weak (bits covered 0%, mux 100%, ranges 100%).";
CM_ BO_ 1285 "ESP32-DualCAN Model3_CH. Seen on this car: 8-byte frames; fit good (bits covered 100%, mux 100%, ranges 100%).";
CM_ BO_ 1301 "ESP32-DualCAN Model3_CH. Seen on this car: 8-byte frames; fit weak (bits covered 0%, mux 100%, ranges 100%).";
CM_ BO_ 1327 "ESP32-DualCAN Model3_CH. Seen on this car: 8-byte frames; fit ok (bits covered 100%, mux 100%, ranges 100%).";
CM_ BO_ 1353 "ESP32-DualCAN Model3_CH. Seen on this car: 8-byte frames; fit good (bits covered 100%, mux 100%, ranges 100%).";
CM_ BO_ 1361 "ESP32-DualCAN Model3_CH. Seen on this car: 8-byte frames; fit weak (bits covered 0%, mux 100%, ranges 100%).";
CM_ BO_ 1368 "ESP32-DualCAN Model3_CH. Seen on this car: 8-byte frames; fit ok (bits covered 100%, mux 100%, ranges 100%).";
CM_ BO_ 1383 "ESP32-DualCAN Model3_CH. Seen on this car: 8-byte frames; fit good (bits covered 87%, mux 100%, ranges 100%).";
CM_ BO_ 1397 "ESP32-DualCAN Model3_CH. Seen on this car: 5-byte frames; fit ok (bits covered 75%, mux 100%, ranges 100%).";
CM_ BO_ 1429 "ESP32-DualCAN Model3_CH. Seen on this car: 8-byte frames; fit good (bits covered 100%, mux 100%, ranges 100%).";
CM_ BO_ 1469 "ESP32-DualCAN Model3_CH. Seen on this car: 8-byte frames; fit weak (bits covered 0%, mux 100%, ranges 100%).";
CM_ BO_ 1497 "ESP32-DualCAN Model3_CH. Seen on this car: 8-byte frames; fit good (bits covered 100%, mux 100%, ranges 100%).";
CM_ BO_ 1521 "ESP32-DualCAN Model3_CH. Seen on this car: 8-byte frames; fit poor (bits covered 0%, mux 100%, ranges 100%).";
CM_ BO_ 1569 "ESP32-DualCAN Model3_CH. Seen on this car: 8-byte frames; fit ok (bits covered 82%, mux 100%, ranges 100%).";
CM_ BO_ 1592 "ESP32-DualCAN Model3_CH. Seen on this car: 8-byte frames; fit ok (bits covered 100%, mux 100%, ranges 100%).";
CM_ BO_ 1601 "ESP32-DualCAN Model3_CH. Seen on this car: 8-byte frames; fit ok (bits covered 100%, mux 100%, ranges 100%).";
CM_ BO_ 1617 "ESP32-DualCAN Model3_CH. Seen on this car: 8-byte frames; fit ok (bits covered 100%, mux 100%, ranges 100%).";
CM_ BO_ 1806 "ESP32-DualCAN Model3_CH. Seen on this car: 8-byte frames; fit good (bits covered 100%, mux 100%, ranges 100%).";
CM_ BO_ 1807 "ESP32-DualCAN Model3_CH. Seen on this car: 8-byte frames; fit good (bits covered 100%, mux 100%, ranges 100%).";
CM_ BO_ 1815 "ESP32-DualCAN Model3_CH. Seen on this car: 7-byte frames; fit ok (bits covered 100%, mux 100%, ranges 100%).";
BA_DEF_ BO_  "GenMsgCycleTime" INT 0 65535;
BA_DEF_DEF_  "GenMsgCycleTime" 0;
BA_ "GenMsgCycleTime" BO_ 905 500;
VAL_ 880 EPAS3S_eacStatus 0 "INHIBITED" 1 "AVAILABLE" 2 "ACTIVE" 3 "FAULT" 4 "LKA_ELK_AVAILABLE" 5 "LKA_ACTIVE" 6 "ELK_AVAILABLE" 7 "ELK_ACTIVE" ;
VAL_ 880 EPAS3S_handsOnLevel 0 "0" 1 "1" 2 "2" 3 "3" ;
VAL_ 880 EPAS3S_torsionBarTorque 4094 "UNDEFINABLE_DATA" 4095 "SNA" ;
VAL_ 880 EPAS3S_eacErrorCode 0 "EAC_ERROR_IDLE" 1 "EAC_ERROR_MIN_SPEED" 2 "EAC_ERROR_MAX_SPEED" 3 "EAC_ERROR_HANDS_ON" 4 "EAC_ERROR_TMP_FAULT" 5 "EAR_ERROR_MAX_STEER_DELTA" 6 "EAC_ERROR_HIGH_ANGLE_REQ" 7 "EAC_ERROR_HIGH_ANGLE_RATE_REQ" 8 "EAC_ERROR_HIGH_ANGLE_SAFETY" 9 "EAC_ERROR_HIGH_ANGLE_RATE_SAFETY" 10 "EAC_ERROR_HIGH_MMOT_SAFETY" 11 "EAC_ERROR_HIGH_TORSION_SAFETY" 12 "EAC_ERROR_LOW_ASSIST" 13 "EAC_ERROR_PINION_VEL_DIFF" 14 "EAC_EXTERNAL_MONITOR_INHIBIT" 15 "SNA" ;
VAL_ 880 EPAS3S_steeringRackForce 1022 "NOT_IN_SPEC" 1023 "SNA" ;
VAL_ 880 EPAS3S_steeringFault 0 "NO_FAULT" 1 "FAULT" ;
VAL_ 880 EPAS3S_steeringReduced 0 "NORMAL_ASSIST" 1 "REDUCED_ASSIST" ;
VAL_ 880 EPAS3S_internalSASQF 0 "UNDEFINABLE_ACCURACY" 1 "IN_SPEC" ;
VAL_ 880 EPAS3S_currentTuneMode 0 "DM_COMFORT" 1 "DM_STANDARD" 2 "DM_SPORT" 3 "RWD_COMFORT" 4 "RWD_STANDARD" 5 "RWD_SPORT" ;
VAL_ 899 VCRIGHT_occupantClassificationQF 0 "FAULTED" 1 "NOT_FAULTED" ;
VAL_ 899 VCRIGHT_occupantClassification 0 "EMPTY" 1 "INHIBIT" 2 "SMALL" 3 "LARGE" 4 "INIT" 5 "NOT_CONFIGURED" 7 "SNA" ;
VAL_ 899 VCRIGHT_seatTrackPosition 0 "FORWARD" 1 "REARWARD" 2 "NOT_CONFIGURED" 3 "FAULTED" 7 "SNA" ;
VAL_ 899 VCRIGHT_3RowRightOccupancyStatus 0 "UNOCCUPIED" 1 "OCCUPIED" 2 "OCCUPANCY_FAULTED" 3 "OCCUPANCY_SNA" ;
VAL_ 899 VCRIGHT_3RowLeftOccupancyStatus 0 "UNOCCUPIED" 1 "OCCUPIED" 2 "OCCUPANCY_FAULTED" 3 "OCCUPANCY_SNA" ;
VAL_ 899 VCRIGHT_3RowRightBuckleStatus 0 "UNLATCHED" 1 "LATCHED" 2 "FAULTED" 3 "SNA" ;
VAL_ 899 VCRIGHT_3RowLeftBuckleStatus 0 "UNLATCHED" 1 "LATCHED" 2 "FAULTED" 3 "SNA" ;
VAL_ 899 VCRIGHT_rearRightOccupancyStatus 0 "UNOCCUPIED" 1 "OCCUPIED" 2 "OCCUPANCY_FAULTED" 3 "OCCUPANCY_SNA" ;
VAL_ 899 VCRIGHT_rearRightBuckleStatus 0 "UNLATCHED" 1 "LATCHED" 2 "FAULTED" 3 "SNA" ;
VAL_ 899 VCRIGHT_rearCenterBuckleStatus 0 "UNLATCHED" 1 "LATCHED" 2 "FAULTED" 3 "SNA" ;
VAL_ 899 VCRIGHT_frontBuckleStatus 0 "UNLATCHED" 1 "LATCHED" 2 "FAULTED" 3 "SNA" ;
VAL_ 899 VCRIGHT_frontOccupancyStatus 0 "UNOCCUPIED" 1 "OCCUPIED" 2 "OCCUPANCY_FAULTED" 3 "NOT_CONFIGURED" 7 "OCCUPANCY_SNA" ;
VAL_ 905 DAS_longCollisionWarning 0 "NONE" 1 "VEHICLE_UNKNOWN" 2 "PEDESTRIAN" 3 "IPSO" 4 "STOPSIGN_STOPLINE" 5 "TFL_STOPLINE" 6 "VEHICLE_CIPV" 7 "VEHICLE_CUTIN" 8 "VEHICLE_MCVL" 9 "VEHICLE_MCVL2" 10 "VEHICLE_MCVR" 11 "VEHICLE_MCVR2" 12 "VEHICLE_CIPV2" 15 "SNA" ;
VAL_ 905 DAS_ppOffsetDesiredRamp 128 "PP_NO_OFFSET" ;
VAL_ 905 DAS_driverInteractionLevel 0 "DRIVER_INTERACTING" 1 "DRIVER_NOT_INTERACTING" 2 "CONTINUED_DRIVER_NOT_INTERACTING" ;
VAL_ 905 DAS_robState 0 "INHIBITED" 1 "MEASURE" 2 "ACTIVE" 3 "MAPLESS" ;
VAL_ 905 DAS_radarTelemetry 0 "IDLE" 1 "NORMAL" 2 "URGENT" ;
VAL_ 905 DAS_lssState 0 "FAULT" 1 "LDW" 2 "LKA" 3 "ELK" 4 "MONITOR" 5 "BLINDSPOT" 6 "ABORT" 7 "OFF" ;
VAL_ 905 DAS_ACC_report 0 "TARGET_NONE" 1 "TARGET_CIPV" 2 "TARGET_IN_FRONT_OF_CIPV" 3 "TARGET_MCVL" 4 "TARGET_MCVR" 5 "TARGET_CUTIN" 6 "TARGET_TYPE_STOP_SIGN" 7 "TARGET_TYPE_TRAFFIC_LIGHT" 8 "TARGET_TYPE_IPSO" 9 "TARGET_TYPE_FAULT" 10 "CSA" 11 "LC_HANDS_ON_REQD_STRUCK_OUT" 12 "LC_EXTERNAL_STATE_ABORTING" 13 "LC_EXTERNAL_STATE_ABORTED" 14 "LC_EXTERNAL_STATE_ACTIVE_RESTRICTED" 15 "RADAR_OBJ_ONE" 16 "RADAR_OBJ_TWO" 17 "TARGET_MCP" 18 "FLEET_SPEEDS" 19 "MCVLR_DPP" 20 "MCVLR_IN_PATH" 21 "CIPV_CUTTING_OUT" 22 "RADAR_OBJ_FIVE" 23 "CAMERA_ONLY" 24 "BEHAVIOR_REPORT" ;
VAL_ 905 DAS_pmmCameraFaultReason 0 "NO_FAULT" 1 "BLOCKED_FRONT" 2 "INVALID_MIA" ;
VAL_ 905 DAS_pmmSysFaultReason 0 "NONE" 1 "DAS_DISABLED" 2 "SPEED" 3 "DI_FAULT" 4 "STEERING_ANGLE_RATE" 5 "DISABLED_BY_USER" 6 "ROAD_TYPE" 7 "BRAKE_PEDAL_INHIBIT" ;
VAL_ 905 DAS_pmmRadarFaultReason 0 "NO_FAULT" 1 "BLOCKED_FRONT" 2 "INVALID_MIA" ;
VAL_ 905 DAS_pmmUltrasonicsFaultReason 0 "NO_FAULT" 1 "BLOCKED_FRONT" 2 "BLOCKED_REAR" 3 "BLOCKED_BOTH" 4 "INVALID_MIA" ;
VAL_ 905 DAS_activationFailureStatus 0 "IDLE" 1 "FAILED_1" 2 "FAILED_2" ;
VAL_ 905 DAS_pmmLoggingRequest 0 "FALSE" 1 "TRUE" ;
VAL_ 905 DAS_pmmObstacleSeverity 0 "NONE" 1 "IMMINENT_REAR" 2 "IMMINENT_FRONT" 3 "BRAKE_REQUEST" 4 "CRASH_REAR" 5 "CRASH_FRONT" 6 "ACCEL_LIMIT" 7 "SNA" ;
VAL_ 905 DAS_accSpeedLimit 0 "NONE" 1023 "SNA" ;
VAL_ 917 OCS1P_matrixIndex 2 "OCS1P_AlertMatrix2" ;
VAL_ 921 DAS_autoLaneChangeState 0 "UNAVAILABLE_DISABLED" 1 "UNAVAILABLE_NO_LANES" 2 "UNAVAILABLE_SONICS_INVALID" 3 "UNAVAILABLE_TP_FOLLOW" 4 "UNAVAILABLE_EXITING_HIGHWAY" 5 "UNAVAILABLE_VEHICLE_SPEED" 6 "AVAILABLE_ONLY_L" 7 "AVAILABLE_ONLY_R" 8 "AVAILABLE_BOTH" 9 "IN_PROGRESS_L" 10 "IN_PROGRESS_R" 11 "WAITING_FOR_SIDE_OBST_TO_PASS_L" 12 "WAITING_FOR_SIDE_OBST_TO_PASS_R" 13 "WAITING_FOR_FWD_OBST_TO_PASS_L" 14 "WAITING_FOR_FWD_OBST_TO_PASS_R" 15 "ABORT_SIDE_OBSTACLE_PRESENT_L" 16 "ABORT_SIDE_OBSTACLE_PRESENT_R" 17 "ABORT_POOR_VIEW_RANGE" 18 "ABORT_LC_HEALTH_BAD" 19 "ABORT_BLINKER_TURNED_OFF" 20 "ABORT_OTHER_REASON" 21 "UNAVAILABLE_SOLID_LANE_LINE" 22 "BLOCKED_VEH_TTC_L" 23 "BLOCKED_VEH_TTC_AND_USS_L" 24 "BLOCKED_VEH_TTC_R" 25 "BLOCKED_VEH_TTC_AND_USS_R" 26 "BLOCKED_LANE_TYPE_L" 27 "BLOCKED_LANE_TYPE_R" 28 "WAITING_HANDS_ON" 29 "ABORT_TIMEOUT" 30 "ABORT_MISSION_PLAN_INVALID" 31 "SNA" ;
VAL_ 921 DAS_autopilotHandsOnState 0 "NOT_REQD" 1 "REQD_DETECTED" 2 "REQD_NOT_DETECTED" 3 "REQD_VISUAL" 4 "REQD_CHIME_1" 5 "REQD_CHIME_2" 6 "REQD_SLOWING" 7 "REQD_STRUCK_OUT" 8 "SUSPENDED" 9 "REQD_ESCALATED_CHIME_1" 10 "REQD_ESCALATED_CHIME_2" 15 "SNA" ;
VAL_ 921 DAS_fleetSpeedState 0 "UNAVAILABLE" 1 "AVAILABLE" 2 "ACTIVE" 3 "HOLD" ;
VAL_ 921 DAS_laneDepartureWarning 0 "NONE" 1 "LEFT_WARNING" 2 "RIGHT_WARNING" 3 "LEFT_WARNING_SEVERE" 4 "RIGHT_WARNING_SEVERE" 5 "SNA" ;
VAL_ 921 DAS_sideCollisionInhibit 0 "NO_INHIBIT" 1 "INHIBIT" ;
VAL_ 921 DAS_sideCollisionWarning 0 "NONE" 1 "WARN_LEFT" 2 "WARN_RIGHT" 3 "WARN_LEFT_RIGHT" ;
VAL_ 921 DAS_sideCollisionAvoid 0 "NONE" 1 "AVOID_LEFT" 2 "AVOID_RIGHT" 3 "SNA" ;
VAL_ 921 DAS_lssState 0 "FAULT" 1 "LDW" 2 "LKA" 3 "ELK" 4 "MONITOR" 5 "BLINDSPOT" 6 "ABORT" 7 "OFF" ;
VAL_ 921 DAS_autoparkReady 0 "UNAVAILABLE" 1 "READY" ;
VAL_ 921 DAS_forwardCollisionWarning 0 "NONE" 1 "FORWARD_COLLISION_WARNING" 3 "SNA" ;
VAL_ 921 DAS_heaterState 0 "OFF_SNA" 1 "ON" ;
VAL_ 921 DAS_visionOnlySpeedLimit 0 "UNKNOWN_SNA" 31 "NONE" ;
VAL_ 921 DAS_suppressSpeedWarning 0 "Do_Not_Suppress" 1 "Suppress_Speed_Warning" ;
VAL_ 921 DAS_fusedSpeedLimit 0 "UNKNOWN_SNA" 31 "NONE" ;
VAL_ 921 DAS_blindSpotRearRight 0 "NO_WARNING" 1 "WARNING_LEVEL_1" 2 "WARNING_LEVEL_2" 3 "SNA" ;
VAL_ 921 DAS_blindSpotRearLeft 0 "NO_WARNING" 1 "WARNING_LEVEL_1" 2 "WARNING_LEVEL_2" 3 "SNA" ;
VAL_ 921 DAS_autopilotState 0 "DISABLED" 1 "UNAVAILABLE" 2 "AVAILABLE" 3 "ACTIVE_NOMINAL" 4 "ACTIVE_RESTRICTED" 5 "ACTIVE_NAV" 6 "ACTIVE_FSD" 8 "ABORTING" 9 "ABORTED" 14 "FAULT" 15 "SNA" ;
VAL_ 925 IBST_internalState 0 "NO_MODE_ACTIVE" 1 "PRE_DRIVE_CHECK" 2 "LOCAL_BRAKE_REQUEST" 3 "EXTERNAL_BRAKE_REQUEST" 4 "DIAGNOSTIC" 5 "TRANSITION_TO_IDLE" 6 "POST_DRIVE_CHECK" ;
VAL_ 925 IBST_driverBrakeApply 0 "NOT_INIT_OR_OFF" 1 "BRAKES_NOT_APPLIED" 2 "DRIVER_APPLYING_BRAKES" 3 "FAULT" ;
VAL_ 925 IBST_iBoosterStatus 0 "OFF" 1 "INIT" 2 "FAILURE" 3 "DIAGNOSTIC" 4 "ACTIVE_GOOD_CHECK" 5 "READY" 6 "ACTUATION" ;
VAL_ 947 UI_dcr12VThreshold 0 "OFF" 1 "40_MILLIOHMS" 2 "35_MILLIOHMS" 3 "30_MILLIOHMS" 4 "27_MILLIOHMS" 5 "24_MILLIOHMS" 6 "22_MILLIOHMS" 7 "20_MILLIOHMS" ;
VAL_ 947 UI_shorted12VCellTestMode 0 "DISABLED" 1 "SHADOW" 2 "ACTIVE" ;
VAL_ 947 UI_autopilotPowerStateRequest 0 "NOMINAL" 1 "SENTRY" 2 "SUSPEND" ;
VAL_ 947 UI_summonState 0 "SNA" 1 "IDLE" 2 "PRE_PRIMED" 3 "ACTIVE" ;
VAL_ 947 UI_lightSwitch 0 "AUTO" 1 "ON" 2 "PARKING" 3 "OFF" 4 "SNA" ;
VAL_ 947 UI_trunkRequest 0 "NONE" 1 "MOVE" 2 "STOP" 3 "SNA" ;
VAL_ 962 VCLEFT_rearCenterBuckleSwitch 0 "SNA" 1 "OFF" 2 "ON" 3 "FAULT" ;
VAL_ 962 VCLEFT_rearRightOccupancySwitch 0 "SNA" 1 "OFF" 2 "ON" 3 "FAULT" ;
VAL_ 962 VCLEFT_rearLeftOccupancySwitch 0 "SNA" 1 "OFF" 2 "ON" 3 "FAULT" ;
VAL_ 962 VCLEFT_rearCenterOccupancySwitch 0 "SNA" 1 "OFF" 2 "ON" 3 "FAULT" ;
VAL_ 962 VCLEFT_rearLeftBuckleSwitch 0 "SNA" 1 "OFF" 2 "ON" 3 "FAULT" ;
VAL_ 962 VCLEFT_frontOccupancySwitch 0 "SNA" 1 "OFF" 2 "ON" 3 "FAULT" ;
VAL_ 962 VCLEFT_frontBuckleSwitch 0 "SNA" 1 "OFF" 2 "ON" 3 "FAULT" ;
VAL_ 962 VCLEFT_frontSeatLumbarOut 0 "SNA" 1 "OFF" 2 "ON" 3 "FAULT" ;
VAL_ 962 VCLEFT_frontSeatLumbarIn 0 "SNA" 1 "OFF" 2 "ON" 3 "FAULT" ;
VAL_ 962 VCLEFT_frontSeatLumbarUp 0 "SNA" 1 "OFF" 2 "ON" 3 "FAULT" ;
VAL_ 962 VCLEFT_frontSeatLumbarDown 0 "SNA" 1 "OFF" 2 "ON" 3 "FAULT" ;
VAL_ 962 VCLEFT_frontSeatBackrestForward 0 "SNA" 1 "OFF" 2 "ON" 3 "FAULT" ;
VAL_ 962 VCLEFT_frontSeatBackrestBack 0 "SNA" 1 "OFF" 2 "ON" 3 "FAULT" ;
VAL_ 962 VCLEFT_frontSeatLiftUp 0 "SNA" 1 "OFF" 2 "ON" 3 "FAULT" ;
VAL_ 962 VCLEFT_frontSeatLiftDown 0 "SNA" 1 "OFF" 2 "ON" 3 "FAULT" ;
VAL_ 962 VCLEFT_frontSeatTiltUp 0 "SNA" 1 "OFF" 2 "ON" 3 "FAULT" ;
VAL_ 962 VCLEFT_swcLeftTiltLeft 0 "SNA" 1 "OFF" 2 "ON" 3 "FAULT" ;
VAL_ 962 VCLEFT_frontSeatTiltDown 0 "SNA" 1 "OFF" 2 "ON" 3 "FAULT" ;
VAL_ 962 VCLEFT_swcRightPressed 0 "SNA" 1 "OFF" 2 "ON" 3 "FAULT" ;
VAL_ 962 VCLEFT_frontSeatTrackForward 0 "SNA" 1 "OFF" 2 "ON" 3 "FAULT" ;
VAL_ 962 VCLEFT_swcRightTiltRight 0 "SNA" 1 "OFF" 2 "ON" 3 "FAULT" ;
VAL_ 962 VCLEFT_frontSeatTrackBack 0 "SNA" 1 "OFF" 2 "ON" 3 "FAULT" ;
VAL_ 962 VCLEFT_swcRightTiltLeft 0 "SNA" 1 "OFF" 2 "ON" 3 "FAULT" ;
VAL_ 962 VCLEFT_rightMirrorTilt 0 "STOP" 1 "DOWN" 2 "UP" 3 "RIGHT" 4 "LEFT" ;
VAL_ 962 VCLEFT_swcLeftPressed 0 "SNA" 1 "OFF" 2 "ON" 3 "FAULT" ;
VAL_ 962 VCLEFT_swcLeftTiltRight 0 "SNA" 1 "OFF" 2 "ON" 3 "FAULT" ;
VAL_ 962 VCLEFT_switchStatusIndex 0 "0" 1 "1" ;
VAL_ 963 VCRIGHT_rearRightOccupancySwitch 0 "SNA" 1 "OFF" 2 "ON" 3 "FAULT" ;
VAL_ 963 VCRIGHT_rearCenterBuckleSwitch 0 "SNA" 1 "OFF" 2 "ON" 3 "FAULT" ;
VAL_ 963 VCRIGHT_frontOccupancySwitch 0 "SNA" 1 "OFF" 2 "ON" 3 "FAULT" ;
VAL_ 963 VCRIGHT_frontBuckleSwitch 0 "SNA" 1 "OFF" 2 "ON" 3 "FAULT" ;
VAL_ 963 VCRIGHT_frontSeatLumbarOut 0 "SNA" 1 "OFF" 2 "ON" 3 "FAULT" ;
VAL_ 963 VCRIGHT_frontSeatLumbarIn 0 "SNA" 1 "OFF" 2 "ON" 3 "FAULT" ;
VAL_ 963 VCRIGHT_frontSeatLumbarUp 0 "SNA" 1 "OFF" 2 "ON" 3 "FAULT" ;
VAL_ 963 VCRIGHT_frontSeatLumbarDown 0 "SNA" 1 "OFF" 2 "ON" 3 "FAULT" ;
VAL_ 963 VCRIGHT_frontSeatBackrestForward 0 "SNA" 1 "OFF" 2 "ON" 3 "FAULT" ;
VAL_ 963 VCRIGHT_frontSeatBackrestBack 0 "SNA" 1 "OFF" 2 "ON" 3 "FAULT" ;
VAL_ 963 VCRIGHT_frontSeatLiftUp 0 "SNA" 1 "OFF" 2 "ON" 3 "FAULT" ;
VAL_ 963 VCRIGHT_frontSeatLiftDown 0 "SNA" 1 "OFF" 2 "ON" 3 "FAULT" ;
VAL_ 963 VCRIGHT_frontSeatTiltUp 0 "SNA" 1 "OFF" 2 "ON" 3 "FAULT" ;
VAL_ 963 VCRIGHT_frontSeatTiltDown 0 "SNA" 1 "OFF" 2 "ON" 3 "FAULT" ;
VAL_ 963 VCRIGHT_frontSeatTrackForward 0 "SNA" 1 "OFF" 2 "ON" 3 "FAULT" ;
VAL_ 963 VCRIGHT_frontSeatTrackBack 0 "SNA" 1 "OFF" 2 "ON" 3 "FAULT" ;
VAL_ 963 VCRIGHT_switchStatusIndex 0 "0" 1 "1" 2 "INVALID" ;
VAL_ 969 APS_arbState 0 "INIT" 1 "IDLE" 2 "PRIMARY" 3 "SECONDARY" 4 "FAULT" 5 "MIA" 6 "UNKNOWN" 7 "COUNT" ;
VAL_ 969 APS_heaterStateDebug 0 "OFF" 1 "ON_HEATING" 2 "ON_NOT_HEATING" 3 "FAULT_OPEN" 4 "FAULT_SHORT" 7 "SNA" ;
VAL_ 969 APS_apbPowerStateReason 0 "UI_POWER_STATE_REQUEST" 1 "AP_WDOG_UNHEALTHY" 2 "AP_NM_REASON_SET" 3 "AP_NOT_IN_PARK" 4 "GTW_GOTO_FULL_POWER" 5 "AP_POWER_REQUEST_HYSTERESIS" 6 "AP_POWER_REQUEST_OVERHEATING" 7 "AP_POWER_REQUEST_OVERRIDE" 8 "VC_POWER_REQUEST" 9 "LOADSHED_POWER_REQUEST_PENDING" ;
VAL_ 969 APS_apbPowerStateRequest 0 "NOMINAL" 1 "SENTRY" 2 "SUSPEND" 3 "SLEEP" ;
VAL_ 969 APS_appPowerStateReason 0 "UI_POWER_STATE_REQUEST" 1 "AP_WDOG_UNHEALTHY" 2 "AP_NM_REASON_SET" 3 "AP_NOT_IN_PARK" 4 "GTW_GOTO_FULL_POWER" 5 "AP_POWER_REQUEST_HYSTERESIS" 6 "AP_POWER_REQUEST_OVERHEATING" 7 "AP_POWER_REQUEST_OVERRIDE" 8 "VC_POWER_REQUEST" 9 "LOADSHED_POWER_REQUEST_PENDING" ;
VAL_ 969 APS_appPowerStateRequest 0 "NOMINAL" 1 "SENTRY" 2 "SUSPEND" 3 "SLEEP" ;
VAL_ 969 APS_locLimitReason 0 "NOMINAL_DEFAULT" 1 "NOT_IN_DRIVE" 2 "ACC_AND_AEB_UNAVAILABLE" 3 "PRIMARY_AP_NOT_HEALTHY" 4 "RADAR_NOT_HEALTHY" 5 "NO_RADAR_TARGET" 6 "LOC_MONITOR_UNAVAILABLE" 7 "LOC_LIMITS_EXTENDED" ;
VAL_ 969 APS_apbGpioState 0 "PWR_DOWN_REBOOT" 1 "DISABLED" 2 "CRITICAL" 3 "HEALTHY" ;
VAL_ 969 APS_apbStatusMonitorState 0 "STATE_UNKNOWN" 1 "STATE_PWR_OFF" 2 "STATE_INIT" 3 "STATE_NOMINAL" 4 "STATE_CRITICAL" 5 "STATE_SHUTTING_DOWN" 6 "STATE_RECOVERY" 7 "NUM_STATES" ;
VAL_ 969 APS_eacInternalState 0 "STATE_INIT" 1 "STATE_MOMENTARY" 2 "STATE_CONTINUOUS" 3 "STATE_AUTOPARK" 4 "STATE_INHIBIT" 5 "STATE_OVERRIDE" 6 "STATE_LSS" 7 "NUM_STATES" ;
VAL_ 969 APS_appGpioState 0 "PWR_DOWN_REBOOT" 1 "DISABLED" 2 "CRITICAL" 3 "HEALTHY" ;
VAL_ 969 APS_canMaster 0 "APS" 1 "APP" 2 "APB" 3 "SNA" ;
VAL_ 969 APS_vehBehaviorState 0 "STATE_UNKNOWN" 1 "STATE_APS_AVAILABLE" 2 "STATE_APS_CONTROL" 3 "STATE_APS_BRIDGE_APP" 4 "STATE_APS_BRIDGE_APB" 5 "STATE_APS_FAIL_SAFE" 6 "STATE_APS_OVERRIDE" 7 "STATE_SYSTEM_FAULT" 8 "NUM_STATES" ;
VAL_ 969 APS_appStatusMonitorState 0 "STATE_UNKNOWN" 1 "STATE_PWR_OFF" 2 "STATE_INIT" 3 "STATE_NOMINAL" 4 "STATE_CRITICAL" 5 "STATE_SHUTTING_DOWN" 6 "STATE_RECOVERY" 7 "NUM_STATES" ;
VAL_ 977 EPAS3S_resyncStatus 0 "PENDING" 1 "COMPLETE" ;
VAL_ 991 UI_sentryModeState 0 "OFF" 1 "IDLE" 2 "ARMED" 3 "AWARE" 4 "PANIC" 5 "QUIET" 6 "SNA" ;
VAL_ 991 UI_linkState 0 "NONE" 1 "CELL" 2 "WIFI" ;
VAL_ 1011 UI_odometer 16777215 "SNA" ;
VAL_ 1012 APP_backupCalibProgress 127 "SNA" ;
VAL_ 1012 APP_fisheyeCalibProgress 127 "SNA" ;
VAL_ 1012 APP_lPillarCalibProgress 127 "SNA" ;
VAL_ 1012 APP_lRepeatCalibProgress 127 "SNA" ;
VAL_ 1012 APP_mainCalibProgress 127 "SNA" ;
VAL_ 1012 APP_narrowCalibProgress 127 "SNA" ;
VAL_ 1012 APP_rPillarCalibProgress 127 "SNA" ;
VAL_ 1012 APP_rRepeatCalibProgress 127 "SNA" ;
VAL_ 1012 APP_backupCalibTime 127 "SNA" ;
VAL_ 1012 APP_fisheyeCalibTime 127 "SNA" ;
VAL_ 1012 APP_lPillarCalibTime 127 "SNA" ;
VAL_ 1012 APP_lRepeatCalibTime 127 "SNA" ;
VAL_ 1012 APP_mainCalibTime 127 "SNA" ;
VAL_ 1012 APP_narrowCalibTime 127 "SNA" ;
VAL_ 1012 APP_rPillarCalibTime 127 "SNA" ;
VAL_ 1012 APP_rRepeatCalibTime 127 "SNA" ;
VAL_ 1012 APP_backupCamExtYawCal 511 "SNA" ;
VAL_ 1012 APP_fisheyeCamExtYawCal 511 "SNA" ;
VAL_ 1012 APP_lPillarCamExtYawCal 511 "SNA" ;
VAL_ 1012 APP_lRepeatCamExtYawCal 511 "SNA" ;
VAL_ 1012 APP_mainCamExtYawCal 511 "SNA" ;
VAL_ 1012 APP_narrowCamExtYawCal 511 "SNA" ;
VAL_ 1012 APP_rPillarCamExtYawCal 511 "SNA" ;
VAL_ 1012 APP_rRepeatCamExtYawCal 511 "SNA" ;
VAL_ 1012 APP_backupCamExtPitchCal 511 "SNA" ;
VAL_ 1012 APP_fisheyeCamExtPitchCal 511 "SNA" ;
VAL_ 1012 APP_lPillarCamExtPitchCal 511 "SNA" ;
VAL_ 1012 APP_lRepeatCamExtPitchCal 511 "SNA" ;
VAL_ 1012 APP_mainCamExtPitchCal 511 "SNA" ;
VAL_ 1012 APP_narrowCamExtPitchCal 511 "SNA" ;
VAL_ 1012 APP_rPillarCamExtPitchCal 511 "SNA" ;
VAL_ 1012 APP_rRepeatCamExtPitchCal 511 "SNA" ;
VAL_ 1012 APP_cameraPosition 0 "INVALID" 1 "MAIN" 2 "NARROW" 3 "FISHEYE" 4 "L_PILLAR" 5 "R_PILLAR" 6 "L_REPEATER" 7 "R_REPEATER" 8 "BACKUP" 9 "SELFIE" ;
VAL_ 1013 VCFRONT_highBeamLatchingState 0 "SNA" 1 "UNLATCHED" 2 "LATCHING" 3 "LATCHED" ;
VAL_ 1013 VCFRONT_lightingCoreState 0 "OFF" 1 "POS_PARK" 2 "DRL" 3 "DRL_PLUS_REAR_POS_PARK" 4 "LOW_BEAMS" 15 "SNA" ;
VAL_ 1013 VCFRONT_switchLightingBrightness 255 "SNA" ;
VAL_ 1013 VCFRONT_ambientLightingBrightnes 255 "SNA" ;
VAL_ 1013 VCFRONT_hazardLightRequest 0 "NONE" 1 "BUTTON" 2 "LOCK" 3 "UNLOCK" 4 "MISLOCK" 5 "CRASH" 6 "CAR_ALARM" 7 "DAS" 8 "UDS" ;
VAL_ 1013 VCFRONT_indicatorRightRequest 0 "OFF" 1 "ACTIVE_LOW" 2 "ACTIVE_HIGH" ;
VAL_ 1013 VCFRONT_indicatorLeftRequest 0 "OFF" 1 "ACTIVE_LOW" 2 "ACTIVE_HIGH" ;
VAL_ 1016 UI_source3D 0 "Z_FROM_MAP" 1 "Z_FROM_PATH_PREDICTION" 2 "XYZ_PREDICTION" ;
VAL_ 1016 UI_smartSummonType 0 "PIN_DROP" 1 "FIND_ME" 2 "SMART_AUTOPARK" ;
VAL_ 1016 UI_ulcBlindSpotConfig 0 "STANDARD" 1 "AGGRESSIVE" 2 "MAD_MAX" ;
VAL_ 1016 UI_ulcSpeedConfig 0 "DISABLED" 1 "MILD" 2 "AVERAGE" 3 "MAD_MAX" ;
VAL_ 1016 UI_followNavRouteEnable 0 "OFF" 1 "ON" ;
VAL_ 1016 UI_accFollowDistanceSetting 0 "1" 1 "2" 2 "3" 3 "4" 4 "5" 5 "6" 6 "7" 7 "SNA" ;
VAL_ 1016 UI_drivingSide 0 "LEFT" 1 "RIGHT" 2 "UNKNOWN" ;
VAL_ 1016 UI_summonReverseDist 63 "SNA" ;
VAL_ 1016 UI_selfParkRequest 0 "NONE" 1 "SELF_PARK_FORWARD" 2 "SELF_PARK_REVERSE" 3 "ABORT" 4 "PRIME" 5 "PAUSE" 6 "RESUME" 7 "AUTO_SUMMON_FORWARD" 8 "AUTO_SUMMON_REVERSE" 9 "AUTO_SUMMON_CANCEL" 10 "AUTO_SUMMON_PRIMED" 11 "SMART_SUMMON" 12 "SMART_SUMMON_NO_OP" 15 "SNA" ;
VAL_ 1016 UI_summonEntryType 0 "STRAIGHT" 1 "TURN_RIGHT" 2 "TURN_LEFT" 3 "SNA" ;
VAL_ 1016 UI_summonExitType 0 "STRAIGHT" 1 "TURN_RIGHT" 2 "TURN_LEFT" 3 "SNA" ;
VAL_ 1016 UI_lssElkEnabled 0 "OFF" 1 "ON" ;
VAL_ 1016 UI_curvatureDatabaseOnly 0 "OFF" 1 "ON" ;
VAL_ 1016 UI_visionSpeedType 0 "DISABLED" 1 "ONE_SECOND" 2 "TWO_SECOND" 3 "OPTIMIZED" ;
VAL_ 1016 UI_fuseVehiclesDisable 0 "ON" 1 "OFF" ;
VAL_ 1016 UI_fuseHPPDisable 0 "ON" 1 "OFF" ;
VAL_ 1016 UI_fuseLanesDisable 0 "ON" 1 "OFF" ;
VAL_ 1016 UI_handsOnRequirementDisable 0 "ON" 1 "OFF" ;
VAL_ 1016 UI_driveOnMapsEnable 0 "OFF" 1 "ON" ;
VAL_ 1016 UI_roadCheckDisable 0 "ON" 1 "OFF" ;
VAL_ 1016 UI_exceptionListEnable 0 "OFF" 1 "ON" ;
VAL_ 1016 UI_lssLdwEnabled 0 "OFF" 1 "ON" ;
VAL_ 1016 UI_lssLkaEnabled 0 "OFF" 1 "ON" ;
VAL_ 1016 UI_curvSpeedAdaptDisable 0 "ON" 1 "OFF" ;
VAL_ 1016 UI_autopilotControlRequest 0 "LEGACY_LAT_CTRL" 1 "NEXT_GEN_CTRL" ;
VAL_ 1018 APP_backupCameraLUX 254 "SATURATED" 255 "SNA" ;
VAL_ 1018 APP_rPillarCameraLUX 254 "SATURATED" 255 "SNA" ;
VAL_ 1018 APP_lPillarCameraLUX 254 "SATURATED" 255 "SNA" ;
VAL_ 1018 APP_rRepeatCameraLUX 254 "SATURATED" 255 "SNA" ;
VAL_ 1018 APP_lRepeatCameraLUX 254 "SATURATED" 255 "SNA" ;
VAL_ 1018 APP_fisheyeCameraLUX 254 "SATURATED" 255 "SNA" ;
VAL_ 1018 APP_narrowCameraLUX 254 "SATURATED" 255 "SNA" ;
VAL_ 1018 APP_mainCameraLUX 254 "SATURATED" 255 "SNA" ;
VAL_ 1020 APP_pascalHeaterDecision 0 "OFF" 1 "ON" ;
VAL_ 1020 APP_parkerExtTemperature 0 "UNKNOWN" ;
VAL_ 1020 APP_pascalExtTemperature 0 "UNKNOWN" ;
VAL_ 1020 APP_parkerBTemperature 0 "UNKNOWN" ;
VAL_ 1020 APP_parkerATemperature 0 "UNKNOWN" ;
VAL_ 1020 APP_pascalTemperature 0 "UNKNOWN" ;
VAL_ 1020 APP_decisionTemperature 0 "UNKNOWN" ;
VAL_ 1022 APP_summonState 0 "INIT" 1 "IDLE" 2 "ARMED" 3 "ACTIVE" 4 "COMPLETE" 5 "FAULT" 6 "UNAVAILABLE" ;
VAL_ 1033 DAS_nmKeepAwakeReason 0 "NONE_SNA" 1 "CTRS_CLOSED" 2 "CRITICAL_ALERT" 3 "FC_CTR_CLEANING" 4 "HVP_ACTIVE" 5 "BMS_ACTIVE" 6 "CP_ACTIVE" ;
VAL_ 1033 DAS_nmWakeUpReason 0 "NONE" 1 "CAN_VEH" 2 "CAN_HVS" 3 "WANTTOCHARGE" 4 "CRITICALALERT" 5 "WANTTOWARM" ;
VAL_ 1049 APS_nmKeepAwakeReason 0 "NONE_SNA" 1 "CTRS_CLOSED" 2 "CRITICAL_ALERT" 3 "FC_CTR_CLEANING" 4 "HVP_ACTIVE" 5 "BMS_ACTIVE" 6 "CP_ACTIVE" ;
VAL_ 1049 APS_nmWakeUpReason 0 "NONE" 1 "CAN_VEH" 2 "CAN_HVS" 3 "WANTTOCHARGE" 4 "CRITICALALERT" 5 "WANTTOWARM" ;
VAL_ 1056 APS_B_faultState 0 "NONE" 1 "GIC" 2 "MIF_ECC_CORRECTED" 3 "MIF_ECC_UNCORRECTED" 4 "MIF0_DFI_ALERT" 5 "MIF1_DFI_ALERT" 6 "MIF2_DFI_ALERT" 7 "MIF3_DFI_ALERT" 8 "MIF4_DFI_ALERT" 9 "MIF5_DFI_ALERT" 10 "MIF6_DFI_ALERT" 11 "MIF7_DFI_ALERT" 12 "MIF_ECC_AP" 13 "DROOP_CPUCL0" 14 "DROOP_CPUCL1" 15 "DROOP_CPUCL2" 16 "DROOP_GPU" 17 "DROOP_TRIP" 18 "CPU_FAULT" 19 "WDT" 20 "TRIP0_FAULT" 21 "TRIP1_FAULT" 22 "SOFTWARE_FAULT" 23 "SCS" 24 "UNEXPECTED" 25 "MIA" 26 "UNKNOWN" 27 "COUNT" ;
VAL_ 1056 APS_B_resetState 0 "NOT_RESETTING" 1 "RESETTING" 2 "FAULT" 3 "MIA" 4 "UNKNOWN" 5 "COUNT" ;
VAL_ 1056 APS_B_sleepState 0 "IDLE" 1 "WAIT_FOR_BUS_SILENCE" 2 "READY" 3 "GOING_TO_SLEEP" 4 "SLEEPING" 5 "ABORT" 6 "FAULT" 7 "MIA" 8 "UNKNOWN" 9 "COUNT" ;
VAL_ 1056 APS_B_powerState 0 "IDLE" 1 "AP_ON_PREPARE" 2 "AP_ON_PREPARE_WAIT_FOR_ACK" 3 "AP_ON_PREPARE_WAIT_FOR_RESPONSE" 4 "AP_ON_READY" 5 "AP_ON_READY_WAIT_FOR_ACK" 6 "AP_ON_READY_WAIT_FOR_RESPONSE" 7 "AP_BOOTING" 8 "AP_IN_COREBOOT" 9 "AP_ON" 10 "AP_WAIT_FOR_SHUTDOWN" 11 "AP_OFF_PREPARE" 12 "AP_OFF_READY" 13 "AP_OFF_READY_WAIT_FOR_ACK" 14 "AP_OFF_READY_WAIT_FOR_RESPONSE" 15 "AP_OFF_ABORT" 16 "AP_OFF_ABORT_WAIT_FOR_ACK" 17 "AP_SUSPENDED" 18 "SOC_OFF_READY" 19 "SOC_OFF" 20 "SOC_OFF_ABORT" 21 "FAULT" 22 "MIA" 23 "UNKNOWN" 24 "COUNT" ;
VAL_ 1056 APS_B_arbState 0 "INIT" 1 "IDLE" 2 "PRIMARY" 3 "SECONDARY" 4 "FAULT" 5 "MIA" 6 "UNKNOWN" 7 "COUNT" ;
VAL_ 1056 APS_secondaryTurbo 0 "A" 1 "B" 2 "UNKNOWN" ;
VAL_ 1056 APS_A_faultState 0 "NONE" 1 "GIC" 2 "MIF_ECC_CORRECTED" 3 "MIF_ECC_UNCORRECTED" 4 "MIF0_DFI_ALERT" 5 "MIF1_DFI_ALERT" 6 "MIF2_DFI_ALERT" 7 "MIF3_DFI_ALERT" 8 "MIF4_DFI_ALERT" 9 "MIF5_DFI_ALERT" 10 "MIF6_DFI_ALERT" 11 "MIF7_DFI_ALERT" 12 "MIF_ECC_AP" 13 "DROOP_CPUCL0" 14 "DROOP_CPUCL1" 15 "DROOP_CPUCL2" 16 "DROOP_GPU" 17 "DROOP_TRIP" 18 "CPU_FAULT" 19 "WDT" 20 "TRIP0_FAULT" 21 "TRIP1_FAULT" 22 "SOFTWARE_FAULT" 23 "SCS" 24 "UNEXPECTED" 25 "MIA" 26 "UNKNOWN" 27 "COUNT" ;
VAL_ 1056 APS_A_resetState 0 "NOT_RESETTING" 1 "RESETTING" 2 "FAULT" 3 "MIA" 4 "UNKNOWN" 5 "COUNT" ;
VAL_ 1056 APS_A_sleepState 0 "IDLE" 1 "WAIT_FOR_BUS_SILENCE" 2 "READY" 3 "GOING_TO_SLEEP" 4 "SLEEPING" 5 "ABORT" 6 "FAULT" 7 "MIA" 8 "UNKNOWN" 9 "COUNT" ;
VAL_ 1056 APS_A_powerState 0 "IDLE" 1 "AP_ON_PREPARE" 2 "AP_ON_PREPARE_WAIT_FOR_ACK" 3 "AP_ON_PREPARE_WAIT_FOR_RESPONSE" 4 "AP_ON_READY" 5 "AP_ON_READY_WAIT_FOR_ACK" 6 "AP_ON_READY_WAIT_FOR_RESPONSE" 7 "AP_BOOTING" 8 "AP_IN_COREBOOT" 9 "AP_ON" 10 "AP_WAIT_FOR_SHUTDOWN" 11 "AP_OFF_PREPARE" 12 "AP_OFF_READY" 13 "AP_OFF_READY_WAIT_FOR_ACK" 14 "AP_OFF_READY_WAIT_FOR_RESPONSE" 15 "AP_OFF_ABORT" 16 "AP_OFF_ABORT_WAIT_FOR_ACK" 17 "AP_SUSPENDED" 18 "SOC_OFF_READY" 19 "SOC_OFF" 20 "SOC_OFF_ABORT" 21 "FAULT" 22 "MIA" 23 "UNKNOWN" 24 "COUNT" ;
VAL_ 1056 APS_A_arbState 0 "INIT" 1 "IDLE" 2 "PRIMARY" 3 "SECONDARY" 4 "FAULT" 5 "MIA" 6 "UNKNOWN" 7 "COUNT" ;
VAL_ 1056 APS_primaryTurbo 0 "A" 1 "B" 2 "UNKNOWN" ;
VAL_ 1081 APP_w208_rackDetected 0 "UNKNOWN" 1 "NO_RACK" 2 "RACK_DETECTED" 3 "SNA" ;
VAL_ 1096 UI_anonDebugFlag4 0 "OFF" 1 "ON" ;
VAL_ 1096 UI_anonDebugFlag3 0 "OFF" 1 "ON" ;
VAL_ 1096 UI_anonDebugFlag2 0 "OFF" 1 "ON" ;
VAL_ 1096 UI_anonDebugFlag1 0 "OFF" 1 "ON" ;
VAL_ 1097 APP_w258_aebEvent 0 "NOT_ACTIVE" 1 "ACTIVE" 2 "FAULT" 3 "SNA" ;
VAL_ 1285 ESP_alertState 0 "CLEARED" 1 "SET" ;
VAL_ 1285 ESP_alertID 0 "ALERT_DO_NOT_USE_ZERO" 1 "a001_DriverDoorOpen" 2 "a002_DoorOpen" 3 "a003_TrunkOpen" 4 "a004_FrunkOpen" 5 "a005_HeadlightsOnDoorOpen" 6 "a006_RemoteServiceAlert" 7 "a007_SoftPackConfigMismatch" 8 "a008_TouchScreenError" 9 "a009_SquashfsError" 10 "a010_MapsMissing" 11 "a011_IncorrectMap" 12 "a012_NotOnPrivateProperty" 13 "a013_TPMSHardWarning" 14 "a014_TPMSSoftWarning" 15 "a015_TPMSOverPressureWarning" 16 "a016_TPMSTemperatureWarning" 17 "a017_TPMSSystemFault" 18 "a018_SlipStartOn" 19 "a019_ParkBrakeFault" 20 "a020_SteeringReduced" 21 "a021_RearSeatbeltUnbuckled" 22 "a022_ApeFusesEtc" 23 "a023_CellInternetCheckFailed" 24 "a024_WifiInternetCheckFailed" 25 "a025_WifiOnlineCheckFailed" 26 "a026_ModemResetLoopDetected" 27 "a027_AutoSteerMIA" 28 "a028_FrontTrunkPopupClosed" 29 "a029_ModemMIA" 30 "a030_ModemVMCrash" 31 "a031_BrakeFluidLow" 32 "a032_CellModemRecoveryResets" 33 "a033_ApTrialExpired" 34 "a034_WakeupProblem" 35 "a035_AudioWatchdogKernelError" 36 "a036_AudioWatchdogHfpError" 37 "a037_AudioWatchdogXrunStormError" 38 "a038_AudioWatchdogA2bI2cLockupError" 39 "a039_AudioA2bNeedRediscovery" 40 "a040_HomelinkTransmit" 41 "a041_AudioDmesgXrun" 42 "a042_AudioDmesgRtThrottling" 43 "a043_InvalidMapDataOverride" 44 "a044_AudioDmesgDspException" 45 "a045_ECallNeedsService" 46 "a046_BackupCameraStreamError" 47 "a047_CellRoamingDisallowed" 48 "a048_AudioPremiumAmpCheckFailed" 49 "a049_BrakeShiftRequired" 50 "a050_BackupCameraIPUTimeout" 51 "a051_BackupCameraFrameTimeout" 52 "a052_KernelPanicReported" 53 "a053_QtCarExitError" 54 "a054_AudioBoostPowerBad" 55 "a055_ManualECallDisabled" 56 "a056_ManualECallButtonDisconnected" 57 "a057_CellAntennaDisconnected" 58 "a058_GPSAntennaDisconnected" 59 "a059_ECallSpeakerDisconnected" 60 "a060_ECallMicDisconnected" 61 "a061_SIMTestFailed" 62 "a062_ENSTestFailed" 63 "a063_CellularTestFailed" 64 "a064_ModemFirmwareTestFailed" 65 "a065_WiFiRecoveryReset" 66 "a066_GpuHangDetected" 67 "a067_WarnOnI915" 68 "a068_VideoUnexpectedExit" 69 "a069_VideoUDPTimeout" 70 "a070_VideoPipelineWarning" 71 "a071_VideoPipelineError" 72 "a072_ECallAnalogMicFailed" 73 "a073_ECallDigitalMicFailed" 74 "a074_EMMCHangDetected" 75 "a075_BackupCameraInitError" 76 "a076_NumFalseManualECalls" 77 "a077_AudioA2bMicChannelSwap" 78 "a078_DashcamUsbDriveUnmountable" 79 "a079_DashcamUsbDriveFull" 80 "a080_DashcamUsbDriveSlow" 81 "a081_CellModemSearchExpired" 82 "a082_NumModemRebootStuckInECall" 83 "a083_ECallProxyWatchdogTriggered" 84 "a084_SerializerError" 85 "a085_DeserializerError" 86 "a086_TouchEnumerationError" 87 "a087_BmpReset" 88 "a088_CellRemovableSimMissing" 89 "a089_RadioSoftResetError" 90 "a090_RadioPingFailError" 91 "a091_VehicleLinkStall" 92 "a092_updateStarted" 93 "a093_updateEnded" 94 "a094_ModemPowerOnFailure" 95 "a095_CidStorageRunningLow" 96 "a096_VideodPipelineIssueDetected" 97 "a097_AudiodRestarted" 98 "a098_DiskCheckFailure" 99 "a099_eMMCStatusError" 100 "a100_eMMCFTLError" 101 "a101_wifiStackProblem" 102 "a102_A2bDiscoveryFailed" 103 "a103_UsbHubNotEnumerating" 104 "a104_DashcamUsbDriveMissing" 105 "a105_firmwareReinstallRequested" 106 "a106_rebootBackstopTriggered" 107 "a107_DashcamUsbDriveTooBigForVfatFsck" 108 "a108_DashcamUsbDriveGettingFull" 109 "a109_DashcamUsbDriveTooSmall" 110 "a110_DashcamUsbDriveCorrupt" 111 "a111_DashcamUsbDriveWrongPort" 112 "a112_badUSBDevice" 113 "a113_DashcamHasOnboardSentryClips" ;
VAL_ 1353 APP_buildType 0 "SIGNED" 1 "LOCAL" 3 "REPO" ;
VAL_ 1353 APP_infoIndex 0 "AP_BUILD_TYPE" 1 "FW_GITHASH" 2 "AP_GITHASH" ;
VAL_ 1383 ADSP_eCallSpeakerStatus 0 "NOT_RUN_YET" 1 "PASSED" 2 "FAILED_DISCONNECT" 3 "FAILED_DIAG" ;
VAL_ 1383 ADSP_eCallMicrophoneStatus 0 "NOT_RUN_YET" 1 "PASSED" 2 "FAILED" ;
VAL_ 1383 ADSP_eCallState 0 "INACTIVE" 1 "ACTIVE" ;
VAL_ 1383 ADSP_eCallSelfTest 0 "NOT_RUN_YET" 1 "PASSED" 2 "FAILED" ;
VAL_ 1383 ADSP_eCall_ENS_state 0 "UNKOWN" 1 "SIGNAL_ERROR" 2 "SOURCE_MISSING" 3 "SOURCE_ERROR" 4 "EMERGENCY" 5 "NORMAL" ;
VAL_ 1383 ADSP_ancMode 0 "OFF" 1 "FRONT" 2 "REAR" 3 "ALL" 4 "CALIBRATING_00" 5 "DISABLED_REASON_A2BA" 6 "DISABLED_REASON_A2BB" 7 "DISABLED_REASON_CLOSURE_OPEN" 8 "DISABLED_REASON_HVAC" 9 "DISABLED_REASON_SEAT_MOVING" 10 "DISABLED_REASON_REAR_OCCUPANT" 11 "DISABLED_REASON_WINDOW_OPEN" 12 "CALIBRATING_20" 13 "CALIBRATING_40" 14 "CALIBRATING_60" 15 "CALIBRATING_80" 16 "UNKNOWN" ;
VAL_ 1383 ADSP_tunerSelect 0 "FM" 1 "XM" ;
VAL_ 1383 ADSP_sourceSelect 0 "MEDIA" 1 "A2DP" 2 "TUNER" 3 "SINE" 4 "PINK" ;
VAL_ 1383 ADSP_ancState 0 "INIT" 1 "DSP_OFF" 2 "DSP_ON" 3 "ENABLED" ;
VAL_ 1383 ADSP_baseamp2State 0 "INIT" 1 "CONFIGURED" 2 "ENABLED" 3 "HALT" 4 "TURN_OFF" 5 "OFF" 6 "DIAG" ;
VAL_ 1383 ADSP_baseamp1State 0 "INIT" 1 "CONFIGURED" 2 "ENABLED" 3 "HALT" 4 "TURN_OFF" 5 "OFF" 6 "DIAG" ;
VAL_ 1383 ADSP_baseamp0State 0 "INIT" 1 "CONFIGURED" 2 "ENABLED" 3 "HALT" 4 "TURN_OFF" 5 "OFF" 6 "DIAG" ;
VAL_ 1383 ADSP_a2bbState 0 "INIT" 1 "DOWN" 2 "RESTART" 3 "DISCOVER" 4 "DISCOVER_WAIT" 5 "IDLE" 6 "DIAG" 7 "DISCOVER_RETRY" 8 "GOING_DOWN" ;
VAL_ 1383 ADSP_a2baState 0 "INIT" 1 "DOWN" 2 "RESTART" 3 "DISCOVER" 4 "DISCOVER_WAIT" 5 "IDLE" 6 "DIAG" 7 "DISCOVER_RETRY" 8 "GOING_DOWN" ;
VAL_ 1429 OCS1P_alertState 0 "CLEARED" 1 "SET" ;
VAL_ 1429 OCS1P_alertID 0 "ALERT_DO_NOT_USE_ZERO" 1 "a001_DriverDoorOpen" 2 "a002_DoorOpen" 3 "a003_TrunkOpen" 4 "a004_FrunkOpen" 5 "a005_HeadlightsOnDoorOpen" 6 "a006_RemoteServiceAlert" 7 "a007_SoftPackConfigMismatch" 8 "a008_TouchScreenError" 9 "a009_SquashfsError" 10 "a010_MapsMissing" 11 "a011_IncorrectMap" 12 "a012_NotOnPrivateProperty" 13 "a013_TPMSHardWarning" 14 "a014_TPMSSoftWarning" 15 "a015_TPMSOverPressureWarning" 16 "a016_TPMSTemperatureWarning" 17 "a017_TPMSSystemFault" 18 "a018_SlipStartOn" 19 "a019_ParkBrakeFault" 20 "a020_SteeringReduced" 21 "a021_RearSeatbeltUnbuckled" 22 "a022_ApeFusesEtc" 23 "a023_CellInternetCheckFailed" 24 "a024_WifiInternetCheckFailed" 25 "a025_WifiOnlineCheckFailed" 26 "a026_ModemResetLoopDetected" 27 "a027_AutoSteerMIA" 28 "a028_FrontTrunkPopupClosed" 29 "a029_ModemMIA" 30 "a030_ModemVMCrash" 31 "a031_BrakeFluidLow" 32 "a032_CellModemRecoveryResets" 33 "a033_ApTrialExpired" 34 "a034_WakeupProblem" 35 "a035_AudioWatchdogKernelError" 36 "a036_AudioWatchdogHfpError" 37 "a037_AudioWatchdogXrunStormError" 38 "a038_AudioWatchdogA2bI2cLockupError" 39 "a039_AudioA2bNeedRediscovery" 40 "a040_HomelinkTransmit" 41 "a041_AudioDmesgXrun" 42 "a042_AudioDmesgRtThrottling" 43 "a043_InvalidMapDataOverride" 44 "a044_AudioDmesgDspException" 45 "a045_ECallNeedsService" 46 "a046_BackupCameraStreamError" 47 "a047_CellRoamingDisallowed" 48 "a048_AudioPremiumAmpCheckFailed" 49 "a049_BrakeShiftRequired" 50 "a050_BackupCameraIPUTimeout" 51 "a051_BackupCameraFrameTimeout" 52 "a052_KernelPanicReported" 53 "a053_QtCarExitError" 54 "a054_AudioBoostPowerBad" 55 "a055_ManualECallDisabled" 56 "a056_ManualECallButtonDisconnected" 57 "a057_CellAntennaDisconnected" 58 "a058_GPSAntennaDisconnected" 59 "a059_ECallSpeakerDisconnected" 60 "a060_ECallMicDisconnected" 61 "a061_SIMTestFailed" 62 "a062_ENSTestFailed" 63 "a063_CellularTestFailed" 64 "a064_ModemFirmwareTestFailed" 65 "a065_WiFiRecoveryReset" 66 "a066_GpuHangDetected" 67 "a067_WarnOnI915" 68 "a068_VideoUnexpectedExit" 69 "a069_VideoUDPTimeout" 70 "a070_VideoPipelineWarning" 71 "a071_VideoPipelineError" 72 "a072_ECallAnalogMicFailed" 73 "a073_ECallDigitalMicFailed" 74 "a074_EMMCHangDetected" 75 "a075_BackupCameraInitError" 76 "a076_NumFalseManualECalls" 77 "a077_AudioA2bMicChannelSwap" 78 "a078_DashcamUsbDriveUnmountable" 79 "a079_DashcamUsbDriveFull" 80 "a080_DashcamUsbDriveSlow" 81 "a081_CellModemSearchExpired" 82 "a082_NumModemRebootStuckInECall" 83 "a083_ECallProxyWatchdogTriggered" 84 "a084_SerializerError" 85 "a085_DeserializerError" 86 "a086_TouchEnumerationError" 87 "a087_BmpReset" 88 "a088_CellRemovableSimMissing" 89 "a089_RadioSoftResetError" 90 "a090_RadioPingFailError" 91 "a091_VehicleLinkStall" 92 "a092_updateStarted" 93 "a093_updateEnded" 94 "a094_ModemPowerOnFailure" 95 "a095_CidStorageRunningLow" 96 "a096_VideodPipelineIssueDetected" 97 "a097_AudiodRestarted" 98 "a098_DiskCheckFailure" 99 "a099_eMMCStatusError" 100 "a100_eMMCFTLError" 101 "a101_wifiStackProblem" 102 "a102_A2bDiscoveryFailed" 103 "a103_UsbHubNotEnumerating" 104 "a104_DashcamUsbDriveMissing" 105 "a105_firmwareReinstallRequested" 106 "a106_rebootBackstopTriggered" 107 "a107_DashcamUsbDriveTooBigForVfatFsck" 108 "a108_DashcamUsbDriveGettingFull" 109 "a109_DashcamUsbDriveTooSmall" 110 "a110_DashcamUsbDriveCorrupt" 111 "a111_DashcamUsbDriveWrongPort" 112 "a112_badUSBDevice" 113 "a113_DashcamHasOnboardSentryClips" ;
VAL_ 1469 IBST_alertState 0 "CLEARED" 1 "SET" ;
VAL_ 1469 IBST_alertID 0 "ALERT_DO_NOT_USE_ZERO" 1 "a001_DriverDoorOpen" 2 "a002_DoorOpen" 3 "a003_TrunkOpen" 4 "a004_FrunkOpen" 5 "a005_HeadlightsOnDoorOpen" 6 "a006_RemoteServiceAlert" 7 "a007_SoftPackConfigMismatch" 8 "a008_TouchScreenError" 9 "a009_SquashfsError" 10 "a010_MapsMissing" 11 "a011_IncorrectMap" 12 "a012_NotOnPrivateProperty" 13 "a013_TPMSHardWarning" 14 "a014_TPMSSoftWarning" 15 "a015_TPMSOverPressureWarning" 16 "a016_TPMSTemperatureWarning" 17 "a017_TPMSSystemFault" 18 "a018_SlipStartOn" 19 "a019_ParkBrakeFault" 20 "a020_SteeringReduced" 21 "a021_RearSeatbeltUnbuckled" 22 "a022_ApeFusesEtc" 23 "a023_CellInternetCheckFailed" 24 "a024_WifiInternetCheckFailed" 25 "a025_WifiOnlineCheckFailed" 26 "a026_ModemResetLoopDetected" 27 "a027_AutoSteerMIA" 28 "a028_FrontTrunkPopupClosed" 29 "a029_ModemMIA" 30 "a030_ModemVMCrash" 31 "a031_BrakeFluidLow" 32 "a032_CellModemRecoveryResets" 33 "a033_ApTrialExpired" 34 "a034_WakeupProblem" 35 "a035_AudioWatchdogKernelError" 36 "a036_AudioWatchdogHfpError" 37 "a037_AudioWatchdogXrunStormError" 38 "a038_AudioWatchdogA2bI2cLockupError" 39 "a039_AudioA2bNeedRediscovery" 40 "a040_HomelinkTransmit" 41 "a041_AudioDmesgXrun" 42 "a042_AudioDmesgRtThrottling" 43 "a043_InvalidMapDataOverride" 44 "a044_AudioDmesgDspException" 45 "a045_ECallNeedsService" 46 "a046_BackupCameraStreamError" 47 "a047_CellRoamingDisallowed" 48 "a048_AudioPremiumAmpCheckFailed" 49 "a049_BrakeShiftRequired" 50 "a050_BackupCameraIPUTimeout" 51 "a051_BackupCameraFrameTimeout" 52 "a052_KernelPanicReported" 53 "a053_QtCarExitError" 54 "a054_AudioBoostPowerBad" 55 "a055_ManualECallDisabled" 56 "a056_ManualECallButtonDisconnected" 57 "a057_CellAntennaDisconnected" 58 "a058_GPSAntennaDisconnected" 59 "a059_ECallSpeakerDisconnected" 60 "a060_ECallMicDisconnected" 61 "a061_SIMTestFailed" 62 "a062_ENSTestFailed" 63 "a063_CellularTestFailed" 64 "a064_ModemFirmwareTestFailed" 65 "a065_WiFiRecoveryReset" 66 "a066_GpuHangDetected" 67 "a067_WarnOnI915" 68 "a068_VideoUnexpectedExit" 69 "a069_VideoUDPTimeout" 70 "a070_VideoPipelineWarning" 71 "a071_VideoPipelineError" 72 "a072_ECallAnalogMicFailed" 73 "a073_ECallDigitalMicFailed" 74 "a074_EMMCHangDetected" 75 "a075_BackupCameraInitError" 76 "a076_NumFalseManualECalls" 77 "a077_AudioA2bMicChannelSwap" 78 "a078_DashcamUsbDriveUnmountable" 79 "a079_DashcamUsbDriveFull" 80 "a080_DashcamUsbDriveSlow" 81 "a081_CellModemSearchExpired" 82 "a082_NumModemRebootStuckInECall" 83 "a083_ECallProxyWatchdogTriggered" 84 "a084_SerializerError" 85 "a085_DeserializerError" 86 "a086_TouchEnumerationError" 87 "a087_BmpReset" 88 "a088_CellRemovableSimMissing" 89 "a089_RadioSoftResetError" 90 "a090_RadioPingFailError" 91 "a091_VehicleLinkStall" 92 "a092_updateStarted" 93 "a093_updateEnded" 94 "a094_ModemPowerOnFailure" 95 "a095_CidStorageRunningLow" 96 "a096_VideodPipelineIssueDetected" 97 "a097_AudiodRestarted" 98 "a098_DiskCheckFailure" 99 "a099_eMMCStatusError" 100 "a100_eMMCFTLError" 101 "a101_wifiStackProblem" 102 "a102_A2bDiscoveryFailed" 103 "a103_UsbHubNotEnumerating" 104 "a104_DashcamUsbDriveMissing" 105 "a105_firmwareReinstallRequested" 106 "a106_rebootBackstopTriggered" 107 "a107_DashcamUsbDriveTooBigForVfatFsck" 108 "a108_DashcamUsbDriveGettingFull" 109 "a109_DashcamUsbDriveTooSmall" 110 "a110_DashcamUsbDriveCorrupt" 111 "a111_DashcamUsbDriveWrongPort" 112 "a112_badUSBDevice" 113 "a113_DashcamHasOnboardSentryClips" ;
VAL_ 1497 DAS_closestInLaneTargetVxRel 0 "NO_TARGET" ;
VAL_ 1497 DAS_radarTarget4_dx 0 "NO_TARGET" ;
VAL_ 1497 DAS_closestRightLaneTargetDx 0 "NO_TARGET" ;
VAL_ 1497 DAS_radarTarget1_VxRel 0 "NO_TARGET" ;
VAL_ 1497 DAS_radarTarget3_dx 0 "NO_TARGET" ;
VAL_ 1497 DAS_closestLeftLaneTargetDx 0 "NO_TARGET" ;
VAL_ 1497 DAS_radarTarget1_dx 0 "NO_TARGET" ;
VAL_ 1497 DAS_radarTarget2_dx 0 "NO_TARGET" ;
VAL_ 1497 DAS_desiredTarget_dx 255 "SNA" ;
VAL_ 1497 DAS_secondInLaneTargetDx 0 "NO_TARGET" ;
VAL_ 1497 DAS_closestInLaneTargetDx 0 "NO_TARGET" ;
VAL_ 1497 DAS_radarTarget5_dx 0 "NO_TARGET" ;
VAL_ 1497 DAS_carLogMultiplexer 0 "FEATURE_STATE" 1 "RADAR" 2 "FCM" 3 "PROFILER" ;
